VERSION "HNNBNNNYNNNNNNNNNNNNNNNNNNNNNNNNNNNNNNNNNN/4/%%%/4/'%**4NNN///"

NS_ :

BS_:

BU_: BAP_Tester Gateway_Max Getriebe_DQ Motor_konv Parksperre Schaltbetaetigung

BO_ 333 ACC_18: 32 Gateway_Max
 SG_ ACC_18_CRC : 0|8@1+ (1,0) [0|255] ""  Motor_konv
 SG_ ACC_18_BZ : 8|4@1+ (1,0) [0|15] ""  Motor_konv
 SG_ ACC_limitierte_Anfahrdyn : 12|1@1+ (1.0,0.0) [0.0|1] ""  Motor_konv
 SG_ ACC_nachtr_Stopp_Anf : 13|1@1+ (1.0,0.0) [0.0|1] ""  Motor_konv
 SG_ ACC_DynErhoehung : 14|1@1+ (1.0,0.0) [0.0|1] ""  Motor_konv
 SG_ ACC_Freilaufstrategie_TSK : 15|1@1+ (1.0,0.0) [0.0|1] ""  Motor_konv
 SG_ ACC_zul_Regelabw_unten : 16|6@1+ (0.024,0) [0.000|1.512] "Unit_MeterPerSeconSquar"  Motor_konv
 SG_ ACC_StartStopp_Info : 22|2@1+ (1.0,0.0) [0.0|3] ""  Motor_konv
 SG_ ACC_Sollbeschleunigung_02 : 24|11@1+ (0.005,-7.22) [-7.220|3.005] "Unit_MeterPerSeconSquar"  Getriebe_DQ,Motor_konv
 SG_ ACC_zul_Regelabw_oben : 35|5@1+ (0.0625,0) [0.0000|1.9375] "Unit_MeterPerSeconSquar"  Motor_konv
 SG_ ACC_neg_Sollbeschl_Grad_02 : 40|8@1+ (0.05,0) [0.00|12.75] "Unit_MeterPerCubicSecon"  Motor_konv
 SG_ ACC_pos_Sollbeschl_Grad_02 : 48|8@1+ (0.05,0) [0.00|12.75] "Unit_MeterPerCubicSecon"  Motor_konv
 SG_ ACC_Anfahren : 56|1@1+ (1.0,0.0) [0.0|1] ""  Getriebe_DQ,Motor_konv
 SG_ ACC_Anhalten : 57|1@1+ (1.0,0.0) [0.0|1] ""  Getriebe_DQ,Motor_konv
 SG_ ACC_Typ : 58|2@1+ (1.0,0.0) [0.0|3] ""  Motor_konv
 SG_ ACC_Status_ACC : 60|3@1+ (1.0,0.0) [0.0|7] ""  Getriebe_DQ,Motor_konv
 SG_ ACC_Minimale_Bremsung : 63|1@1+ (1.0,0.0) [0.0|1] ""  Motor_konv
 SG_ ACC_Anhalteweg : 64|11@1+ (0.01,0) [0.00|20.45] "Unit_Meter"  Vector__XXX
 SG_ ACC_Boost : 75|1@1+ (1.0,0.0) [0.0|1] ""  Vector__XXX
 SG_ ACC_Freilauf_Anf : 76|1@1+ (1.0,0.0) [0.0|1] ""  Vector__XXX
 SG_ ACC_Anforderung_HMS : 77|3@1+ (1.0,0.0) [0.0|7] ""  Vector__XXX
 SG_ ACC_Folgebeschl : 80|8@1+ (0.03,-4.6) [-4.60|2.99] "Unit_MeterPerSeconSquar"  Motor_konv
 SG_ ACC_Freilauf_Info : 88|2@1+ (1.0,0.0) [0.0|3] ""  Motor_konv
 SG_ ACC_Tempolimitassistent_Ein : 90|1@1+ (1.0,0.0) [0.0|1] ""  Vector__XXX
 SG_ ACC_FoD_Status : 91|2@1+ (1.0,0.0) [0.0|3] ""  Motor_konv
 SG_ ACC_Blindheit_erkannt : 93|1@1+ (1.0,0.0) [0.0|1] ""  Motor_konv
 SG_ ACC_Verkehrssinn : 94|2@1+ (1.0,0.0) [0.0|3] ""  Vector__XXX
 SG_ ACC_relev_Nichtverfuegbarkeit : 96|1@1+ (1.0,0.0) [0.0|1] ""  Motor_konv
 SG_ ACC_relevanter_Fehler : 97|1@1+ (1.0,0.0) [0.0|1] ""  Motor_konv
 SG_ ACC_TA_Kurve_Abstand : 98|6@1+ (5,0) [0|300] "Unit_Meter"  Vector__XXX
 SG_ ACC_TA_Kurve_vDelta : 104|4@1+ (5,0) [0|50] "Unit_KiloMeterPerHour"  Vector__XXX
 SG_ RDR_VBEG_Anforderung : 108|5@1+ (1,4) [5|35] "Unit_KiloMeterPerHour"  Motor_konv
 SG_ ACC_Abbiegewunsch : 113|2@1+ (1.0,0.0) [0.0|3] ""  Vector__XXX
 SG_ ACC_Abbiegewunsch_Abstand : 115|9@1+ (1,0) [0|510] "Unit_Meter"  Vector__XXX
 SG_ MPPmod_1_Segment : 208|6@1+ (1,0) [2|63] ""  Motor_konv
 SG_ MPPmod_2_Segment : 214|6@1+ (1,0) [2|63] ""  Motor_konv
 SG_ MPPmod_3_Segment : 220|6@1+ (1,0) [2|63] ""  Motor_konv
 SG_ MPPmod_4_Segment : 226|6@1+ (1,0) [2|63] ""  Motor_konv
 SG_ vESC_Verz_Anf : 232|4@1+ (0.5,0) [0.0|3.5] "Unit_MeterPerSeconSquar"  Vector__XXX
 SG_ RDR_v_ueber_Grund : 236|12@1+ (0.1,0) [0.0|409.0] "Unit_KiloMeterPerHour"  Vector__XXX
 SG_ RDR_v_ueber_Grund_Genauigkeit : 248|6@1+ (0.1,0) [0.0|6.0] "Unit_KiloMeterPerHour"  Vector__XXX
 SG_ RDR_v_ueber_Grund_Fahrtrichtung : 254|2@1+ (1.0,0.0) [0.0|3] ""  Vector__XXX

BO_ 859 ACC_Obj_01: 64 Gateway_Max
 SG_ ACC_Obj_01_ID : 12|8@1+ (1,0) [1|254] "Unit_None"  Vector__XXX
 SG_ ACC_Obj_01_ax_StdA : 20|6@1+ (0.125,0) [0.000|7.750] "Unit_MeterPerSeconSquar"  Motor_konv
 SG_ ACC_Obj_01_ax_v : 26|8@1+ (0.125,-16) [-16.000|15.750] "Unit_MeterPerSeconSquar"  Motor_konv
 SG_ ACC_Obj_01_dx_StdA : 34|7@1+ (0.0625,0) [0.0000|7.8750] "Unit_Meter"  Vector__XXX
 SG_ ACC_Obj_01_dx_v : 41|12@1+ (0.0625,0) [0.0000|255.8750] "Unit_Meter"  Motor_konv
 SG_ ACC_Obj_01_dy_StdA : 53|7@1+ (0.0625,0) [0.0000|7.8750] "Unit_Meter"  Motor_konv
 SG_ ACC_Obj_01_dy_v : 60|11@1+ (0.0625,-64) [-64.0000|63.8750] "Unit_Meter"  Motor_konv
 SG_ ACC_Obj_01_vx_StdA : 71|5@1+ (0.25,0) [0.00|7.50] "Unit_MeterPerSecon"  Vector__XXX
 SG_ ACC_Obj_01_vx_v : 76|10@1+ (0.25,-128) [-128.00|127.50] "Unit_MeterPerSecon"  Motor_konv
 SG_ ACC_Obj_01_Bew_Zustand : 86|2@1+ (1.0,0.0) [0.0|3] ""  Vector__XXX
 SG_ ACC_Obj_01_Fusion_ID_VD : 88|32@1+ (1,0) [1|4294967294] "Unit_Ohm"  Vector__XXX
 SG_ ACC_Obj_01_Fusion_ID_FER_VR : 120|8@1+ (1,0) [1|254] "Unit_None"  Vector__XXX
 SG_ ACC_Obj_01_Fusion_ID_FER_VL : 128|8@1+ (1,0) [1|254] "Unit_None"  Vector__XXX
 SG_ ACC_Obj_01_Alter : 136|12@1+ (1,0) [0|4094] "Unit_None"  Vector__XXX
 SG_ ACC_Obj_01_vxAbs_v : 148|12@1+ (0.0625,-128) [-128.0000|127.8750] "Unit_MeterPerSecon"  Vector__XXX
 SG_ ACC_Obj_01_vyAbs_v : 160|12@1+ (0.0625,-128) [-128.0000|127.8750] "Unit_MeterPerSecon"  Vector__XXX
 SG_ ACC_Obj_01_Bezugspunkt : 172|4@1+ (1.0,0.0) [0.0|15] ""  Vector__XXX
 SG_ ACC_Obj_01_Breite : 176|7@1+ (0.0625,0) [0.0000|7.8750] "Unit_Meter"  Vector__XXX
 SG_ ACC_Obj_01_SDFInfo_FER_VL : 183|1@1+ (1.0,0.0) [0.0|1] ""  Vector__XXX
 SG_ ACC_Obj_01_BreiteStdA : 184|7@1+ (0.0625,0) [0.0000|7.8750] "Unit_Meter"  Vector__XXX
 SG_ ACC_Obj_01_SDFInfo_FER_VR : 191|1@1+ (1.0,0.0) [0.0|1] ""  Vector__XXX
 SG_ ACC_Obj_01_Historie : 192|1@1+ (1.0,0.0) [0.0|1] ""  Vector__XXX
 SG_ ACC_Obj_01_SDFInfo_FR : 193|1@1+ (1.0,0.0) [0.0|1] ""  Vector__XXX
 SG_ ACC_Obj_01_SDFInfo_Kamera : 194|1@1+ (1.0,0.0) [0.0|1] ""  Vector__XXX
 SG_ ACC_Obj_01_vy_StdA : 195|5@1+ (0.25,0) [0.00|7.50] "Unit_MeterPerSecon"  Vector__XXX
 SG_ ACC_Obj_01_dz_v : 200|9@1+ (0.0625,-16) [-16.0000|15.8750] "Unit_Meter"  Vector__XXX
 SG_ ACC_Obj_01_dz_StdA : 209|7@1+ (0.0625,0) [0.0000|7.8750] "Unit_Meter"  Vector__XXX
 SG_ ACC_Obj_01_Laenge : 216|9@1+ (0.0625,0) [0.0000|31.8750] "Unit_Meter"  Vector__XXX
 SG_ ACC_Obj_01_LaengeStdA : 225|7@1+ (0.0625,0) [0.0000|7.8750] "Unit_Meter"  Vector__XXX
 SG_ ACC_Obj_01_GierWnkl : 232|9@1+ (0.0125,-3.2) [-3.2000|3.1750] "Unit_Radia"  Vector__XXX
 SG_ ACC_Obj_01_ExistenzMass : 241|7@1+ (0.0078125,0.015625) [0.0156250|1.0000000] "Unit_None"  Vector__XXX
 SG_ ACC_Obj_01_axAbs_v : 248|8@1+ (0.125,-16) [-16.000|15.750] "Unit_MeterPerSeconSquar"  Vector__XXX
 SG_ ACC_Obj_01_ay_v : 256|8@1+ (0.125,-16) [-16.000|15.750] "Unit_MeterPerSeconSquar"  Vector__XXX
 SG_ ACC_Obj_01_vy_v : 264|8@1+ (0.25,-32) [-32.00|31.50] "Unit_MeterPerSecon"  Vector__XXX
 SG_ ACC_Obj_01_Klasse : 272|4@1+ (1.0,0.0) [0.0|15] ""  Vector__XXX
 SG_ ACC_Obj_01_KlassePlausib : 276|4@1+ (0.071429,0) [0.000000|1.000006] "Unit_None"  Vector__XXX
 SG_ ACC_Obj_01_Gemessen : 280|2@1+ (1.0,0.0) [0.0|3] ""  Vector__XXX
 SG_ ACC_Obj_01_Hoehe : 282|6@1+ (0.0625,0) [0.0000|3.8750] "Unit_Meter"  Vector__XXX
 SG_ ACC_Obj_01_HoeheStdA : 288|6@1+ (0.0625,0) [0.0000|3.8750] "Unit_Meter"  Vector__XXX
 SG_ ACC_Obj_01_vxAbs_StdA : 294|6@1+ (0.0625,0) [0.0000|3.8750] "Unit_MeterPerSecon"  Vector__XXX
 SG_ ACC_Obj_01_vyAbs_StdA : 300|6@1+ (0.0625,0) [0.0000|3.8750] "Unit_MeterPerSecon"  Vector__XXX
 SG_ ACC_Obj_01_axAbs_StdA : 306|6@1+ (0.125,0) [0.000|7.750] "Unit_MeterPerSeconSquar"  Vector__XXX
 SG_ ACC_Obj_01_ay_StdA : 312|6@1+ (0.125,0) [0.000|7.750] "Unit_MeterPerSeconSquar"  Vector__XXX
 SG_ ACC_Obj_01_GierWnklStdA : 318|6@1+ (0.0625,0) [0.0000|3.8750] "Unit_Radia"  Vector__XXX
 SG_ ACC_Obj_01_Anzeige_Rel : 324|2@1+ (1.0,0.0) [0.0|3] ""  Vector__XXX
 SG_ ACC_Obj_01_LaengsRegelung : 326|1@1+ (1.0,0.0) [0.0|1] ""  Vector__XXX

BO_ 860 ACC_Obj_04: 64 Gateway_Max
 SG_ ACC_Obj_04_ID : 12|8@1+ (1,0) [1|254] "Unit_None"  Vector__XXX
 SG_ ACC_Obj_04_ax_StdA : 20|6@1+ (0.125,0) [0.000|7.750] ""  Vector__XXX
 SG_ ACC_Obj_04_ax_v : 26|8@1+ (0.125,-16) [-16.000|15.750] ""  Vector__XXX
 SG_ ACC_Obj_04_dx_StdA : 34|7@1+ (0.0625,0) [0.0000|7.8750] "Unit_Meter"  Vector__XXX
 SG_ ACC_Obj_04_dx_v : 41|12@1+ (0.0625,0) [0.0000|255.8750] "Unit_Meter"  Motor_konv
 SG_ ACC_Obj_04_dy_StdA : 53|7@1+ (0.0625,0) [0.0000|7.8750] "Unit_Meter"  Vector__XXX
 SG_ ACC_Obj_04_dy_v : 60|11@1+ (0.0625,-64) [-64.0000|63.8750] "Unit_Meter"  Vector__XXX
 SG_ ACC_Obj_04_vx_StdA : 71|5@1+ (0.25,0) [0.00|7.50] "Unit_MeterPerSecon"  Vector__XXX
 SG_ ACC_Obj_04_vx_v : 76|10@1+ (0.25,-128) [-128.00|127.50] "Unit_MeterPerSecon"  Motor_konv
 SG_ ACC_Obj_04_Bew_Zustand : 86|2@1+ (1.0,0.0) [0.0|3] ""  Vector__XXX
 SG_ ACC_Obj_04_Fusion_ID_VD : 88|32@1+ (1,0) [1|4294967294] ""  Vector__XXX
 SG_ ACC_Obj_04_Fusion_ID_FER_VR : 120|8@1+ (1,0) [1|254] ""  Vector__XXX
 SG_ ACC_Obj_04_Fusion_ID_FER_VL : 128|8@1+ (1,0) [1|254] ""  Vector__XXX
 SG_ ACC_Obj_04_Alter : 136|12@1+ (1,0) [0|4094] ""  Vector__XXX
 SG_ ACC_Obj_04_vxAbs_v : 148|12@1+ (0.0625,-128) [-128.0000|127.8750] ""  Vector__XXX
 SG_ ACC_Obj_04_vyAbs_v : 160|12@1+ (0.0625,-128) [-128.0000|127.8750] ""  Vector__XXX
 SG_ ACC_Obj_04_Bezugspunkt : 172|4@1+ (1.0,0.0) [0.0|15] ""  Vector__XXX
 SG_ ACC_Obj_04_Breite : 176|7@1+ (0.0625,0) [0.0000|7.8750] ""  Vector__XXX
 SG_ ACC_Obj_04_SDFInfo_FER_VL : 183|1@1+ (1.0,0.0) [0.0|1] ""  Vector__XXX
 SG_ ACC_Obj_04_BreiteStdA : 184|7@1+ (0.0625,0) [0.0000|7.8750] ""  Vector__XXX
 SG_ ACC_Obj_04_SDFInfo_FER_VR : 191|1@1+ (1.0,0.0) [0.0|1] ""  Vector__XXX
 SG_ ACC_Obj_04_Historie : 192|1@1+ (1.0,0.0) [0.0|1] ""  Vector__XXX
 SG_ ACC_Obj_04_SDFInfo_FR : 193|1@1+ (1.0,0.0) [0.0|1] ""  Vector__XXX
 SG_ ACC_Obj_04_SDFInfo_Kamera : 194|1@1+ (1.0,0.0) [0.0|1] ""  Vector__XXX
 SG_ ACC_Obj_04_vy_StdA : 195|5@1+ (0.25,0) [0.00|7.50] ""  Vector__XXX
 SG_ ACC_Obj_04_dz_v : 200|9@1+ (0.0625,-16) [-16.0000|15.8750] ""  Vector__XXX
 SG_ ACC_Obj_04_dz_StdA : 209|7@1+ (0.0625,0) [0.0000|7.8750] ""  Vector__XXX
 SG_ ACC_Obj_04_Laenge : 216|9@1+ (0.0625,0) [0.0000|31.8750] ""  Vector__XXX
 SG_ ACC_Obj_04_LaengeStdA : 225|7@1+ (0.0625,0) [0.0000|7.8750] ""  Vector__XXX
 SG_ ACC_Obj_04_GierWnkl : 232|9@1+ (0.0125,-3.2) [-3.2000|3.1750] ""  Vector__XXX
 SG_ ACC_Obj_04_ExistenzMass : 241|7@1+ (0.0078125,0.015625) [0.0156250|1.0000000] ""  Vector__XXX
 SG_ ACC_Obj_04_axAbs_v : 248|8@1+ (0.125,-16) [-16.000|15.750] "Unit_MeterPerSeconSquar"  Vector__XXX
 SG_ ACC_Obj_04_ay_v : 256|8@1+ (0.125,-16) [-16.000|15.750] ""  Vector__XXX
 SG_ ACC_Obj_04_vy_v : 264|8@1+ (0.25,-32) [-32.00|31.50] ""  Vector__XXX
 SG_ ACC_Obj_04_Klasse : 272|4@1+ (1.0,0.0) [0.0|15] ""  Vector__XXX
 SG_ ACC_Obj_04_KlassePlausib : 276|4@1+ (0.071429,0) [0.000000|1.000006] "Unit_None"  Vector__XXX
 SG_ ACC_Obj_04_Gemessen : 280|2@1+ (1.0,0.0) [0.0|3] ""  Vector__XXX
 SG_ ACC_Obj_04_Hoehe : 282|6@1+ (0.0625,0) [0.0000|3.8750] ""  Vector__XXX
 SG_ ACC_Obj_04_HoeheStdA : 288|6@1+ (0.0625,0) [0.0000|3.8750] ""  Vector__XXX
 SG_ ACC_Obj_04_vxAbs_StdA : 294|6@1+ (0.0625,0) [0.0000|3.8750] ""  Vector__XXX
 SG_ ACC_Obj_04_vyAbs_StdA : 300|6@1+ (0.0625,0) [0.0000|3.8750] ""  Vector__XXX
 SG_ ACC_Obj_04_axAbs_StdA : 306|6@1+ (0.125,0) [0.000|7.750] "Unit_MeterPerSeconSquar"  Vector__XXX
 SG_ ACC_Obj_04_ay_StdA : 312|6@1+ (0.125,0) [0.000|7.750] ""  Vector__XXX
 SG_ ACC_Obj_04_GierWnklStdA : 318|6@1+ (0.0625,0) [0.0000|3.8750] ""  Vector__XXX
 SG_ ACC_Obj_04_Anzeige_Rel : 324|2@1+ (1.0,0.0) [0.0|3] ""  Vector__XXX
 SG_ ACC_Obj_04_LaengsRegelung : 326|1@1+ (1.0,0.0) [0.0|1] ""  Vector__XXX

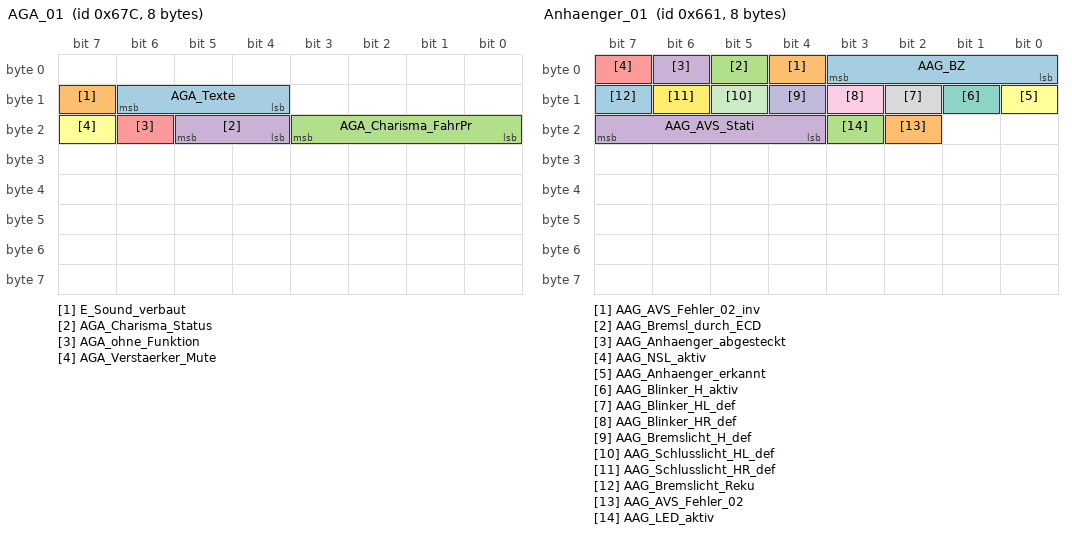
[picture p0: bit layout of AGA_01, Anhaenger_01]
BO_ 1660 AGA_01: 8 Vector__XXX
 SG_ AGA_Texte : 12|3@1+ (1.0,0.0) [0.0|7] ""  Gateway_Max
 SG_ E_Sound_verbaut : 15|1@1+ (1.0,0.0) [0.0|1] ""  Gateway_Max
 SG_ AGA_Charisma_FahrPr : 16|4@1+ (1.0,0.0) [0.0|15] ""  Gateway_Max
 SG_ AGA_Charisma_Status : 20|2@1+ (1.0,0.0) [0.0|3] ""  Gateway_Max
 SG_ AGA_ohne_Funktion : 22|1@1+ (1.0,0.0) [0.0|1] ""  Gateway_Max
 SG_ AGA_Verstaerker_Mute : 23|1@1+ (1.0,0.0) [0.0|1] ""  Gateway_Max

BO_ 64 Airbag_01: 8 Gateway_Max
 SG_ Airbag_01_CRC : 0|8@1+ (1,0) [0|255] ""  Motor_konv
 SG_ Airbag_01_BZ : 8|4@1+ (1,0) [0|15] ""  Motor_konv
 SG_ AB_RGS_Anst : 12|4@1+ (1.0,0.0) [0.0|15] ""  Vector__XXX
 SG_ AB_Front_Crash : 16|1@1+ (1.0,0.0) [0.0|1] ""  Vector__XXX
 SG_ AB_Heck_Crash : 17|1@1+ (1.0,0.0) [0.0|1] ""  Vector__XXX
 SG_ AB_SF_Crash : 18|1@1+ (1.0,0.0) [0.0|1] ""  Vector__XXX
 SG_ AB_SB_Crash : 19|1@1+ (1.0,0.0) [0.0|1] ""  Vector__XXX
 SG_ AB_Rollover_Crash : 20|1@1+ (1.0,0.0) [0.0|1] ""  Vector__XXX
 SG_ AB_Crash_Int : 21|3@1+ (1.0,0.0) [0.0|7] ""  Getriebe_DQ,Motor_konv
 SG_ AB_Lampe : 24|1@1+ (1.0,0.0) [0.0|1] ""  Vector__XXX
 SG_ AB_Deaktiviert : 25|1@1+ (1.0,0.0) [0.0|1] ""  Vector__XXX
 SG_ AB_VB_deaktiviert : 26|1@1+ (1.0,0.0) [0.0|1] ""  Vector__XXX
 SG_ AB_Systemfehler : 27|1@1+ (1.0,0.0) [0.0|1] ""  Vector__XXX
 SG_ AB_Diagnose : 28|1@1+ (1.0,0.0) [0.0|1] ""  Vector__XXX
 SG_ AB_Stellgliedtest : 29|1@1+ (1.0,0.0) [0.0|1] ""  Motor_konv
 SG_ AB_Erh_Auf_VB : 30|2@1+ (1.0,0.0) [0.0|3] ""  Vector__XXX
 SG_ AB_Gurtwarn_VF : 32|1@1+ (1.0,0.0) [0.0|1] ""  Vector__XXX
 SG_ AB_Gurtwarn_VB : 33|1@1+ (1.0,0.0) [0.0|1] ""  Vector__XXX
 SG_ AB_Anzeige_Fussg : 34|2@1+ (1.0,0.0) [0.0|3] ""  Vector__XXX
 SG_ AB_Texte_AKS : 36|2@1+ (1.0,0.0) [0.0|3] ""  Vector__XXX
 SG_ AB_PAO_Leuchte_Anf : 38|1@1+ (1.0,0.0) [0.0|1] ""  Vector__XXX
 SG_ AB_MKB_gueltig : 39|1@1+ (1.0,0.0) [0.0|1] ""  Vector__XXX
 SG_ AB_MKB_Anforderung : 40|1@1+ (1.0,0.0) [0.0|1] ""  Vector__XXX
 SG_ AB_Versorgungsspannung : 41|1@1+ (1.0,0.0) [0.0|1] ""  Vector__XXX
 SG_ AB_Deaktivierung_HV : 42|3@1+ (1.0,0.0) [0.0|7] ""  Vector__XXX
 SG_ AB_EDR_Trigger : 45|2@1+ (1.0,0.0) [0.0|3] ""  Vector__XXX
 SG_ AB_Belegung_VF : 47|2@1+ (1.0,0.0) [0.0|3] ""  Vector__XXX
 SG_ AB_Gurtschloss_FA_ext : 49|3@1+ (1.0,0.0) [0.0|7] ""  Motor_konv
 SG_ AB_Gurtschloss_FA_ext_aktiv : 52|1@1+ (1.0,0.0) [0.0|1] ""  Vector__XXX
 SG_ AB_eCS_Error : 53|1@1+ (1.0,0.0) [0.0|1] ""  Vector__XXX
 SG_ ASM_Masterzeit_02 : 56|8@1+ (0.04,0) [0.00|10.16] "Unit_Secon"  Vector__XXX

BO_ 1312 Airbag_02: 8 Gateway_Max
 SG_ Airbag_02_CRC : 0|8@1+ (1,0) [0|255] ""  Motor_konv
 SG_ Airbag_02_BZ : 8|4@1+ (1,0) [0|15] ""  Motor_konv
 SG_ LoGeWa_Event_Kombiwarnung : 12|4@1+ (1.0,0.0) [0.0|15] ""  Vector__XXX
 SG_ AB_Anforderung_eCall : 16|1@1+ (1.0,0.0) [0.0|1] ""  Vector__XXX
 SG_ AB_Anprall_Seite_Beifahrer : 17|1@1+ (1.0,0.0) [0.0|1] ""  Vector__XXX
 SG_ AB_Anprall_Rollover : 18|1@1+ (1.0,0.0) [0.0|1] ""  Vector__XXX
 SG_ AB_Anprall_FGS : 19|1@1+ (1.0,0.0) [0.0|1] ""  Vector__XXX
 SG_ AB_Anprall_Front_Beifahrer : 20|1@1+ (1.0,0.0) [0.0|1] ""  Vector__XXX
 SG_ AB_Anprall_Front_Fahrer : 21|1@1+ (1.0,0.0) [0.0|1] ""  Vector__XXX
 SG_ AB_Anprall_Heck_Beifahrer : 22|1@1+ (1.0,0.0) [0.0|1] ""  Vector__XXX
 SG_ AB_Anprall_Heck_Fahrer : 23|1@1+ (1.0,0.0) [0.0|1] ""  Vector__XXX
 SG_ AB_Wickelklappung_Reihe2_MI : 24|2@1+ (1.0,0.0) [0.0|3] ""  Vector__XXX
 SG_ AB_Belegung_VB : 26|2@1+ (1.0,0.0) [0.0|3] ""  Vector__XXX
 SG_ AB_Abschaltanf_SIH_BF : 28|1@1+ (1.0,0.0) [0.0|1] ""  Vector__XXX
 SG_ AB_Anprall_Seite_Fahrer : 29|1@1+ (1.0,0.0) [0.0|1] ""  Vector__XXX
 SG_ SC_PAO_Schriftzug_Anf : 30|2@1+ (1.0,0.0) [0.0|3] ""  Vector__XXX
 SG_ SC_PAO_ON_Anf : 32|2@1+ (1.0,0.0) [0.0|3] ""  Vector__XXX
 SG_ SC_PAO_OFF_Anf : 34|2@1+ (1.0,0.0) [0.0|3] ""  Vector__XXX
 SG_ AB_Crashschwere : 36|3@1+ (1.0,0.0) [0.0|7] ""  Vector__XXX
 SG_ AB_Anforderung_USM : 39|1@1+ (1.0,0.0) [0.0|1] ""  Vector__XXX
 SG_ AB_Gurtschloss_FA : 40|2@1+ (1.0,0.0) [0.0|3] ""  Motor_konv
 SG_ AB_Gurtschloss_BF : 42|2@1+ (1.0,0.0) [0.0|3] ""  Vector__XXX
 SG_ AB_Gurtschloss_Reihe2_FA : 44|2@1+ (1.0,0.0) [0.0|3] ""  Vector__XXX
 SG_ AB_Gurtschloss_Reihe2_MI : 46|2@1+ (1.0,0.0) [0.0|3] ""  Vector__XXX
 SG_ AB_Gurtschloss_Reihe2_BF : 48|2@1+ (1.0,0.0) [0.0|3] ""  Vector__XXX
 SG_ AB_Gurtschloss_Reihe3_FA : 50|2@1+ (1.0,0.0) [0.0|3] ""  Vector__XXX
 SG_ AB_Gurtschloss_Reihe3_MI : 52|2@1+ (1.0,0.0) [0.0|3] ""  Vector__XXX
 SG_ AB_Gurtschloss_Reihe3_BF : 54|2@1+ (1.0,0.0) [0.0|3] ""  Vector__XXX
 SG_ AB_Sitzpos_Sens_FA : 56|2@1+ (1.0,0.0) [0.0|3] ""  Vector__XXX
 SG_ AB_Sitzpos_Sens_BF : 58|2@1+ (1.0,0.0) [0.0|3] ""  Vector__XXX
 SG_ AB_Wickelklappung_Reihe2_BF : 60|2@1+ (1.0,0.0) [0.0|3] ""  Vector__XXX
 SG_ AB_Wickelklappung_Reihe2_FA : 62|2@1+ (1.0,0.0) [0.0|3] ""  Vector__XXX

BO_ 1349 Airbag_04: 8 Gateway_Max
 SG_ Airbag_04_CRC : 0|8@1+ (1,0) [0|255] ""  Motor_konv
 SG_ Airbag_04_BZ : 8|4@1+ (1,0) [0|15] ""  Motor_konv
 SG_ AB_Anprall_Front : 12|1@1+ (1.0,0.0) [0.0|1] ""  Vector__XXX
 SG_ AB_Anprall_Heck : 13|1@1+ (1.0,0.0) [0.0|1] ""  Vector__XXX
 SG_ AB_Gurtwarn_Reihe4_FA : 14|2@1+ (1.0,0.0) [0.0|3] ""  Vector__XXX
 SG_ AB_Gurtwarn_Reihe4_BF : 16|2@1+ (1.0,0.0) [0.0|3] ""  Vector__XXX
 SG_ AB_Gurtwarn_Reihe4_MI : 18|2@1+ (1.0,0.0) [0.0|3] ""  Vector__XXX
 SG_ AB_Gurtwarn_Reihe2_FA : 20|2@1+ (1.0,0.0) [0.0|3] ""  Vector__XXX
 SG_ AB_Gurtwarn_Reihe2_BF : 22|2@1+ (1.0,0.0) [0.0|3] ""  Vector__XXX
 SG_ AbstWarn_MV_FAS_Fkt_Status : 24|2@1+ (1.0,0.0) [0.0|3] ""  Vector__XXX
 SG_ WarnBrems_Charisma_Status : 26|2@1+ (1.0,0.0) [0.0|3] ""  Vector__XXX
 SG_ WarnBrems_Charisma_FahrPr : 28|4@1+ (1.0,0.0) [0.0|15] ""  Vector__XXX
 SG_ AB_Gurtwarn_Reihe2_MI : 32|2@1+ (1.0,0.0) [0.0|3] ""  Vector__XXX
 SG_ AB_Gurtwarn_Reihe3_FA : 34|2@1+ (1.0,0.0) [0.0|3] ""  Vector__XXX
 SG_ AB_Gurtwarn_Reihe3_MI : 36|2@1+ (1.0,0.0) [0.0|3] ""  Vector__XXX
 SG_ AB_Gurtwarn_Reihe3_BF : 38|2@1+ (1.0,0.0) [0.0|3] ""  Vector__XXX
 SG_ LGI_FAS_Fkt_Status : 40|2@1+ (1.0,0.0) [0.0|3] ""  Vector__XXX
 SG_ PreCrash_FAS_Fkt_Status : 42|3@1+ (1.0,0.0) [0.0|7] ""  Vector__XXX
 SG_ AB_Belegung_VF_ext : 45|3@1+ (1.0,0.0) [0.0|7] ""  Motor_konv
 SG_ AB_SBR_hinten_verbau : 48|2@1+ (1.0,0.0) [0.0|3] ""  Vector__XXX
 SG_ AB_Belegung_VF_ext_aktiv : 50|1@1+ (1.0,0.0) [0.0|1] ""  Vector__XXX
 SG_ AWV_Einstellung_System_ASG : 51|1@1+ (1.0,0.0) [0.0|1] ""  Vector__XXX
 SG_ AWV_Einstellung_Warnung_ASG : 52|3@1+ (1.0,0.0) [0.0|7] ""  Vector__XXX
 SG_ SC_PreSense_Modus_Warnung_NV : 55|3@1+ (1.0,0.0) [0.0|7] ""  Vector__XXX
 SG_ SC_PreSense_Modus_Warnung_MV : 58|3@1+ (1.0,0.0) [0.0|7] ""  Vector__XXX
 SG_ SC_PreSense_Modus_System_MV : 61|1@1+ (1.0,0.0) [0.0|1] ""  Vector__XXX
 SG_ SC_PreSense_Modus_System_NV : 62|1@1+ (1.0,0.0) [0.0|1] ""  Vector__XXX
 SG_ SC_PreSense_Modus_System_KAS : 63|1@1+ (1.0,0.0) [0.0|1] ""  Vector__XXX

BO_ 1633 Anhaenger_01: 8 Gateway_Max
 SG_ AAG_BZ : 0|4@1+ (1,0) [0|15] ""  Vector__XXX
 SG_ AAG_AVS_Fehler_02_inv : 4|1@1+ (1.0,0.0) [0.0|1] ""  Vector__XXX
 SG_ AAG_Bremsl_durch_ECD : 5|1@1+ (1.0,0.0) [0.0|1] ""  Motor_konv
 SG_ AAG_Anhaenger_abgesteckt : 6|1@1+ (1.0,0.0) [0.0|1] ""  Vector__XXX
 SG_ AAG_NSL_aktiv : 7|1@1+ (1.0,0.0) [0.0|1] ""  Vector__XXX
 SG_ AAG_Anhaenger_erkannt : 8|1@1+ (1.0,0.0) [0.0|1] ""  Getriebe_DQ,Motor_konv
 SG_ AAG_Blinker_H_aktiv : 9|1@1+ (1.0,0.0) [0.0|1] ""  Vector__XXX
 SG_ AAG_Blinker_HL_def : 10|1@1+ (1.0,0.0) [0.0|1] ""  Vector__XXX
 SG_ AAG_Blinker_HR_def : 11|1@1+ (1.0,0.0) [0.0|1] ""  Vector__XXX
 SG_ AAG_Bremslicht_H_def : 12|1@1+ (1.0,0.0) [0.0|1] ""  Motor_konv
 SG_ AAG_Schlusslicht_HL_def : 13|1@1+ (1.0,0.0) [0.0|1] ""  Vector__XXX
 SG_ AAG_Schlusslicht_HR_def : 14|1@1+ (1.0,0.0) [0.0|1] ""  Vector__XXX
 SG_ AAG_Bremslicht_Reku : 15|1@1+ (1.0,0.0) [0.0|1] ""  Vector__XXX
 SG_ AAG_AVS_Fehler_02 : 18|1@1+ (1.0,0.0) [0.0|1] ""  Vector__XXX
 SG_ AAG_LED_aktiv : 19|1@1+ (1.0,0.0) [0.0|1] ""  Vector__XXX
 SG_ AAG_AVS_Stati : 20|4@1+ (1.0,0.0) [0.0|15] ""  Vector__XXX

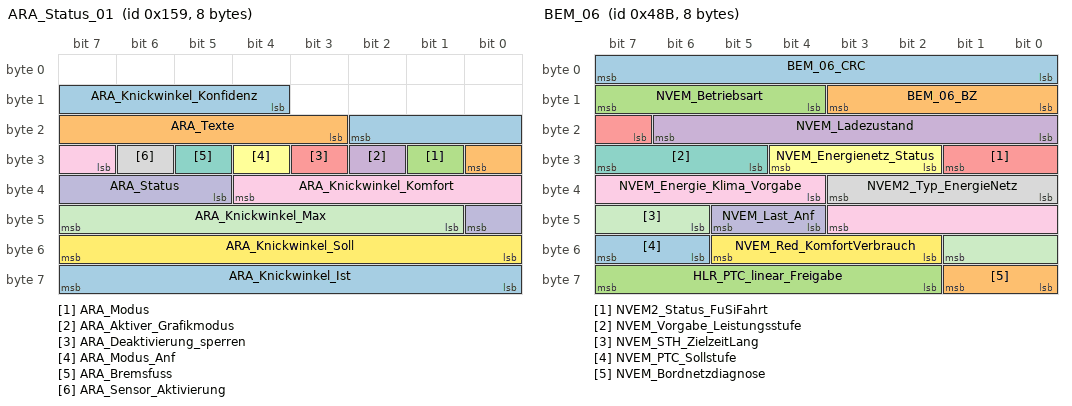
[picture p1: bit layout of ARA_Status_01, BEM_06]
BO_ 345 ARA_Status_01: 8 Gateway_Max
 SG_ ARA_Knickwinkel_Konfidenz : 12|7@1+ (1,0) [0|120] "Unit_DegreOfArc"  Vector__XXX
 SG_ ARA_Texte : 19|6@1+ (1.0,0.0) [0.0|63] ""  Vector__XXX
 SG_ ARA_Modus : 25|1@1+ (1.0,0.0) [0.0|1] ""  Vector__XXX
 SG_ ARA_Aktiver_Grafikmodus : 26|1@1+ (1.0,0.0) [0.0|1] ""  Vector__XXX
 SG_ ARA_Deaktivierung_sperren : 27|1@1+ (1.0,0.0) [0.0|1] ""  Vector__XXX
 SG_ ARA_Modus_Anf : 28|1@1+ (1.0,0.0) [0.0|1] ""  Vector__XXX
 SG_ ARA_Bremsfuss : 29|1@1+ (1.0,0.0) [0.0|1] ""  Vector__XXX
 SG_ ARA_Sensor_Aktivierung : 30|1@1+ (1.0,0.0) [0.0|1] ""  Vector__XXX
 SG_ ARA_Knickwinkel_Komfort : 31|6@1+ (1,0) [0|60] "Unit_DegreOfArc"  Vector__XXX
 SG_ ARA_Status : 37|4@1+ (1.0,0.0) [0.0|15] ""  Motor_konv
 SG_ ARA_Knickwinkel_Max : 41|7@1+ (1,0) [0|120] "Unit_DegreOfArc"  Vector__XXX
 SG_ ARA_Knickwinkel_Soll : 48|8@1+ (1,-125) [-125|126] "Unit_DegreOfArc"  Vector__XXX
 SG_ ARA_Knickwinkel_Ist : 56|8@1+ (1,-125) [-125|126] "Unit_DegreOfArc"  Vector__XXX

BO_ 2536767264 BAP_Debug_Cmd: 8 BAP_Tester
 SG_ BAP_Debug_Cmd : 0|16@1+ (1.0,0.0) [0.0|65535] ""  Gateway_Max,Motor_konv

BO_ 2536767280 BAP_Debug_Data: 8 Gateway_Max
 SG_ BAP_Debug_Data : 0|64@1+ (1.0,0.0) [0.0|18446744073709551615] ""  BAP_Tester

BO_ 2536734208 BAP_DrivingDynamics_ASG_01: 8 Gateway_Max
 SG_ BAP_DrivingDynamics_ASG_01_Hdr : 0|64@1+ (1.0,0.0) [0.0|18446744073709551615] ""  Vector__XXX

BO_ 2536734224 BAP_DrivingDynamics_FSG_01: 8 Vector__XXX
 SG_ BAP_DrivingDynamics_FSG_01_Hdr : 0|64@1+ (1.0,0.0) [0.0|18446744073709551615] ""  Gateway_Max

BO_ 2536717312 BAP_EfficiencyAssist_ASG_01: 8 Gateway_Max
 SG_ BAP_EfficAssist_ASG_01_Header : 0|8@1+ (1.0,0.0) [0.0|255] ""  Motor_konv

BO_ 2536717313 BAP_EfficiencyAssist_ASG_02: 8 Gateway_Max
 SG_ BAP_EfficAssist_ASG_02_Header : 0|64@1+ (1.0,0.0) [0.0|18446744073709551615] ""  Motor_konv

BO_ 2536717328 BAP_EfficiencyAssist_FSG_01: 8 Motor_konv
 SG_ BAP_EfficAssist_FSG_01_Header : 0|8@1+ (1.0,0.0) [0.0|255] ""  Gateway_Max

BO_ 2536725760 BAP_EngFunctions_ASG_01: 8 Gateway_Max
 SG_ BAP_EngFunctions_ASG_01_Header : 0|8@1+ (1,0) [0|255] "Unit_None"  Motor_konv

BO_ 2536725776 BAP_EngFunctions_FSG_01: 8 Motor_konv
 SG_ BAP_EngFunctions_FSG_01_Header : 0|8@1+ (1,0) [0|255] "Unit_None"  Gateway_Max

BO_ 2536709120 BAP_Hybrid_ASG_01: 8 Gateway_Max
 SG_ BAP_Hybrid_ASG_01_Header : 0|8@1+ (1.0,0.0) [0.0|255] ""  Vector__XXX

BO_ 2536709121 BAP_Hybrid_ASG_02: 8 Gateway_Max
 SG_ BAP_Hybrid_ASG_02_Header : 0|8@1+ (1.0,0.0) [0.0|255] ""  Vector__XXX

BO_ 2536709136 BAP_Hybrid_FSG_01: 8 Vector__XXX
 SG_ BAP_Hybrid_FSG_01_Header : 0|8@1+ (1.0,0.0) [0.0|255] ""  Gateway_Max

BO_ 2536716545 BAP_RangeData_ASG_02: 8 Vector__XXX
 SG_ BAP_RangeData_ASG_02_Header : 0|8@1+ (1.0,0.0) [0.0|255] ""  Gateway_Max

BO_ 2536716560 BAP_RangeData_FSG_01: 8 Gateway_Max
 SG_ BAP_RangeData_FSG_01_Header : 0|8@1+ (1.0,0.0) [0.0|255] ""  Vector__XXX

BO_ 1626 BCM_01: 8 Gateway_Max
 SG_ BCM_Bremsbelag_Sensor : 12|1@1+ (1.0,0.0) [0.0|1] ""  Vector__XXX
 SG_ BCM_Bremsfluessigkeit_Sensor : 13|1@1+ (1.0,0.0) [0.0|1] ""  Vector__XXX
 SG_ BCM1_Licht_Warn : 14|1@1+ (1.0,0.0) [0.0|1] ""  Vector__XXX
 SG_ BCM_Waschwasser_Sensor : 15|1@1+ (1.0,0.0) [0.0|1] ""  Vector__XXX
 SG_ BCM_Kuehlmittel_Sensor : 16|1@1+ (1.0,0.0) [0.0|1] ""  Motor_konv
 SG_ BCM1_Kl_15_HW_erkannt : 17|1@1+ (1.0,0.0) [0.0|1] ""  Vector__XXX
 SG_ BCM1_Kl_15_Sig_HW_erkannt : 18|1@1+ (1.0,0.0) [0.0|1] ""  Vector__XXX
 SG_ BCM_Kuehlmittel_Sensor_02 : 19|1@1+ (1.0,0.0) [0.0|1] ""  Vector__XXX
 SG_ BCM1_Hinweis_Lichtnachlauf : 20|1@1+ (1.0,0.0) [0.0|1] ""  Vector__XXX
 SG_ BCM_Offroad_Taste : 21|1@1+ (1.0,0.0) [0.0|1] ""  Motor_konv
 SG_ BCM_Charisma_Taste2 : 22|1@1+ (1.0,0.0) [0.0|1] ""  Vector__XXX
 SG_ BCM_Hybrid_StSt_Taste_Fehler : 23|1@1+ (1.0,0.0) [0.0|1] ""  Vector__XXX
 SG_ BCM_Hybrid_StartStopp_Taste : 24|1@1+ (1.0,0.0) [0.0|1] ""  Motor_konv
 SG_ BCM1_Warnblink_Taster : 25|1@1+ (1.0,0.0) [0.0|1] ""  Vector__XXX
 SG_ BCM1_Valet_Parking_Taster : 26|1@1+ (1.0,0.0) [0.0|1] ""  Vector__XXX
 SG_ BCM1_LDS_Stellung : 27|3@1+ (1.0,0.0) [0.0|7] ""  Vector__XXX
 SG_ BCM1_Rueckfahrlicht_Schalter : 30|1@1+ (1.0,0.0) [0.0|1] ""  Motor_konv
 SG_ BCM1_MH_Schalter : 31|1@1+ (1.0,0.0) [0.0|1] ""  Motor_konv
 SG_ BCM1_MH_WIV_Schalter : 32|1@1+ (1.0,0.0) [0.0|1] ""  Motor_konv
 SG_ BCM_Eco_Charisma_Taste : 33|1@1+ (1.0,0.0) [0.0|1] ""  Vector__XXX
 SG_ BCM1_NV_Taster : 34|1@1+ (1.0,0.0) [0.0|1] ""  Vector__XXX
 SG_ BCM1_AFS_Lampe : 35|1@1+ (1.0,0.0) [0.0|1] ""  Vector__XXX
 SG_ BCM1_Reisemodus_Texte : 36|2@1+ (1.0,0.0) [0.0|3] ""  Vector__XXX
 SG_ BCM1_Lichtwarn_Texte : 38|2@1+ (1.0,0.0) [0.0|3] ""  Vector__XXX
 SG_ Gong_TFL_Umschaltung : 40|1@1+ (1.0,0.0) [0.0|1] ""  Vector__XXX
 SG_ BCM_ValetTaster_Fkts_LED : 42|1@1+ (1.0,0.0) [0.0|1] ""  Vector__XXX
 SG_ LRH_Taster : 43|1@1+ (1.0,0.0) [0.0|1] ""  Vector__XXX
 SG_ APS_Tongeber_defekt : 44|1@1+ (1.0,0.0) [0.0|1] ""  Vector__XXX
 SG_ BCM1_EasyEntry_Status : 45|1@1+ (1.0,0.0) [0.0|1] ""  Vector__XXX
 SG_ BCM1_Lenksaeule_aktiv : 46|1@1+ (1.0,0.0) [0.0|1] ""  Vector__XXX
 SG_ BCM1_Spannungs_Anf : 47|2@1+ (1.0,0.0) [0.0|3] ""  Vector__XXX
 SG_ DWA_Alarmquelle : 49|5@1+ (1.0,0.0) [0.0|31] ""  Vector__XXX
 SG_ DWA_Einschraenkung : 54|1@1+ (1.0,0.0) [0.0|1] ""  Vector__XXX
 SG_ BCM_HBFS_EOE_aktiv : 56|1@1+ (1.0,0.0) [0.0|1] ""  Vector__XXX
 SG_ BCM_HFS_EOE_aktiv : 57|1@1+ (1.0,0.0) [0.0|1] ""  Vector__XXX
 SG_ BCM_Anf_AAW_MoLaWa : 58|2@1+ (1.0,0.0) [0.0|3] ""  Vector__XXX
 SG_ BCM_Handbremse_Hinweis : 60|1@1+ (1.0,0.0) [0.0|1] ""  Vector__XXX
 SG_ BCM_Waehlhebel_P_Hinweis : 61|1@1+ (1.0,0.0) [0.0|1] ""  Vector__XXX
 SG_ BCM1_Fahrlicht_Hinweis : 62|1@1+ (1.0,0.0) [0.0|1] ""  Vector__XXX
 SG_ BCM_HDF_betaetigt : 63|1@1+ (1.0,0.0) [0.0|1] ""  Vector__XXX

BO_ 869 BEM_05: 8 Gateway_Max
 SG_ BEM_UBDM : 0|8@1+ (0.05,5) [5.05|17.70] "Unit_Volt"  Getriebe_DQ
 SG_ NVEM_Ladefreigabe : 8|2@1+ (1.0,0.0) [0.0|3] ""  Vector__XXX
 SG_ NVEM_FMAus_Info : 10|2@1+ (1.0,0.0) [0.0|3] ""  Vector__XXX
 SG_ NVEM_PTC_Sollstufe : 12|2@1+ (1.0,0.0) [0.0|3] ""  Vector__XXX
 SG_ NVEM_P_Generator_Status : 15|1@1+ (1.0,0.0) [0.0|1] ""  Vector__XXX
 SG_ BEM_P_Generator : 16|8@1+ (50,0) [0|12700] "Unit_Watt"  Motor_konv
 SG_ BEM_n_LLA : 24|2@1+ (1.0,0.0) [0.0|3] ""  Motor_konv
 SG_ NVEM_Abschaltstufe : 26|2@1+ (1.0,0.0) [0.0|3] ""  Motor_konv
 SG_ BEM_Anf_KL : 29|1@1+ (1.0,0.0) [0.0|1] ""  Motor_konv
 SG_ BEM_StartStopp_Info : 30|2@1+ (1.0,0.0) [0.0|3] ""  Motor_konv
 SG_ BEM_DFM : 32|5@1+ (3.225,0.025) [0.025|100.000] ""  Motor_konv
 SG_ BEM_EMLIN_ungueltig : 37|1@1+ (1.0,0.0) [0.0|1] ""  Motor_konv
 SG_ BEM_Batt_Ab : 38|1@1+ (1.0,0.0) [0.0|1] ""  Motor_konv
 SG_ NVEM_FMAus_I_Verbrauch : 39|5@1+ (5,0) [0|145] "Unit_Amper"  Vector__XXX
 SG_ NVEM_Freilauf_Info : 44|2@1+ (1.0,0.0) [0.0|3] ""  Motor_konv
 SG_ NVEM_Red_KL : 46|2@1+ (1.0,0.0) [0.0|3] ""  Motor_konv
 SG_ BEM_Segel_Info : 48|2@1+ (1.0,0.0) [0.0|3] ""  Vector__XXX
 SG_ BEM_HYB_DC_uSollLV : 50|6@1+ (0.1,10.6) [10.6|16.0] "Unit_Volt"  Vector__XXX
 SG_ BEM_HYB_DC_uMinLV : 56|8@1+ (0.1,0) [0.0|25.3] "Unit_Volt"  Vector__XXX

BO_ 1163 BEM_06: 8 Gateway_Max
 SG_ BEM_06_CRC : 0|8@1+ (1,0) [0|255] ""  Getriebe_DQ
 SG_ BEM_06_BZ : 8|4@1+ (1,0) [0|15] ""  Getriebe_DQ
 SG_ NVEM_Betriebsart : 12|4@1+ (1.0,0.0) [0.0|15] ""  Vector__XXX
 SG_ NVEM_Ladezustand : 16|7@1+ (1,0) [0|100] "Unit_PerCent"  Vector__XXX
 SG_ NVEM2_Status_FuSiFahrt : 23|3@1+ (1.0,0.0) [0.0|7] ""  Vector__XXX
 SG_ NVEM_Energienetz_Status : 26|3@1+ (1.0,0.0) [0.0|7] ""  Getriebe_DQ
 SG_ NVEM_Vorgabe_Leistungsstufe : 29|3@1+ (1.0,0.0) [0.0|7] ""  Vector__XXX
 SG_ NVEM2_Typ_EnergieNetz : 32|4@1+ (1.0,0.0) [0.0|15] ""  Vector__XXX
 SG_ NVEM_Energie_Klima_Vorgabe : 36|8@1+ (10,0) [0|2530] "Unit_WattHour"  Vector__XXX
 SG_ NVEM_Last_Anf : 44|2@1+ (1.0,0.0) [0.0|3] ""  Vector__XXX
 SG_ NVEM_STH_ZielzeitLang : 46|4@1+ (10,0) [0|120] "Unit_Minut"  Vector__XXX
 SG_ NVEM_Red_KomfortVerbrauch : 50|4@1+ (1.0,0.0) [0.0|15] ""  Vector__XXX
 SG_ NVEM_PTC_Sollstufe : 54|2@1+ (1.0,0.0) [0.0|3] ""  Vector__XXX
 SG_ NVEM_Bordnetzdiagnose : 56|2@1+ (1.0,0.0) [0.0|3] ""  Vector__XXX
 SG_ HLR_PTC_linear_Freigabe : 58|6@1+ (50,0) [0|3100] "Unit_Watt"  Vector__XXX

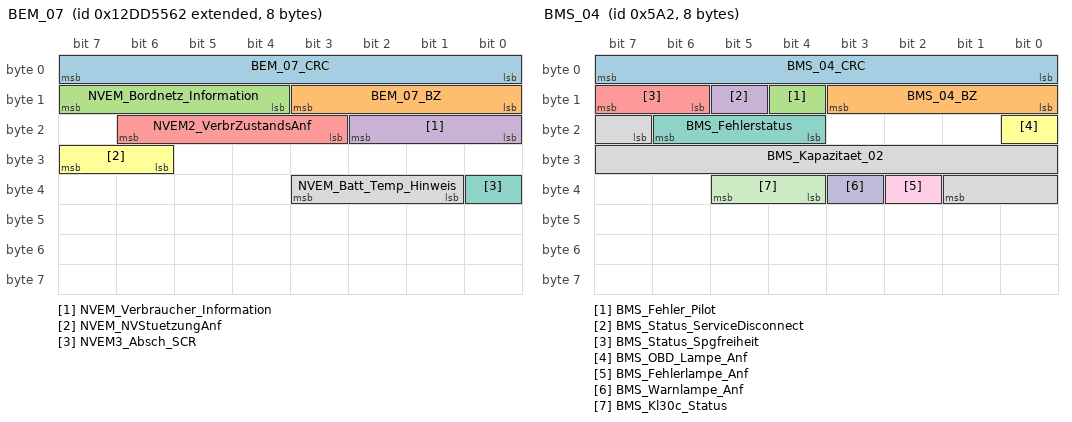
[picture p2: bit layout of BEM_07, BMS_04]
BO_ 2463978850 BEM_07: 8 Gateway_Max
 SG_ BEM_07_CRC : 0|8@1+ (1,0) [0|255] ""  Vector__XXX
 SG_ BEM_07_BZ : 8|4@1+ (1,0) [0|15] ""  Vector__XXX
 SG_ NVEM_Bordnetz_Information : 12|4@1+ (1.0,0.0) [0.0|15] ""  Vector__XXX
 SG_ NVEM_Verbraucher_Information : 16|3@1+ (1.0,0.0) [0.0|7] ""  Vector__XXX
 SG_ NVEM2_VerbrZustandsAnf : 19|4@1+ (1.0,0.0) [0.0|15] ""  Motor_konv
 SG_ NVEM_NVStuetzungAnf : 30|2@1+ (1.0,0.0) [0.0|3] ""  Vector__XXX
 SG_ NVEM3_Absch_SCR : 32|1@1+ (1.0,0.0) [0.0|1] ""  Vector__XXX
 SG_ NVEM_Batt_Temp_Hinweis : 33|3@1+ (1.0,0.0) [0.0|7] ""  Vector__XXX

BO_ 1442 BMS_04: 8 Gateway_Max
 SG_ BMS_04_CRC : 0|8@1+ (1,0) [0|255] ""  Vector__XXX
 SG_ BMS_04_BZ : 8|4@1+ (1,0) [0|15] ""  Vector__XXX
 SG_ BMS_Fehler_Pilot : 12|1@1+ (1.0,0.0) [0.0|1] ""  Vector__XXX
 SG_ BMS_Status_ServiceDisconnect : 13|1@1+ (1.0,0.0) [0.0|1] ""  Vector__XXX
 SG_ BMS_Status_Spgfreiheit : 14|2@1+ (1.0,0.0) [0.0|3] ""  Vector__XXX
 SG_ BMS_OBD_Lampe_Anf : 16|1@1+ (1.0,0.0) [0.0|1] ""  Vector__XXX
 SG_ BMS_Fehlerstatus : 20|3@1+ (1.0,0.0) [0.0|7] ""  Vector__XXX
 SG_ BMS_Kapazitaet_02 : 23|11@1+ (0.2,0) [0.0|409.2] "Unit_AmperHour"  Vector__XXX
 SG_ BMS_Fehlerlampe_Anf : 34|1@1+ (1.0,0.0) [0.0|1] ""  Vector__XXX
 SG_ BMS_Warnlampe_Anf : 35|1@1+ (1.0,0.0) [0.0|1] ""  Vector__XXX
 SG_ BMS_Kl30c_Status : 36|2@1+ (1.0,0.0) [0.0|3] ""  Vector__XXX

BO_ 1450 BMS_04_SOK_Signatur: 8 Gateway_Max
 SG_ SOK_BMS_04_Signatur : 0|64@1+ (1,0) [1|18446744073709551615] "Unit_None"  Vector__XXX

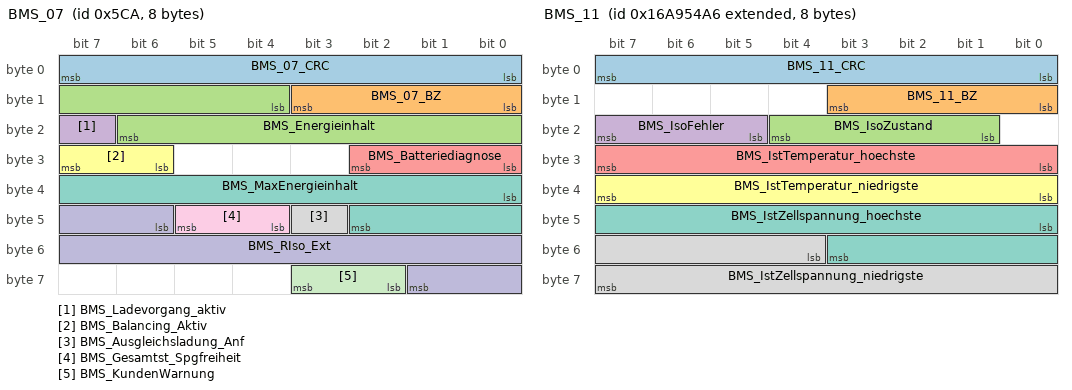
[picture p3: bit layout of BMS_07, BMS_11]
BO_ 1482 BMS_07: 8 Gateway_Max
 SG_ BMS_07_CRC : 0|8@1+ (1,0) [0|255] ""  Vector__XXX
 SG_ BMS_07_BZ : 8|4@1+ (1,0) [0|15] ""  Vector__XXX
 SG_ BMS_Energieinhalt : 12|11@1+ (50,0) [0|102250] "Unit_WattHour"  Vector__XXX
 SG_ BMS_Ladevorgang_aktiv : 23|1@1+ (1.0,0.0) [0.0|1] ""  Vector__XXX
 SG_ BMS_Batteriediagnose : 24|3@1+ (1.0,0.0) [0.0|7] ""  Vector__XXX
 SG_ BMS_Balancing_Aktiv : 30|2@1+ (1.0,0.0) [0.0|3] ""  Vector__XXX
 SG_ BMS_MaxEnergieinhalt : 32|11@1+ (50,0) [0|102250] "Unit_WattHour"  Vector__XXX
 SG_ BMS_Ausgleichsladung_Anf : 43|1@1+ (1.0,0.0) [0.0|1] ""  Vector__XXX
 SG_ BMS_Gesamtst_Spgfreiheit : 44|2@1+ (1.0,0.0) [0.0|3] ""  Vector__XXX
 SG_ BMS_RIso_Ext : 46|12@1+ (5,0) [0|20465] "Unit_KiloOhm"  Vector__XXX
 SG_ BMS_KundenWarnung : 58|2@1+ (1.0,0.0) [0.0|3] ""  Vector__XXX

BO_ 2527679654 BMS_11: 8 Gateway_Max
 SG_ BMS_11_CRC : 0|8@1+ (1,0) [0|255] ""  Vector__XXX
 SG_ BMS_11_BZ : 8|4@1+ (1,0) [0|15] ""  Vector__XXX
 SG_ BMS_IsoZustand : 17|4@1+ (1.0,0.0) [0.0|15] ""  Vector__XXX
 SG_ BMS_IsoFehler : 21|3@1+ (1.0,0.0) [0.0|7] ""  Vector__XXX
 SG_ BMS_IstTemperatur_hoechste : 24|8@1+ (0.5,-40) [-40.0|86.0] "Unit_DegreCelsi"  Vector__XXX
 SG_ BMS_IstTemperatur_niedrigste : 32|8@1+ (0.5,-40) [-40.0|86.0] "Unit_DegreCelsi"  Vector__XXX
 SG_ BMS_IstZellspannung_hoechste : 40|12@1+ (1,1000) [1000|5091] "Unit_MilliVolt"  Vector__XXX
 SG_ BMS_IstZellspannung_niedrigste : 52|12@1+ (1,1000) [1000|5091] "Unit_MilliVolt"  Vector__XXX

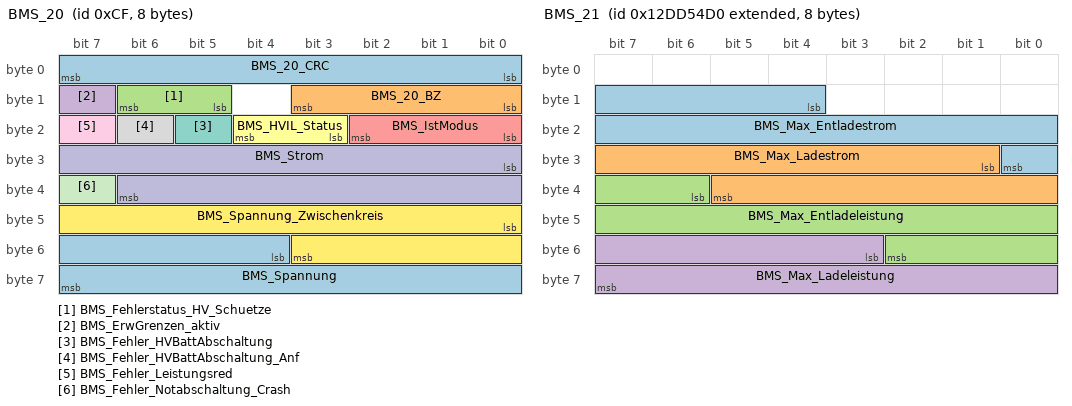
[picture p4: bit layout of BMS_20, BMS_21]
BO_ 207 BMS_20: 8 Gateway_Max
 SG_ BMS_20_CRC : 0|8@1+ (1,0) [0|255] ""  Vector__XXX
 SG_ BMS_20_BZ : 8|4@1+ (1,0) [0|15] ""  Vector__XXX
 SG_ BMS_Fehlerstatus_HV_Schuetze : 13|2@1+ (1.0,0.0) [0.0|3] ""  Vector__XXX
 SG_ BMS_ErwGrenzen_aktiv : 15|1@1+ (1.0,0.0) [0.0|1] ""  Vector__XXX
 SG_ BMS_IstModus : 16|3@1+ (1.0,0.0) [0.0|7] ""  Vector__XXX
 SG_ BMS_HVIL_Status : 19|2@1+ (1.0,0.0) [0.0|3] ""  Vector__XXX
 SG_ BMS_Fehler_HVBattAbschaltung : 21|1@1+ (1.0,0.0) [0.0|1] ""  Vector__XXX
 SG_ BMS_Fehler_HVBattAbschaltung_Anf : 22|1@1+ (1.0,0.0) [0.0|1] ""  Vector__XXX
 SG_ BMS_Fehler_Leistungsred : 23|1@1+ (1.0,0.0) [0.0|1] ""  Vector__XXX
 SG_ BMS_Strom : 24|15@1+ (0.1,-1630) [-1630.0|1630.0] "Unit_Amper"  Vector__XXX
 SG_ BMS_Fehler_Notabschaltung_Crash : 39|1@1+ (1.0,0.0) [0.0|1] ""  Vector__XXX
 SG_ BMS_Spannung_Zwischenkreis : 40|12@1+ (0.5,-1000) [-1000.0|1000.0] "Unit_Volt"  Vector__XXX
 SG_ BMS_Spannung : 52|12@1+ (0.25,0) [0.00|1000.00] "Unit_Volt"  Vector__XXX

BO_ 2463978704 BMS_21: 8 Gateway_Max
 SG_ BMS_Max_Entladestrom : 12|13@1+ (0.2,0) [0.0|1630.0] "Unit_Amper"  Vector__XXX
 SG_ BMS_Max_Ladestrom : 25|13@1+ (0.2,0) [0.0|1630.0] "Unit_Amper"  Vector__XXX
 SG_ BMS_Max_Entladeleistung : 38|13@1+ (100,0) [0|818000] "Unit_Watt"  Vector__XXX
 SG_ BMS_Max_Ladeleistung : 51|13@1+ (100,0) [0|818000] "Unit_Watt"  Vector__XXX

BO_TX_BU_ 2536767280 :Gateway_Max,Motor_konv;

CM_ "ACANFD_V14.09F Generated by BusNet_NG_Produktiv 9.25.5";
CM_ BU_ Getriebe_DQ "Getriebe DQ MQBw_Baseline";
CM_ BU_ Motor_konv "Motor-SG konventionell (Diesel/Otto/mHEV) MQBw_Baseline";
CM_ BU_ Schaltbetaetigung "Monostabiler Wählhebel MQBw_Baseline";

CM_ BO_ 1660 "MLBevo";
CM_ BO_ 1633 "ab MQB 7.2";
CM_ BO_ 2536717312 "BAP ASG message EfficiencyAssist (PEA)<br>
Sender: HU (MIB)
Receiver: MSG";
CM_ BO_ 2536717313 "BAP ASG message EfficiencyAssist (PEA)<br>
Sender: Kombi
Receiver: MSG";
CM_ BO_ 2536717328 "BAP FSG message EfficiencyAssist (PEA)<br>
Sender: MSG<br>
Receiver: HU (MIB)";
CM_ BO_ 869 "ab MQB";

CM_ SG_ 333 ACC_18_BZ "4bit Botschaftszähler, wird mit jeder Sendebotschaft inkrementiert";
CM_ SG_ 333 ACC_18_CRC "Für MLB:
Berechnung siehe Lastenheft 'Kommunikationsabsicherung für FlexRay und CAN'
Ab MQB und MLBevo:
Berechnung siehe Lastenheft 'End-to-End Kommunikationsabsicherung'

Endwerte siehe Begleitdokument 'S-PDU Kennungsfolgen'";
CM_ SG_ 333 ACC_Abbiegewunsch "Identifizierter Abbiegewunsch vom Fahrer";
CM_ SG_ 333 ACC_Abbiegewunsch_Abstand "Ort des identifizierten Abbiegewunsches vom Fahrer";
CM_ SG_ 333 ACC_Anfahren "Anforderung Anfahren";
CM_ SG_ 333 ACC_Anforderung_HMS "Bremsanforderung an den Haltemanager";
CM_ SG_ 333 ACC_Anhalten "Im Falle eines gesetzten Bits wird vom ACC ein Anhalten bis in den Stand gewünscht. Das Bit wird von ACC nur unterhalb einer appl. Geschwindigkeitsschwelle gesetzt. Notwendig für die ACCplus-Funktionalität. Nicht für Audi B8 relevant, jedoch im Vorgriff a";
CM_ SG_ 333 ACC_Anhalteweg "Verbleibender Weg bis zum Stillstand";
CM_ SG_ 333 ACC_Blindheit_erkannt "Blindheitserkennung";
CM_ SG_ 333 ACC_Boost "Aktivität der Boost-Funktion des ACC";
CM_ SG_ 333 ACC_DynErhoehung "Ansteuerung einer erhöhten Dynamik im Verzögerungsfall (vor allem beim Motormomentenabbau)";
CM_ SG_ 333 ACC_FoD_Status "Informiert den TSK und Kombi, ob die ACC-Funktion freigeschaltet ist oder nicht.";
CM_ SG_ 333 ACC_Folgebeschl "Sollbeschleunigung des ACC-Folgeregler";
CM_ SG_ 333 ACC_Freilauf_Anf "Freilauf-Anforderung durch Energo/ACC";
CM_ SG_ 333 ACC_Freilauf_Info "Freilauf-Freigabe durch Aktiven Teilnehmer Freilauf";
CM_ SG_ 333 ACC_Freilaufstrategie_TSK "Das Signal definiert im aktiven ACC - Betrieb, ob ein Freilauf direkt über das ACC angefordert wird oder ein Freilauf über den Triebstrangkoordinator (TSK) angefordert wird, falls das ACC den Freilauf freigibt.";
CM_ SG_ 333 ACC_limitierte_Anfahrdyn "Info für den Motor, dass beim ACC-Anfahren mit Zielfahrzeug seitens ACC eine limitierte Fahrpedalkennlinie gefordert wird.";
CM_ SG_ 333 ACC_Minimale_Bremsung "Im Falle eines gesetzten Bits wird vom ACC dem TSK angezeigt, dass es sich im Resume_Suspend_Mode befindet. In diesem Mode darf der TSK keine ECD-Bremsung anfordern, unabhängig von der 'ACC_Sollbeschleunigungsanforderung'. Eine Fahrzeugverzögerung darf nu";
CM_ SG_ 333 ACC_nachtr_Stopp_Anf "Dieses Signal dient dem Motor als Trigger, dass ein nachträglicher Motorstopp eingeleitet werden kann, wenn es die Bedingungen des StSt Koordinators dies zulassen.";
CM_ SG_ 333 ACC_neg_Sollbeschl_Grad_02 "Empfehlung an den Triebstrangkoordinator , mit welchem betragsmäßig maximalen negativen Gradienten eine ACC-Anforderung 'ACC_Sollbeschleunigung_02' einzuregeln ist.";
CM_ SG_ 333 ACC_pos_Sollbeschl_Grad_02 "Empfehlung an den Triebstrangkoordinator , mit welchem betragsmäßig maximalen positiven Gradienten eine ACC-Anforderung 'ACC_Sollbeschleunigung_02' einzuregeln ist.";
CM_ SG_ 333 ACC_relev_Nichtverfuegbarkeit "Frontradar-SG erkennt eine temporäre Nichtverfügbarkeit, ohne FSP-Eintrag";
CM_ SG_ 333 ACC_relevanter_Fehler "Frontradar-SG erkennt einen Fehler, mit FSP-Eintrag.";
CM_ SG_ 333 ACC_Sollbeschleunigung_02 "Anforderung an den Triebstrangkoordinator , eine 'ACC_Sollbeschleunigung' umzusetzen.";
CM_ SG_ 333 ACC_StartStopp_Info "Freigabe bzw. Startanforderung für Start/Stopp";
CM_ SG_ 333 ACC_Status_ACC "'ACC OFF' bedeutet ACC-Hauptschalter ist 'Gerastet Aus

'ACC Reversibler Fehler' bedeutet, daß das ACC aktuell einen 
reversiblen Fehler im ACC-SG selbst oder in einem zum 
ACC-System gehörenden SG erkennt.

'ACC irreversibler Fehler' bedeutet, daß ";
CM_ SG_ 333 ACC_TA_Kurve_Abstand "Gibt den Abstand zu dem Punkt an, auf den sich das Geschwindigkeitsdelta bezieht. Dieser Punkt ist nicht der Kurveneingang, sondern der Punkt in der Kurve mit maximaler Krümmung. Der Kurveneingang kann uns nicht zur Verfügung gestellt werden";
CM_ SG_ 333 ACC_TA_Kurve_vDelta "Beschreibung: Gibt das Delta der vom ACC eingeregelten Geschwindigkeit im Vergleich zu der Geschwindigkeit an, die für eine erfolgreiche TA Durchfahrt eingestellt werden müsste.";
CM_ SG_ 333 ACC_Tempolimitassistent_Ein "Status ACC-Tempolimitassistent";
CM_ SG_ 333 ACC_Typ "Motor plausibilisiert seine eigene Kodierung";
CM_ SG_ 333 ACC_Verkehrssinn "Vom Radar erkannter Verkehrssinn";
CM_ SG_ 333 ACC_zul_Regelabw_oben "Anforderung an den Triebstrangkoordinator. Zulässiger Betrag der Abweichung zwischen angeforderter 'ACC_Sollbeschleunigung(_02)' und umzusetzender Sollbeschleunigung  im TSK. Im TSK wird, abhängig vom Arbeitspunkt die Toleranz und die Sollbeschleunigung f";
CM_ SG_ 333 ACC_zul_Regelabw_unten "Anforderung an den Triebstrangkoordinator. Zulässiger Betrag der Abweichung zwischen angeforderter 'ACC_Sollbeschleunigung(_02)' und umzusetzender Sollbeschleunigung  im TSK. Im TSK wird, abhängig vom Arbeitspunkt die Toleranz und die Sollbeschleunigung f";
CM_ SG_ 333 MPPmod_1_Segment "Erstes vom MPP abweichendes Segment, welches befahren werden soll.";
CM_ SG_ 333 MPPmod_2_Segment "Zweites vom MPP abweichendes Segment, welches befahren werden soll";
CM_ SG_ 333 MPPmod_3_Segment "Drittes vom MPP abweichendes Segment, welches befahren werden soll.";
CM_ SG_ 333 MPPmod_4_Segment "Viertes vom MPP abweichendes Segment, welches befahren werden soll.";
CM_ SG_ 333 RDR_v_ueber_Grund "Das Signal V_ueber_Grund zeigt die Fahrzeuggeschwindigkeit über Grund in X-Richtung an.
Das Signal wird ausschließlich durch Auswertung von Radarsignalen erzeugt.";
CM_ SG_ 333 RDR_v_ueber_Grund_Fahrtrichtung "Das Signal zeigt die Fahrtrichtung des Fahrzeugs an.  
Das Signal wird ausschließlich durch Auswertung von Radarsignalen erzeugt.";
CM_ SG_ 333 RDR_v_ueber_Grund_Genauigkeit "Das Signal zeigt die Genauigkeit des Geschwindigkeitssignals RDR_v_ueber_Grund im 95%-Konfidenzintervall an.";
CM_ SG_ 333 RDR_VBEG_Anforderung "Anforderung einer Höchstgeschwindigkeitsbegrenzung durch den Frontradar";
CM_ SG_ 333 vESC_Verz_Anf "Die Funktion vorausschauendes ESC fordert eine Verzögerung im VZM.";

CM_ SG_ 859 ACC_Obj_01_Alter "Objektdatenalter (Anzahl der Zyklen seit der Intitialisierung des Objekts im Sensor)";
CM_ SG_ 859 ACC_Obj_01_Anzeige_Rel "Statusinformation zur Anzeigerelevanz des Objektes";
CM_ SG_ 859 ACC_Obj_01_ax_StdA "Standardabweichung der Relativbeschleunigung in x-Richtung des bezüglich des Ego-Fzg. Momentankurses detektierten Objektes";
CM_ SG_ 859 ACC_Obj_01_ax_v "Relative Beschleunigung in x (m/s2) Beschleunigungen beziehen sich immer auf den Objektmittelpunkt";
CM_ SG_ 859 ACC_Obj_01_axAbs_StdA "Standardabweichung der Absolutbeschleunigung in x-Richtung";
CM_ SG_ 859 ACC_Obj_01_axAbs_v "Absolutbeschleunigung in x (m/s2) des Objektes";
CM_ SG_ 859 ACC_Obj_01_ay_StdA "Standardabweichung zu ACC_Obj_01_ay_v";
CM_ SG_ 859 ACC_Obj_01_ay_v "Relative Beschleunigung in y (m/s2) Beschleunigungen beziehen sich immer auf den Objektmittelpunkt";
CM_ SG_ 859 ACC_Obj_01_Bew_Zustand "Bewegungszustand des Objektes
Init
fahrend
angehalten
stehend";
CM_ SG_ 859 ACC_Obj_01_Bezugspunkt "Index des verwendeten Bezugspunktes auf der 3D-Objektbox Anmerkung: Die Bezeichnungen vorne/hinten rechts/links beziehen sich direkt auf die angegebene Ausrichtung des Objekts. Sollte diese Information nicht vorliegen, kann eine Ausrichtung gewählt werden";
CM_ SG_ 859 ACC_Obj_01_Breite "Breite der 3D-Objektbox";
CM_ SG_ 859 ACC_Obj_01_BreiteStdA "Standardabweichung zu ACC_Obj_01_Breite";
CM_ SG_ 859 ACC_Obj_01_dx_StdA "Standardabweichung zu ACC_Obj_01_dx_v";
CM_ SG_ 859 ACC_Obj_01_dx_v "Position des Objektes in x-Richtung (Referenzpunkt der 3D-Objektbox)";
CM_ SG_ 859 ACC_Obj_01_dy_StdA "Standardabweichung zu ACC_Obj_01_dy_v";
CM_ SG_ 859 ACC_Obj_01_dy_v "Position des Objektes in y-Richtung (Referenzpunkt der 3D-Objektbox)";
CM_ SG_ 859 ACC_Obj_01_dz_StdA "Standardabweichung zu ACC_Obj_01_dz_v";
CM_ SG_ 859 ACC_Obj_01_dz_v "Position der Unterkante  des Objektes in z bezügl. des 3D Koordinatensystems  (Referenzpunkt der 3D-Objektbox). Anmerkung: Fahrzeuge können damit durch Bodenunebenheiten Z-Werte<>0 erhalten!";
CM_ SG_ 859 ACC_Obj_01_ExistenzMass "Wahrscheinlichkeit, dass an der angegebenen Position (im 3sigma-Bereich) zum angegebenen Zeitpunkt ein Objekt existiert
Anmerkung: Vorschlag durch jeweiligen Zulieferer / Erklärung der Berechnung / Vergleich mit eigenen (konzerninternen) Maßen";
CM_ SG_ 859 ACC_Obj_01_Fusion_ID_FER_VL "Information, mit welchem Eckradarobjekt  (vorne links) das Gegenverkehrsobjekt in der SDF bestätigt wurde";
CM_ SG_ 859 ACC_Obj_01_Fusion_ID_FER_VR "Information, mit welchem Eckradarobjekt  (vorne rechts) das Gegenverkehrsobjekt in der SDF bestätigt wurde";
CM_ SG_ 859 ACC_Obj_01_Fusion_ID_VD "Information, mit welchem Videoobjekt (ID) das Gegenverkehrsobjekt in der SDF bestätigt wurde";
CM_ SG_ 859 ACC_Obj_01_Gemessen "Status Objekt gemessen/getrackt

0 = Objekt nicht gemessen, nur per 3D Modell praediziert (auch BVS)
1 = Objekt wurde im aktuellen Zyklus gemessen
2 = Nur für BVS: Objekt wurde nicht gemessen, sondern per Feature-Tracking wiedergefunden (Optischer Flu";
CM_ SG_ 859 ACC_Obj_01_GierWnkl "Gierwinkel des Objektes relativ zum EGO Fahrzeug (=Orientierung der 3D-Objektbox)";
CM_ SG_ 859 ACC_Obj_01_GierWnklStdA "Standardabweichung zu ACC_Obj_01_GierWnkl";
CM_ SG_ 859 ACC_Obj_01_Historie "Objekt wurde bereits in den letzten Zyklen gemessen (0.. Erstmalige Ausgabe auf dem Bus)
Anmerkung: Wenn das Objekt zwischenzeitlich nicht auf dem Bus ausgegeben wird, aber intern weiter verfolgt wird, wird das Bit bei einer weiteren Ausgabe des SELBEN O";
CM_ SG_ 859 ACC_Obj_01_Hoehe "Höhe der 3D-Objektbox (m) Der Maximalwert 3,875 wird hier als Ausgabe für Objekte einer Höhe von 3,875 m und höher verstanden.";
CM_ SG_ 859 ACC_Obj_01_HoeheStdA "Standardabweichung zu ACC_Obj_01_Hoehe";
CM_ SG_ 859 ACC_Obj_01_ID "ID des Objektes";
CM_ SG_ 859 ACC_Obj_01_Klasse "Klasse des Objekts";
CM_ SG_ 859 ACC_Obj_01_KlassePlausib "Wahrscheinlichkeit für die korrekte Klassifizierung des Objektes";
CM_ SG_ 859 ACC_Obj_01_Laenge "Länge der 3D-Objektbox. Der phys. Maximalwert 31,875 wird hier als Ausgabe für Objekte einer Länge von 31,875 m und länger verstanden. Anmerkung: Länge ist generell nur bei entsprechend großem Gierwinkel bzw. Querversatz zu ermitteln";
CM_ SG_ 859 ACC_Obj_01_LaengeStdA "Standardabweichung zu ACC_Obj_01_Laenge";
CM_ SG_ 859 ACC_Obj_01_LaengsRegelung "Info, ob ACC aktuell auf dieses Objekt regelt";
CM_ SG_ 859 ACC_Obj_01_SDFInfo_FER_VL "Bestätigung des Mitverkehrsobjektes durch Fronteckradar VL";
CM_ SG_ 859 ACC_Obj_01_SDFInfo_FER_VR "Bestätigung des Mitverkehrsobjektes durch Fronteckradar VR";
CM_ SG_ 859 ACC_Obj_01_SDFInfo_FR "Bestätigung des Mitverkehrsobjektes durch Frontradar";
CM_ SG_ 859 ACC_Obj_01_SDFInfo_Kamera "Bestätigung des Mitverkehrsobjektes durch Kamera";
CM_ SG_ 859 ACC_Obj_01_vx_StdA "Standardabweichung zu ACC_Obj_01_vx_v";
CM_ SG_ 859 ACC_Obj_01_vx_v "Relative Geschwindigkeit in x (m/s)
Geschwindigkeiten beziehen sich immer auf den Objektmittelpunkt
Messung in Radialrichtung";
CM_ SG_ 859 ACC_Obj_01_vxAbs_StdA "Standardabweichung der Absolutgeschwindigkeit in x-Richtung des bezüglich des Ego-Fzg. Momentankurses detektierten Mitverkehrsobjektdatenblocks";
CM_ SG_ 859 ACC_Obj_01_vxAbs_v "Absolutgeschwindigkeit in x-Richtung des bezüglich des Ego-Fzg. Momentankurses detektierten Mitverkehrsobjektdatenblocks";
CM_ SG_ 859 ACC_Obj_01_vy_StdA "Standardabweichung zu ACC_Obj_01_vy_v";
CM_ SG_ 859 ACC_Obj_01_vy_v "Relative Geschwindigkeit in x (m/s) Geschwindigkeiten beziehen sich immer auf den Objektmittelpunkt Messung in Radialrichtung Geschwindigkeiten beziehen sich immer auf den Objektmittelpunkt";
CM_ SG_ 859 ACC_Obj_01_vyAbs_StdA "Standardabweichung der Absolutgeschwindigkeit in y-Richtung des bezüglich des Ego-Fzg. Momentankurses detektierten Mitverkehrsobjektdatenblocks";
CM_ SG_ 859 ACC_Obj_01_vyAbs_v "Absolutgeschwindigkeit in y-Richtung des bezüglich des Ego-Fzg. Momentankurses detektierten Mitverkehrsobjektdatenblocks";

CM_ SG_ 860 ACC_Obj_04_Alter "Objektdatenalter (Anzahl der Zyklen seit der Intitialisierung des Objekts im Sensor)";
CM_ SG_ 860 ACC_Obj_04_Anzeige_Rel "Statusinformation zur Anzeigerelevanz des Objektes";
CM_ SG_ 860 ACC_Obj_04_ax_StdA "Standardabweichung der Relativbeschleunigung in x-Richtung des bezüglich des Ego-Fzg. Momentankurses detektierten Objektes";
CM_ SG_ 860 ACC_Obj_04_ax_v "Relative Beschleunigung in x (m/s2)
Beschleunigungen beziehen sich immer auf den Objektmittelpunkt";
CM_ SG_ 860 ACC_Obj_04_axAbs_StdA "Standardabweichung der Absolutbeschleunigung in x-Richtung";
CM_ SG_ 860 ACC_Obj_04_axAbs_v "Absolutbeschleunigung in x (m/s2) des Objektes";
CM_ SG_ 860 ACC_Obj_04_ay_StdA "Standardabweichung zu ACC_Obj_04_ay_v";
CM_ SG_ 860 ACC_Obj_04_ay_v "Relative Beschleunigung in y (m/s2)
Beschleunigungen beziehen sich immer auf den Objektmittelpunkt";
CM_ SG_ 860 ACC_Obj_04_Bew_Zustand "Bewegungszustand des Objektes
Init
fahrend
angehalten
stehend";
CM_ SG_ 860 ACC_Obj_04_Bezugspunkt "Index des verwendeten Bezugspunktes auf der 3D-Objektbox";
CM_ SG_ 860 ACC_Obj_04_Breite "Breite der 3D-Objektbox";
CM_ SG_ 860 ACC_Obj_04_BreiteStdA "Standardabweichung zu ACC_Obj_04_Breite";
CM_ SG_ 860 ACC_Obj_04_dx_StdA "Standardabweichung zu ACC_Obj_04_dx_v";
CM_ SG_ 860 ACC_Obj_04_dx_v "Position des Objektes in x-Richtung (Referenzpunkt der 3D-Objektbox)";
CM_ SG_ 860 ACC_Obj_04_dy_StdA "Standardabweichung zu ACC_Obj_04_dy_v";
CM_ SG_ 860 ACC_Obj_04_dy_v "Position des Objektes in y-Richtung (Referenzpunkt der 3D-Objektbox)";
CM_ SG_ 860 ACC_Obj_04_dz_StdA "Standardabweichung zu ACC_Obj_04_dz_v";
CM_ SG_ 860 ACC_Obj_04_dz_v "Position der Unterkante  des Objektes in z bezügl. des 3D Koordinatensystems  (Referenzpunkt der 3D-Objektbox).
Anmerkung: Fahrzeuge können damit durch Bodenunebenheiten Z-Werte<>0 erhalten!";
CM_ SG_ 860 ACC_Obj_04_ExistenzMass "Wahrscheinlichkeit, dass an der angegebenen Position (im 3sigma-Bereich) zum angegebenen Zeitpunkt ein Objekt existiert Anmerkung: Vorschlag durch jeweiligen Zulieferer / Erklärung der Berechnung / Vergleich mit eigenen (konzerninternen) Maßen";
CM_ SG_ 860 ACC_Obj_04_Fusion_ID_FER_VL "Gibt die ID des fusionierten VD-Objektes an";
CM_ SG_ 860 ACC_Obj_04_Fusion_ID_FER_VR "Gibt die ID des fusionierten VD-Objektes an";
CM_ SG_ 860 ACC_Obj_04_Fusion_ID_VD "Gibt die ID des fusionierten VD-Objektes an";
CM_ SG_ 860 ACC_Obj_04_Gemessen "Status Objekt gemessen/getrack";
CM_ SG_ 860 ACC_Obj_04_GierWnkl "Gierwinkel des Objektes relativ zum EGO Fahrzeug (=Orientierung der 3D-Objektbox)";
CM_ SG_ 860 ACC_Obj_04_GierWnklStdA "Standardabweichung zu ACC_Obj_04_GierWnkl";
CM_ SG_ 860 ACC_Obj_04_Historie "Objekt wurde bereits in den letzten Zyklen gemessen (0.. Erstmalige Ausgabe auf dem Bus) Anmerkung: Wenn das Objekt zwischenzeitlich nicht auf dem Bus ausgegeben wird, aber intern weiter verfolgt wird, wird das Bit bei einer weiteren Ausgabe des SELBEN Ob";
CM_ SG_ 860 ACC_Obj_04_Hoehe "Höhe der 3D-Objektbox (m)
Der Maximalwert 3,875 wird hier als Ausgabe für Objekte einer Höhe von 3,875 m und höher verstanden.";
CM_ SG_ 860 ACC_Obj_04_HoeheStdA "Standardabweichung zu ACC_Obj_04_Hoehe";
CM_ SG_ 860 ACC_Obj_04_ID "ID des Objektes";
CM_ SG_ 860 ACC_Obj_04_Klasse "Klasse des Objekts";
CM_ SG_ 860 ACC_Obj_04_KlassePlausib "Wahrscheinlichkeit für die korrekte Klassifizierung des Objektes";
CM_ SG_ 860 ACC_Obj_04_Laenge "Länge der 3D-Objektbox.
Der phys. Maximalwert 31,875 wird hier als Ausgabe für Objekte einer Länge von 31,875 m und länger verstanden.
Anmerkung: Länge ist generell nur bei entsprechend großem Gierwinkel bzw. Querversatz zu ermitteln";
CM_ SG_ 860 ACC_Obj_04_LaengeStdA "Standardabweichung zu ACC_Obj_04_Laenge";
CM_ SG_ 860 ACC_Obj_04_LaengsRegelung "Info, ob ACC aktuell auf dieses Objekt regelt";
CM_ SG_ 860 ACC_Obj_04_SDFInfo_FER_VL "Bestätigung des Mitverkehrsobjektes durch Fronteckradar VL";
CM_ SG_ 860 ACC_Obj_04_SDFInfo_FER_VR "Bestätigung des Mitverkehrsobjektes durch Fronteckradar VR";
CM_ SG_ 860 ACC_Obj_04_SDFInfo_FR "Bestätigung des Mitverkehrsobjektes durch Frontradar";
CM_ SG_ 860 ACC_Obj_04_SDFInfo_Kamera "Bestätigung des Mitverkehrsobjektes durch Kamera";
CM_ SG_ 860 ACC_Obj_04_vx_StdA "Standardabweichung zu ACC_Obj_04_vx_v";
CM_ SG_ 860 ACC_Obj_04_vx_v "Relative Geschwindigkeit in x (m/s)
Geschwindigkeiten beziehen sich immer auf den Objektmittelpunkt
Messung in Radialrichtung";
CM_ SG_ 860 ACC_Obj_04_vxAbs_StdA "Signaldefinition analog Nanoradar";
CM_ SG_ 860 ACC_Obj_04_vxAbs_v "Signaldefinition analog Nanoradar";
CM_ SG_ 860 ACC_Obj_04_vy_StdA "Standardabweichung zu ACC_Obj_04_vy_v";
CM_ SG_ 860 ACC_Obj_04_vy_v "Relative Geschwindigkeit in x (m/s)
Geschwindigkeiten beziehen sich immer auf den Objektmittelpunkt
Messung in Radialrichtung";
CM_ SG_ 860 ACC_Obj_04_vyAbs_StdA "Signaldefinition analog Nanoradar";
CM_ SG_ 860 ACC_Obj_04_vyAbs_v "Signaldefinition analog Nanoradar";

CM_ SG_ 1660 AGA_Charisma_FahrPr "MLBevo: Aktuelles Fahrprogramm des Charisma-Teilnehmers (siehe Systemlastenheft Drive Select)
MQB: Istwert der Kennlinie (siehe Systemlastenheft MQB FPA)";
CM_ SG_ 1660 AGA_Charisma_Status "Rückmeldung an den Charisma-Master

Wert 0x3 ist nur für Fahrzeuge ab MQB relevant";
CM_ SG_ 1660 AGA_ohne_Funktion "Aussensoundsteuergerät ohne Funktion (Gesetzliche Anforderung, Fahrzeugnutzer muss informiert werden).";
CM_ SG_ 1660 AGA_Texte "Texte zur Anzeige im Kombi";
CM_ SG_ 1660 AGA_Verstaerker_Mute "Freischaltung Verstaerkerkanal";
CM_ SG_ 1660 E_Sound_verbaut "Signal dient zur Unterscheidung der beiden SGs 'aktive AGA' und 'e-sound' durch das Kombii. Beide SGs nutzen identische Signale und gleiche Diagnoseadresse.";

CM_ SG_ 64 AB_Anzeige_Fussg "Anzeige für ausgelöste Fussgängerschutz-Aktuatorik";
CM_ SG_ 64 AB_Belegung_VF "Belegungserkennung vorne Fahrer.";
CM_ SG_ 64 AB_Crash_Int "Crash_Intensität_1 = fahrzeugabhängige Reaktionen im Crash
Crash_Intensität_2 = fahrzeugabhängige Reaktionen im Crash
Crash_Intensität_3 = fahrzeugabhängige Reaktionen im Crash

Die jeweiligen fahrzeugabhängigen Reaktionen im Crash sind in einem separ";
CM_ SG_ 64 AB_Deaktiviert "Airbag oder Gurtstraffer wurden per Anpassung deaktiviert: Aktualisierung erst nach Selbsttest";
CM_ SG_ 64 AB_Deaktivierung_HV "Deaktivierung des HV-Systems und der HV-Teilnehmer im Crash (u.a. Hybrid- und Elektrofahrzeuge)";
CM_ SG_ 64 AB_Diagnose "Airbag in Diagnose";
CM_ SG_ 64 AB_eCS_Error "Signal zur Anforderung der Anzeige von Störungen im System der elektrischen Gurtverriegelung";
CM_ SG_ 64 AB_EDR_Trigger "Triggerbedingung zur dezentralen Aufzeichnung unfallrelevanter Daten im Event Data Recorder";
CM_ SG_ 64 AB_Erh_Auf_VB "Der Fahrer soll bei einem Statuswechsel des Beifahrerairbags (ausgelöst durch die Beifahrerinsassenerkennung oder den Schlüsselschloßschalter) aufmerksam gemacht werden durch eine Anzeige im Kombi. Nur Audi: gültig für: AB2 (4-Türer AU352), B7, C6, D3";
CM_ SG_ 64 AB_Front_Crash "Bit wird bei Überschreitung der Gurtstraffer-, US- und RdW-Schwelle gesetzt";
CM_ SG_ 64 AB_Gurtschloss_FA_ext "Das Ergebnis der Basisfunktion 'Plausibilisierung Gurtschloss' des Verlassenskonzepts wird im Signal dargestellt.";
CM_ SG_ 64 AB_Gurtschloss_FA_ext_aktiv "Über dieses Signal wird signalisiert ob die Erweiterte Gurtdiagnose (Ergebnis wird im Signal AB_Gurtschloss_FA_ext dargestellt) aktiviert oder deaktiviert ist.";
CM_ SG_ 64 AB_Gurtwarn_VB "Beifahrer hat Gurt nicht gesteckt, Anzeige im Kombi";
CM_ SG_ 64 AB_Gurtwarn_VF "Fahrer hat Gurt nicht gesteckt, Anzeige im Kombi";
CM_ SG_ 64 AB_Heck_Crash "Wird für alle neu anlaufenden Projekte umgesetzt: AB8.4, Audi8/VW8";
CM_ SG_ 64 AB_Lampe "Sicherheitswarnlampe im Kombi wird vom Airbag-SG angesteuert; Zustand der Lampe wird auf dem CAN-Bus ausgegeben (auch Blinkinformation).";
CM_ SG_ 64 AB_MKB_Anforderung "Anforderung Multi-Kollisions-Bremsung";
CM_ SG_ 64 AB_MKB_gueltig "Multi-Kollisions-Bremsung im Airbag freigeschaltet";
CM_ SG_ 64 AB_PAO_Leuchte_Anf "Anforderung an die Passenger-Airbag-Off Leuchte in der Dachkonsole (ein / aus), Einsatz nur bei PAG";
CM_ SG_ 64 AB_RGS_Anst "PreCrash-Ansteuerung reversibler Gurtstraffer (Aktivierung und Kraftniveau)

10xx = deaktiviert";
CM_ SG_ 64 AB_Rollover_Crash "Wird im B6/B7 Cabrio und New Beetle Cabrio bedient. ";
CM_ SG_ 64 AB_SB_Crash "Z.Zt. nur in Verbindung mit Crash-Intensität >= 100b (Kraftstoffpumpenabschaltung) verwendet.
";
CM_ SG_ 64 AB_SF_Crash "Z.Zt. nur in Verbindung mit Crash-Intensität >= 100b (Kraftstoffpumpenabschaltung) verwendet.";
CM_ SG_ 64 AB_Stellgliedtest "Information, ob Airbag im Stellgliedtest ist, um eine Notrufauflösung beim Stellgliedtest zu verhindern";
CM_ SG_ 64 AB_Systemfehler "Systemfehler Ggf. wird Warnlampe dauernd eingeschaltet.";
CM_ SG_ 64 AB_Texte_AKS "Textanzeige für pyrotechnische Auslösung der aktiven Kopfstütze (AKS)";
CM_ SG_ 64 AB_VB_deaktiviert "Als Option vorgehalten, Beifahrerairbag wurden per Schlüsselschalter oder Insassenerkennung deaktiviert";
CM_ SG_ 64 AB_Versorgungsspannung "Übertragung der Plausibilitätsinformation Kl.15-Last vs. Kl.15-CAN.
Bedienung im Fall Kl.15-Last 'EIN' und Kl.15-CAN 'AUS' mit Ausgabe Warnung/Akustik im Kombi.";
CM_ SG_ 64 Airbag_01_CRC "Für MLB:
'Berechnung siehe Lastenheft 'Kommunikationsabsicherung für FlexRay und CAN''

Ab MQB und MLBevo:
'Berechnung siehe Lastenheft 'End-to-End Kommunikationsabsicherung''

Endwerte siehe Begleitdokument 'S-PDU Kennungsfolgen'";
CM_ SG_ 64 ASM_Masterzeit_02 "Masterzeit für alle ASM Sender";

CM_ SG_ 1312 AB_Abschaltanf_SIH_BF "Die Insassenerkennung auf der Beifahrerseite fordert bei Übertemperatur eine Abschaltung der Sitzheizung an. Die Übertemperatur kann bei niederohmigen Nebenschlüssen der Sitzheizungsmatte als Folge von zu hohem resultierenden Strom auftreten.";
CM_ SG_ 1312 AB_Anforderung_eCall "Trigger für Car2X Steuergerät das ein eCall Ereignis erkannt wurde.";
CM_ SG_ 1312 AB_Anforderung_USM "Trigger für Gateway (OBDC) und MIB/MMI, dass ein USM-Ereignis erkannt wurde.";
CM_ SG_ 1312 AB_Anprall_FGS "Uebermittlung der Lage einer Kollision, Fussgaengerschutz-Aktorik";
CM_ SG_ 1312 AB_Anprall_Front_Beifahrer "Uebermittlung der Lage einer Kollision, Anprallzone Front Beifahrerseite";
CM_ SG_ 1312 AB_Anprall_Front_Fahrer "Uebermittlung der Lage einer Kollision, Anprallzone Front Fahrerseite";
CM_ SG_ 1312 AB_Anprall_Heck_Beifahrer "Uebermittlung der Lage einer Kollision, Anprallzone Beifahrerseite hinten";
CM_ SG_ 1312 AB_Anprall_Heck_Fahrer "Uebermittlung der Lage einer Kollision, Anprallzone Fahrerseite hinten";
CM_ SG_ 1312 AB_Anprall_Rollover "Uebermittlung der Lage einer Kollision, Rollover erkannt";
CM_ SG_ 1312 AB_Anprall_Seite_Beifahrer "Uebermittlung der Lage einer Kollision, Anprallzone Beifahrerseite Seite";
CM_ SG_ 1312 AB_Anprall_Seite_Fahrer "Uebermittlung der Lage einer Kollision, Anprallzone Fahrerseite Seite";
CM_ SG_ 1312 AB_Belegung_VB "Belegungserkennung vorne Beifahrer. Wird in US-Steuergeräten über Bladder-Matte bedient, optional bei RdW, falls SBE_EuroNCAP entschieden wird.";
CM_ SG_ 1312 AB_Crashschwere "Übermittlung der Crashschwere an das Gateway (OBDC)";
CM_ SG_ 1312 AB_Gurtschloss_BF "Gurtschlossstatus Beifahrerseite";
CM_ SG_ 1312 AB_Gurtschloss_FA "Gurtschlosstatatus Fahrerseite";
CM_ SG_ 1312 AB_Gurtschloss_Reihe2_BF "Gurtschlossstatus 2. Reihe Beifahrerseite,  Mehrausstattung";
CM_ SG_ 1312 AB_Gurtschloss_Reihe2_FA "Gurtschlossstatus 2. Reihe Fahrerseite, Mehrausstattung";
CM_ SG_ 1312 AB_Gurtschloss_Reihe2_MI "Gurtschlossstatus 2. Reihe Mitte,  Mehrausstattung";
CM_ SG_ 1312 AB_Gurtschloss_Reihe3_BF "Gurtschlossstatus 3. Reihe Beifahrerseite,  Mehrausstattung";
CM_ SG_ 1312 AB_Gurtschloss_Reihe3_FA "Gurtschlossstatus 3. Reihe Fahrerseite,  Mehrausstattung";
CM_ SG_ 1312 AB_Gurtschloss_Reihe3_MI "Gurtschlossstatus 3. Reihe Mitte,  Mehrausstattung";
CM_ SG_ 1312 AB_Sitzpos_Sens_BF "Ausgabe Sitzposition Beifahrer";
CM_ SG_ 1312 AB_Sitzpos_Sens_FA "Ausgabe Sitzposition Fahrer";
CM_ SG_ 1312 AB_Wickelklappung_Reihe2_BF "Status Wickelklappung 2. Reihe Beifahrerseite, Mehrausstattung";
CM_ SG_ 1312 AB_Wickelklappung_Reihe2_FA "Status Wickelklappung 2. Reihe Fahrerseite, Mehrausstattung";
CM_ SG_ 1312 AB_Wickelklappung_Reihe2_MI "Status Wickelklappung 2. Reihe Mitte, Mehrausstattung";
CM_ SG_ 1312 Airbag_02_CRC "Für MLB:
'Berechnung siehe Lastenheft 'Kommunikationsabsicherung für FlexRay und CAN''

Ab MQB und MLBevo:
'Berechnung siehe Lastenheft 'End-to-End Kommunikationsabsicherung''

Endwerte siehe Begleitdokument 'S-PDU Kennungsfolgen'";
CM_ SG_ 1312 LoGeWa_Event_Kombiwarnung "Event für Kombiwarnung";
CM_ SG_ 1312 SC_PAO_OFF_Anf "Sollwert für LED 'OFF' in Anzeige Passenger Airbag On/Off";
CM_ SG_ 1312 SC_PAO_ON_Anf "Sollwert für LED 'ON' in Anzeige Passenger Airbag On/Off";
CM_ SG_ 1312 SC_PAO_Schriftzug_Anf "Sollwert für LED 'PASSENGER AIRBAG' in Anzeige Passenger Airbag On/Off";

CM_ SG_ 1349 AB_Anprall_Front "Uebermittlung der Lage einer Kollision, Anprallzone Front";
CM_ SG_ 1349 AB_Anprall_Heck "Uebermittlung der Lage einer Kollision, Anprallzone Heck";
CM_ SG_ 1349 AB_Belegung_VF_ext "Das Signal kommuniziert den Status des Sitzbelegsensors Fahrer incl. dauerhafter Zustände mit Signalqualität ASIL A.";
CM_ SG_ 1349 AB_Belegung_VF_ext_aktiv "Kennzeichnet aktive Funktion 'Erweiterte Sitzbelegdiagnose' für Signal AB_Belegung_VF_ext";
CM_ SG_ 1349 AB_Gurtwarn_Reihe2_BF "Status Gurtwarnung 2. Sitzreihe Beifahrerseite";
CM_ SG_ 1349 AB_Gurtwarn_Reihe2_FA "Status Gurtwarnung 2. Sitzreihe Fahrerseite";
CM_ SG_ 1349 AB_Gurtwarn_Reihe2_MI "Status Gurtwarnung 2. Sitzreihe Mitte";
CM_ SG_ 1349 AB_Gurtwarn_Reihe3_BF "Status Gurtwarnung 3. Sitzreihe Beifahrerseite";
CM_ SG_ 1349 AB_Gurtwarn_Reihe3_FA "Status Gurtwarnung 3. Sitzreihe Fahrerseite";
CM_ SG_ 1349 AB_Gurtwarn_Reihe3_MI "Status Gurtwarnung 3. Sitzreihe Mitte";
CM_ SG_ 1349 AB_Gurtwarn_Reihe4_BF "Status Gurtwarnung 4. Sitzreihe Beifahrerseite";
CM_ SG_ 1349 AB_Gurtwarn_Reihe4_FA "Status Gurtwarnung 4. Sitzreihe Fahrerseite";
CM_ SG_ 1349 AB_Gurtwarn_Reihe4_MI "Status Gurtwarnung 4. Sitzreihe Mitte";
CM_ SG_ 1349 AB_SBR_hinten_verbau "Verbauinformation Sitzbelegungssensor hinten (2. und 3. Sitzreihe)";
CM_ SG_ 1349 AbstWarn_MV_FAS_Fkt_Status "FAS-ProfileMaster Iststatus der Kundenfunktion";
CM_ SG_ 1349 Airbag_04_BZ "4bit Botschaftszähler, wird mit jeder Sendebotschaft inkrementiert";
CM_ SG_ 1349 Airbag_04_CRC "Für MLB:
Berechnung siehe Lastenheft 'Kommunikationsabsicherung für FlexRay und CAN'
Ab MQB und MLBevo:
Berechnung siehe Lastenheft 'End-to-End Kommunikationsabsicherung'

Endwerte siehe Begleitdokument 'S-PDU Kennungsfolgen'";
CM_ SG_ 1349 AWV_Einstellung_System_ASG "Signal zur Realisierung des BAP-Koordinators";
CM_ SG_ 1349 AWV_Einstellung_Warnung_ASG "Signal zur Realisierung des BAP-Koordinators";
CM_ SG_ 1349 LGI_FAS_Fkt_Status "FAS-ProfileMaster Iststatus der Kundenfunktion (LGI: Lokale Gefahreninformation)";
CM_ SG_ 1349 PreCrash_FAS_Fkt_Status "FAS-ProfileMaster Iststatus der Kundenfunktion";
CM_ SG_ 1349 SC_PreSense_Modus_System_KAS "BAP-Kommunikation zum Kreuzungsassistent";
CM_ SG_ 1349 SC_PreSense_Modus_System_MV "Signal zur Realisierung der BAP-Kommunikation für PreSense";
CM_ SG_ 1349 SC_PreSense_Modus_System_NV "Signal zur Realisierung der BAP-Kommunikation für PreSense";
CM_ SG_ 1349 SC_PreSense_Modus_Warnung_MV "Signal zur Realisierung der BAP-Kommunikation für PreSense";
CM_ SG_ 1349 SC_PreSense_Modus_Warnung_NV "Signal zur Realisierung der BAP-Kommunikation für PreSense";
CM_ SG_ 1349 WarnBrems_Charisma_FahrPr "Aktuell eingestelltes Fahrprogramm der Funktion Warn- und/oder Notbremsfunktion";
CM_ SG_ 1349 WarnBrems_Charisma_Status "Verfügbarkeit der Funktion Warn- und/oder Notbremsfunktion für die Ansteuerung durch den Charisma-Koordinator.";

CM_ SG_ 1633 AAG_Anhaenger_abgesteckt "Anhaenger wurde bei Kl. 15 aus abgesteckt";
CM_ SG_ 1633 AAG_Anhaenger_erkannt "Erkennung Anhaenger ";
CM_ SG_ 1633 AAG_AVS_Fehler_02 "Fehler AVS";
CM_ SG_ 1633 AAG_AVS_Fehler_02_inv "Fehler AVS (inverses Signal)";
CM_ SG_ 1633 AAG_AVS_Stati "Status AVS (bei abnehmbarer oder mech.schwenkbarer Anhängerkupplung ist der Status immer 0)";
CM_ SG_ 1633 AAG_Blinker_H_aktiv "Status: Anhaenger Blinker aktiv";
CM_ SG_ 1633 AAG_Blinker_HL_def "Anhaenger Blinker links defekt";
CM_ SG_ 1633 AAG_Blinker_HR_def "Anhaenger Blinker rechts defekt";
CM_ SG_ 1633 AAG_Bremsl_durch_ECD "Bremslicht durch ECD aktiv";
CM_ SG_ 1633 AAG_Bremslicht_H_def "Anhaenger Bremslicht defekt";
CM_ SG_ 1633 AAG_Bremslicht_Reku "AAG_Bremslicht_Reku meldet zyklisch den empfangenen Zustand des CAN-Signals MO_Bremslicht_Reku zurück.";
CM_ SG_ 1633 AAG_BZ "4bit-Botschaftszaehler, wird in jeder Sendebotschaft inkrementiert

";
CM_ SG_ 1633 AAG_LED_aktiv "Dieses Signal sendet der Beleuchtungsart des Anhängers (LED oder Lampe)
Bei LED aktiv erfolgt kein Kaltüberwachung";
CM_ SG_ 1633 AAG_NSL_aktiv "Anhaenger Nebelschlusslicht aktiv";
CM_ SG_ 1633 AAG_Schlusslicht_HL_def "Anhaenger Schlußlicht links defekt";
CM_ SG_ 1633 AAG_Schlusslicht_HR_def "Anhaenger Schlußlicht rechts defekt";

CM_ SG_ 345 ARA_Aktiver_Grafikmodus "Zeigt an  das eine Grafik für ARA aktiviert werden soll";
CM_ SG_ 345 ARA_Bremsfuss "Anforderung des Bremsfusssymbols im Kombi";
CM_ SG_ 345 ARA_Deaktivierung_sperren "Unterdrückt die Deaktivierung der ARA- Visualisierung";
CM_ SG_ 345 ARA_Knickwinkel_Ist "Gibt den aktuellen Knickwinkel zwischen Anhänger und Fahrzeug wieder";
CM_ SG_ 345 ARA_Knickwinkel_Komfort "Knickwinkelgrenze bis zu der, bei maximalem Lenkeinschlag, eine sofortige gerade Rückwärtsfahrt möglich ist.";
CM_ SG_ 345 ARA_Knickwinkel_Konfidenz "irregular trailer angle area value for HMI display";
CM_ SG_ 345 ARA_Knickwinkel_Max "Gibt den maximalen ausregelbaren Knickwinkel zwischen Anhänger und Fahrzeug wieder.";
CM_ SG_ 345 ARA_Knickwinkel_Soll "Vom Fahrer vorgegebener Knickwinkel.";
CM_ SG_ 345 ARA_Modus "Regelmodus ARA für Kombidarstellung";
CM_ SG_ 345 ARA_Modus_Anf "Anforderung des ARA-Modus im Türsteuergerät";
CM_ SG_ 345 ARA_Sensor_Aktivierung "activation  of ARA IP (image processing)";
CM_ SG_ 345 ARA_Status "Status of ARA Controller";
CM_ SG_ 345 ARA_Texte "Anforderung für Kombianzeigetexte und Akustik";

CM_ SG_ 2536734208 BAP_DrivingDynamics_ASG_01_Hdr "Allradkachel
Anzeigesteuergerät";

CM_ SG_ 2536734224 BAP_DrivingDynamics_FSG_01_Hdr "BAP Strecke für Allradkachel
Funktionssteuergerät";

CM_ SG_ 2536717312 BAP_EfficAssist_ASG_01_Header "BAP Data dummy";

CM_ SG_ 2536717313 BAP_EfficAssist_ASG_02_Header "EfficiencyAssist Anzeigesteuergeraet 2";

CM_ SG_ 2536717328 BAP_EfficAssist_FSG_01_Header "BAP dummy data";

CM_ SG_ 2536725760 BAP_EngFunctions_ASG_01_Header "EngineFunctions
Anzeigesteuergeraet";

CM_ SG_ 2536725776 BAP_EngFunctions_FSG_01_Header "EngineFunctions
Funktionssteuergeraet";

CM_ SG_ 1626 APS_Tongeber_defekt "Status APS-Tongeber zur HMI-Ansteuerng der RCTA-Funktion";
CM_ SG_ 1626 BCM1_AFS_Lampe "Ansteuerung der AFS-Fehlermeldung im Kombi";
CM_ SG_ 1626 BCM1_EasyEntry_Status "Status EasyEntry für Lenksäule (wird auch von IVB verwendet)";
CM_ SG_ 1626 BCM1_Fahrlicht_Hinweis "Signal zum Kombi um den Hinweis 'Bitte Fahrlicht einschalten' anzufordern";
CM_ SG_ 1626 BCM1_Hinweis_Lichtnachlauf "Signal dient der Anzeige eines aktiven Lichtnachlaufes beim automatischen Abschalten der Klemme S und Klemme 15. Der Lichtnachlauf wird gestartet, wenn die Klemme 15 bei aktivem Fahrlicht deaktiviert wird.";
CM_ SG_ 1626 BCM1_Kl_15_HW_erkannt "Erkennung Klemme 15 (Hardware) vom BCM1
";
CM_ SG_ 1626 BCM1_Kl_15_Sig_HW_erkannt "Erkennung Klemme 15 Signal (Hardware) vom BCM1";
CM_ SG_ 1626 BCM1_LDS_Stellung "Das Signal wird vom AFS / LWR Steuergerät empfangen und dient der Verifizierung der Lichtdrehschalterstellung. Intelligente Lichtfunktionen wie dyn. KL und gleitende Leuchtweite (GLW) nur bei LDS = 'AUTO'.";
CM_ SG_ 1626 BCM1_Lenksaeule_aktiv "Lenksaeulenverstellung aktiv";
CM_ SG_ 1626 BCM1_Licht_Warn "Lichtwarnung";
CM_ SG_ 1626 BCM1_Lichtwarn_Texte "Anforderung von Lichtwarnungen vom BCM1 zum Kombi
MLB: nur Werte 0..2";
CM_ SG_ 1626 BCM1_MH_Schalter "Motorhaubenkontakt";
CM_ SG_ 1626 BCM1_MH_WIV_Schalter "Bewerteter Motorhaubenkontakt fuer WIV";
CM_ SG_ 1626 BCM1_NV_Taster "BCM1_NV_Taster gibt an, ob der NightVision-Taster im Lichtdrehschalter-Modul aktuell betaetigt wird.";
CM_ SG_ 1626 BCM1_Reisemodus_Texte "Ansteuerung der Reisemodus-Texte im Kombi";
CM_ SG_ 1626 BCM1_Rueckfahrlicht_Schalter "Rückfahrlichtschalter
ab MQB/ MLBevo: Die Ganginformation wird unentprellt übertragen, im AT-Getriebe wird evtl. kurzzeitig der R-Gang angezeigt. Eine Entprellung muß im Empfänger erfolgen (typisch 400ms).";
CM_ SG_ 1626 BCM1_Spannungs_Anf "Forderung des BCM1-SG's zur Spannungsanhebung.";
CM_ SG_ 1626 BCM1_Valet_Parking_Taster "Valet Parking Taster ";
CM_ SG_ 1626 BCM1_Warnblink_Taster "Warnblinktaster";
CM_ SG_ 1626 BCM_Anf_AAW_MoLaWa "Signal zur Anforderung der Antrieb-Aktiv-Warnung und Motorlaufwarnung. Die Berechnung erfolgt im BCM. Die Ausgabe der Warnungen wird vom Kombiinstrument realisiert";
CM_ SG_ 1626 BCM_Bremsbelag_Sensor "Sensorsignal der Stromschleife  für Bremsbelagverschleiß aktuell, entstört, unbewertet";
CM_ SG_ 1626 BCM_Bremsfluessigkeit_Sensor "Kontaktsignal des Sensorschalters für die Bremsflüssigkeitsreserve aktuell, entstört, unbewertet";
CM_ SG_ 1626 BCM_Charisma_Taste2 "Betätigung der Charisma-Taste 2";
CM_ SG_ 1626 BCM_Eco_Charisma_Taste "Betätigung Taster ECO alias BlueKey oder Charisma";
CM_ SG_ 1626 BCM_Handbremse_Hinweis "Infotext fuer das Kombiinstrument zur Oeffnung der elektr. Heckklappe.";
CM_ SG_ 1626 BCM_HBFS_EOE_aktiv "Elektrisch-Oeffnen-Motor aktiv";
CM_ SG_ 1626 BCM_HDF_betaetigt "Betätigung Taster für Heckdeckelfernentriegelung in Mittelkonsole";
CM_ SG_ 1626 BCM_HFS_EOE_aktiv "Elektrisch-Oeffnen-Motor aktiv";
CM_ SG_ 1626 BCM_Hybrid_StartStopp_Taste "Betaetigung Taster 'Hybrid' oder alternativ Taster 'Start/Stopp Deaktivierung', je nach Verbau";
CM_ SG_ 1626 BCM_Hybrid_StSt_Taste_Fehler "Fehlerflag, wenn Tasterdiagnose im BCM für den StSt-Taster anschlägt.";
CM_ SG_ 1626 BCM_Kuehlmittel_Sensor "Signal der Sensorelektroden für die Kühlmittelreserve aktuell, entstört, bewertet (OK/Mangel)";
CM_ SG_ 1626 BCM_Kuehlmittel_Sensor_02 "Signal der zweiten Sensorelektroden für die Kühlmittelreserve aktuell, entstört, bewertet (OK/Mangel)";
CM_ SG_ 1626 BCM_Offroad_Taste "Betätigung der Offroad-Taste";
CM_ SG_ 1626 BCM_ValetTaster_Fkts_LED "Im MQB beschreibt das Signal nur den Zustand der Funktion Valet Parking (aktiv/ inaktiv)
Im MLBevo wird über das Signal zusätzlich die ValetTaster_Fkts_LED (an/ aus) gesteuert";
CM_ SG_ 1626 BCM_Waehlhebel_P_Hinweis "Infotext NAR für die Vorbedingung 'Waehlhebel in P' für Öffnen der Heckklappe über den Fahrerrauminnentaster.";
CM_ SG_ 1626 BCM_Waschwasser_Sensor "Signal der Sensorelektroden für die Waschwasserreserve aktuell, entstört, bewertet (OK/Mangel)";
CM_ SG_ 1626 DWA_Alarmquelle "Signalisiert den Auslösegrund der DWA";
CM_ SG_ 1626 DWA_Einschraenkung "Signalisiert Fehler der DWA";
CM_ SG_ 1626 Gong_TFL_Umschaltung "Aktivierung / Deaktivierung des TFL per Affengriff wird mit einem Gong im Kombi quittiert.";
CM_ SG_ 1626 LRH_Taster "Tasterbetätigung Lenkradheizung";

CM_ SG_ 869 BEM_Anf_KL "Das BEM fordert über das MSG den Kühlerlüfter-Betrieb an; hierzu wird ein minimaler Leistungswert im MSG appliziert. 
Szenario: bei erkannter abgetrennten Batterie soll durch Ansteuerung des Kühlerlüfters das Energienetz stabilisiert werden.";
CM_ SG_ 869 BEM_Batt_Ab "Batterieverbindungskontrolle:
0x0: Batterie am Bordnetz
0x1: Batterie ab erkannt";
CM_ SG_ 869 BEM_DFM "Generatorauslastungsgrad, vom Generator über LIN an das Gateway gesandt. Das Motorsteuergerät regelt auf dieses Signal die PTC, das Energiemanagement im BSG/BCM kalkuliert die Bordnetzauslastung";
CM_ SG_ 869 BEM_EMLIN_ungueltig "Energie-Lin - Signale sind ungültig vom Slave Batteriedatenmodul oder Generator
0 = Signale gültig
1 = Signale ungültig";
CM_ SG_ 869 BEM_HYB_DC_uMinLV "Abregelgrenze: minimal erlaubte Bordnetzspannung im Hochsetzbetrieb (Hybrid)";
CM_ SG_ 869 BEM_HYB_DC_uSollLV "Sollwert für die Bordnetzspannung im Tiefsetzbetrieb vom Traktionsnetz ins Bordnetz (Hybrid)";
CM_ SG_ 869 BEM_n_LLA "Es gilt: Signalspec BEM_n_LLA v1.0

Anforderung einer Leerlaufdrehzahlanhebung in drei Stufen. Die Höhe der jeweiligen LL-Drehzahlstufe ist im Motorsteuergerät appliziert.



";
CM_ SG_ 869 BEM_P_Generator "Es gilt: Signalspec BEM_P_Generator v1.0

Mechanische Generatorleistung dient dem Motorsteuergerät zur Berechnung der Motorlast; Genauigkeit ca. +/- (500W + 20% vom Messwert)

MLBevo: Bei NVEM_P_Generator_Status = 1 wird das Signal ohne Filterung ausg";
CM_ SG_ 869 BEM_Segel_Info "0: keine Anforderung 
(Segeln ist ohne Einschänkung erlaubt)
1: Mindestdrehzahl 1 
(Segeln ist mit Einschänkung erlaubt)
2: Mindestdrehzahl 2
(Segeln ist mit Einschänkung erlaubt)
3: Segelveto
(Segeln ist nicht  erlaubt)";
CM_ SG_ 869 BEM_StartStopp_Info "Stopp-Freigabe und Start-Anforderung an den Start-Stopp-Koordinator";
CM_ SG_ 869 BEM_UBDM "Batteriespannung, gemessen vom Batteriedatenmodul";
CM_ SG_ 869 NVEM_Abschaltstufe "Abschaltstufe aus dem Ruheenergiemanagement
Maßnahmen des Empfängers werden im QLAH Ruhestrommanagement definiert";
CM_ SG_ 869 NVEM_FMAus_I_Verbrauch "Predezierter Bordneztstromverbrauch während der Freilauf Motor Aus Phase.";
CM_ SG_ 869 NVEM_FMAus_Info "Freilauf Informationssignal zum Freilaufkoordinator. 
Gilt nur für die Freilauf Phase. Verwendung im MicroHybrid.";
CM_ SG_ 869 NVEM_Freilauf_Info "Freilauf Informationssignal vom NVEM zum Freilaufkoordinator. Das NVEM kann über dieses Signal den Freilauf freigeben, verhindern bzw. explizit anfordern.";
CM_ SG_ 869 NVEM_Ladefreigabe "Freigabeemfehlung zur Ladung des FMA-Zusatzspeichers";
CM_ SG_ 869 NVEM_P_Generator_Status "Das Signal kennzeichnet ob BEM_P_Generator aktuell gefilterte oder ungefilterte Werte überträgt.";
CM_ SG_ 869 NVEM_PTC_Sollstufe "Vorgabe des BEM an das BCM zur Aktivierung der geforderten PTC - Stufe.
Das MSG kopiert dies auf das Signal MO_PTC_Status";
CM_ SG_ 869 NVEM_Red_KL "Reduzierung der Kühlerlüfteranforderung durch das NVEM an das MSG bei energetisch kritischen Zuständen während Staupilot";

CM_ SG_ 1163 BEM_06_BZ "4bit Botschaftszähler, wird mit jeder Sendebotschaft inkrementiert";
CM_ SG_ 1163 BEM_06_CRC "Für MLB:
Berechnung siehe Lastenheft 'Kommunikationsabsicherung für FlexRay und CAN'
Ab MQB und MLBevo:
Berechnung siehe Lastenheft 'End-to-End Kommunikationsabsicherung'

Endwerte siehe Begleitdokument 'S-PDU Kennungsfolgen'";
CM_ SG_ 1163 HLR_PTC_linear_Freigabe "Freigabe des EEM für den linearen PTC-Zuheizer";
CM_ SG_ 1163 NVEM2_Status_FuSiFahrt "Status sicherheitsrelevante Diagnosen NVEM";
CM_ SG_ 1163 NVEM2_Typ_EnergieNetz "Identifizierte NV-Energiearchitektur";
CM_ SG_ 1163 NVEM_Betriebsart "Betriebsart des Niedervolt - Energiemanagements";
CM_ SG_ 1163 NVEM_Bordnetzdiagnose "Wird vom NVEM im NV-Netz ein Bordnetz-Fehler erkannt, so soll dies zu einer mehrstufigen Anzeige führen.";
CM_ SG_ 1163 NVEM_Energie_Klima_Vorgabe "NVEM-Energievorgabe für Klima-Vorkonditionierung";
CM_ SG_ 1163 NVEM_Energienetz_Status "NVEM kommuniziert abgesichert den Zustand des Energienetzes.";
CM_ SG_ 1163 NVEM_Ladezustand "Ladezustand des NV-Hauptspeichers.";
CM_ SG_ 1163 NVEM_Last_Anf "Das NVEM fordert für die Batteriediagnose einen Lastimpuls vom Fahrzeug an, der durch kontrollierte Verbraucherzuschaltungen (z. B. Aktivierung Heckscheibenheizung) generiert wird";
CM_ SG_ 1163 NVEM_PTC_Sollstufe "Vorgabe des BEM an das BCM zur Aktivierung der geforderten PTC - Stufe.
Das MSG kopiert dies auf das Signal MO_PTC_Status";
CM_ SG_ 1163 NVEM_Red_KomfortVerbrauch "Master - SubMaster Kommunikation";
CM_ SG_ 1163 NVEM_STH_ZielzeitLang "Energetisch erlaubte Betriebszeit im Zielzeitkonzept für Standheizungen mit 2 Stunden Laufzeit";
CM_ SG_ 1163 NVEM_Vorgabe_Leistungsstufe "Ermittelte Leistungsstufe der Energiequelle";

CM_ SG_ 2463978850 BEM_07_BZ "4bit Botschaftszähler, wird mit jeder Sendebotschaft inkrementiert";
CM_ SG_ 2463978850 BEM_07_CRC "Für MLB:
Berechnung siehe Lastenheft 'Kommunikationsabsicherung für FlexRay und CAN'
Ab MQB und MLBevo:
Berechnung siehe Lastenheft 'End-to-End Kommunikationsabsicherung'

Endwerte siehe Begleitdokument 'S-PDU Kennungsfolgen'";
CM_ SG_ 2463978850 NVEM2_VerbrZustandsAnf "Dieses Signal soll bei FuSi-relevanten Energienotsituationen die Reaktion bei den Nichtdynamischen Verbrauchern auslösen.";
CM_ SG_ 2463978850 NVEM3_Absch_SCR "Abschaltung der SCR-Heizung durch das NVEM bei energetisch kritischen Zuständen.";
CM_ SG_ 2463978850 NVEM_Batt_Temp_Hinweis "Anforderung Kühlungsunterstützung der NV - Batterie";
CM_ SG_ 2463978850 NVEM_Bordnetz_Information "Informationsanzeigen zum 12V - Bordnetz";
CM_ SG_ 2463978850 NVEM_NVStuetzungAnf "Aktivierung / Deaktivierung Primärenergieversorger";
CM_ SG_ 2463978850 NVEM_Verbraucher_Information "Mit diesem Signal löst Das NVM eine Anzeige bzgl. einer bevorstehenden oder erfolgten Verbraucherabschaltung aus";

CM_ SG_ 1442 BMS_04_CRC "Für MLB:
'Berechnung siehe Lastenheft 'Kommunikationsabsicherung für FlexRay und CAN''

Ab MQB und MLBevo:
'Berechnung siehe Lastenheft 'End-to-End Kommunikationsabsicherung''

Endwerte siehe Begleitdokument 'S-PDU Kennungsfolgen'";
CM_ SG_ 1442 BMS_Fehler_Pilot "Signalisiert den Status der Pilotlinie BMS.";
CM_ SG_ 1442 BMS_Fehlerlampe_Anf "Anforderung der roten Hybrid-Warnlampe im Kombi";
CM_ SG_ 1442 BMS_Fehlerstatus "aktueller Fehlerstatus der Batterie";
CM_ SG_ 1442 BMS_Kapazitaet_02 "Nutzbare Kapazität der Batterie,
oder alterungsabhängige absolute Gesamtkapazität der Batterie.

Projektabhängig kann die Kapazität auf das nutzbare SOC-Fenster (zwischen oberer und unterer SOC-Grenze) bezogen sein, wobei sich dieses SOC-Fenster alteru";
CM_ SG_ 1442 BMS_Kl30c_Status "Stecker-Zustand des Service-Disconnect (Klemme 30c)";
CM_ SG_ 1442 BMS_OBD_Lampe_Anf "Anforderung MIL (MalfunctionIndicationLamp) von BMS (Motorsteuergerät reicht diese Info an Kombi weiter).";
CM_ SG_ 1442 BMS_Status_ServiceDisconnect "Status des Service Disconnect, ob dieser gesteckt oder gezogen ist.
Abhängigkeiten zu anderen Signalen: BMS_Fehler_Sicherung und BMS_Fehler_Pilot";
CM_ SG_ 1442 BMS_Status_Spgfreiheit "0=Init (ohne Funktion)
1=BMS Zwischenkreis spannungsfrei (U_Zwkr < 20V)
2=BMS Zwischenkreis nicht spannungsfrei (U_Zwkr >/= 25V, Hysterese)
3=Fehler (z.B. Fehler in der Sensorik)";
CM_ SG_ 1442 BMS_Warnlampe_Anf "Anforderung der gelben Hybrid-Warnlampe im Kombi";

CM_ SG_ 1450 SOK_BMS_04_Signatur "Signatur im Rahmen der durch SOK geschützen Broadcast-Kommunikation

Geschützte Funktion: OBD-Malfunction Indicator Light (MIL)
Geschützte PDU: BMS_04";

CM_ SG_ 1482 BMS_07_CRC "Für MLB:
'Berechnung siehe Lastenheft 'Kommunikationsabsicherung für FlexRay und CAN''

Ab MQB und MLBevo:
'Berechnung siehe Lastenheft 'End-to-End Kommunikationsabsicherung''

Endwerte siehe Begleitdokument 'S-PDU Kennungsfolgen'";
CM_ SG_ 1482 BMS_Ausgleichsladung_Anf "BMS wünscht eine Ausgleichsladung
Flag derzeit ungenutzt, da BalancingModus im Detail noch nicht geklärt.";
CM_ SG_ 1482 BMS_Balancing_Aktiv "Signal zeigt an, ob mindestens eine Zelle der HV Batterie balanciert wird";
CM_ SG_ 1482 BMS_Batteriediagnose "Anzeige von Textwarnungen";
CM_ SG_ 1482 BMS_Energieinhalt "aktuell nutzbarer Energieinhalt der HV-Batterie
(bezogen auf ein definiertes mittleres Belastungsprofil)";
CM_ SG_ 1482 BMS_Gesamtst_Spgfreiheit "0 = Funktion nicht aktiviert
1 = HV-System spannungsfrei (U_Zwkr von BMS, LE und Ladegerät < 20V, DCLadestecker nicht gesteckt und Service Disconnect entriegelt)
2 = HV-System nicht spannungsfrei (U_Zwkr von BMS, LE und Ladegerät >= 20V, Ladestecker ges";
CM_ SG_ 1482 BMS_KundenWarnung "Kundenwarnung und Ersatzreaktionen aufgrund von Batteriebrandgefahr";
CM_ SG_ 1482 BMS_Ladevorgang_aktiv "Signalisiert aktiven Ladevorgang, Ladegerät und DC/DC aktiv.
Signal bleibt nach Kl.15 ein aktiv, bis ESP_Stillstandsflag gelöscht.

Abhängigkeit zu BMS_Energieinhalt";
CM_ SG_ 1482 BMS_MaxEnergieinhalt "maximaler nutzbarer Energieinhalt der HV-Batterie (bezogen auf Last KBI_RWDS_Lastprofil bei SOC=100%)
Abhängig von KBI_RWDS_Lastprofil";
CM_ SG_ 1482 BMS_RIso_Ext "Minimum des Isolationswiderstands zwischen Batteriegehäuse und HV+ bzw. Batteriegehäuse und HV- bei geschlossenen Schützen (externe Iso Messung)";

CM_ SG_ 2527679654 BMS_11_BZ "4bit Botschaftszähler, wird mit jeder Sendebotschaft inkrementiert";
CM_ SG_ 2527679654 BMS_11_CRC "Für MLB:
Berechnung siehe Lastenheft 'Kommunikationsabsicherung für FlexRay und CAN'
Ab MQB und MLBevo:
Berechnung siehe Lastenheft 'End-to-End Kommunikationsabsicherung'

Endwerte siehe Begleitdokument 'S-PDU Kennungsfolgen'";
CM_ SG_ 2527679654 BMS_IsoFehler "Ergebnis der Isolationsmessung des BMS";
CM_ SG_ 2527679654 BMS_IsoZustand "Ergebnis des aktuellen/letzten Isolations-Meßzyklus: Messung läuft; Messung Batterie-intern oder Gesamtsystem; gemessener Wert unterschreitet Schwelle 1 / Schwelle 2.";
CM_ SG_ 2527679654 BMS_IstTemperatur_hoechste "aktuell höchste Temperatur in der Batterie";
CM_ SG_ 2527679654 BMS_IstTemperatur_niedrigste "aktuell niedrigsteTemperatur in der Batterie";
CM_ SG_ 2527679654 BMS_IstZellspannung_hoechste "höchster Wert aller Zellspannungen im BMS";
CM_ SG_ 2527679654 BMS_IstZellspannung_niedrigste "niedrigster Wert aller Zellspannungen im BMS";

CM_ SG_ 207 BMS_20_BZ "4bit Botschaftszähler, wird mit jeder Sendebotschaft inkrementiert";
CM_ SG_ 207 BMS_20_CRC "Für MLB:
Berechnung siehe Lastenheft 'Kommunikationsabsicherung für FlexRay und CAN'
Ab MQB und MLBevo:
Berechnung siehe Lastenheft 'End-to-End Kommunikationsabsicherung'

Endwerte siehe Begleitdokument 'S-PDU Kennungsfolgen'";
CM_ SG_ 207 BMS_ErwGrenzen_aktiv "die aktuellen Stromgrenzen der HV-Batterie sind zum Start des Verbrennungsmotors aufgeweitet / Bestätigung der Anforderung";
CM_ SG_ 207 BMS_Fehler_HVBattAbschaltung "Fehler: Fehlerzustand, erfordert das Öffnen der Batterieschütze
interner Batteriefehler, Batterieschütze ohne Vorankündigung durch das BMS geöffnet";
CM_ SG_ 207 BMS_Fehler_HVBattAbschaltung_Anf "Fehler: Fehlerzustand, erfordert das Öffnen der Batterieschütze
interner Batteriefehler; Vorankündigung eines bevorstehenden Öffnens der Batterieschütze durch das BMS";
CM_ SG_ 207 BMS_Fehler_Leistungsred "Fehler: Leistungsfähigkeit der Batterie ist eingeschränkt (z.B. aufgrund des Ausfalls von Sensoren oder des Lüfters)";
CM_ SG_ 207 BMS_Fehler_Notabschaltung_Crash "Fehler: Sicherheitskritischer Fehler (Crash-Erkennung)
Batterieschütze sind bereits geöffnet / werden sofort geöffnet
Signal wird direkt vom EMS gelesen und initiiert einen AKS des PWR und eine aktive Entladung des Zwischenkreises";
CM_ SG_ 207 BMS_Fehlerstatus_HV_Schuetze "Fehlerstatus der HV-Schütze, Verschweißt-Erkennung";
CM_ SG_ 207 BMS_HVIL_Status "Signalstatus HVIL/Pilotlinie";
CM_ SG_ 207 BMS_IstModus "Aktueller Betriebsmodus der Batterie
0: Standby; Schuetze geoeffnet; Kommunikation aktiv
1: Hauptschuetze geschlossen / HV-Netz aktiviert / normaler Fahrbetrieb
2: projektabhaengig belegt (z.B. Balancing, erweitertes DC-Schnelladen)
3: externes Laden ";
CM_ SG_ 207 BMS_Spannung "Aktuelle Spannung der Batterie.
Innerhalb der Batterie an den Zellmodulen gemessen, also _vor_ den Schützen und der Sicherung.";
CM_ SG_ 207 BMS_Spannung_Zwischenkreis "Aktuelle Spannung an den Batterie-HV-Anschlüssen; Abgang der Batterie zum Zwischenkreis / HV-Bordnetz / zur Leistungselektronik.";
CM_ SG_ 207 BMS_Strom "Aktueller Strom der Batterie.
Stromrichtung: Ladestrom wird mit positiven, Entladestrom mit negativen Werten angegeben.";

CM_ SG_ 2463978704 BMS_Max_Entladeleistung "Maximale Leistung, mit der die Batterie momentan belastet werden darf. 
Kurze Überschwinger aufgrund dynamischen Verhalten des Reglers sind nach Absprache möglich, aber
hierbei muss unbedingt auch der maximale Entladestrom berücksichtigt werden.";
CM_ SG_ 2463978704 BMS_Max_Entladestrom "Zwingend einzuhaltender Grenzwert für den Entladestrom der Batterie.
Darf aus Bauteilschutzgründen nicht überschritten werden.
Aus Lebensdauersicht muss zusätzlich die Leistungsgrenze eingehalten werden.";
CM_ SG_ 2463978704 BMS_Max_Ladeleistung "Maximale Leistung, mit der die Batterie aktuell geladen werden darf. 
Kurze Überschwinger aufgrund dynamischen Verhalten des Reglers sind nach Absprache möglich, aber
hierbei muss unbedingt auch der maximale Ladestrom berücksichtigt werden.";
CM_ SG_ 2463978704 BMS_Max_Ladestrom "Zwingend einzuhaltender Grenzwert für den Ladestrom der Batterie.
Darf aus Bauteilschutzgründen nicht überschritten werden.
Aus Lebensdauersicht muss zusätzlich die Leistungs- und SOC-Grenze eingehalten werden.";

BA_DEF_  "DBName" STRING;
BA_DEF_  "GenNWMApBusSleep" STRING;
BA_DEF_  "GenNWMApCanNormal" STRING;
BA_DEF_  "GenNWMApCanOff" STRING;
BA_DEF_  "GenNWMApCanOn" STRING;
BA_DEF_  "GenNWMApCanSleep" STRING;
BA_DEF_  "GenNWMApCanWakeUp" STRING;
BA_DEF_  "GenNWMGotoMode_Awake" STRING;
BA_DEF_  "GenNWMGotoMode_BusSleep" STRING;
BA_DEF_  "GenNWMSleepTime" INT 0 1000000;
BA_DEF_  "GenNWMTalkNM" STRING;
BA_DEF_  "Manufacturer" STRING;
BA_DEF_  "NmhBaseAddress" HEX 0 536870911;
BA_DEF_  "NmhMessageCount" INT 0 1024;
BA_DEF_  "NmType" STRING;
BA_DEF_  "VAGTP20_SetupMessageCount" INT 0 255;
BA_DEF_  "VAGTP20_SetupStartAddress" HEX 0 2047;
BA_DEF_  "VersionDay" INT 1 31;
BA_DEF_  "VersionMonth" INT 1 12;
BA_DEF_  "VersionWeek" INT 1 52;
BA_DEF_  "VersionYear" INT 0 99;
BA_DEF_  "VersionNumber" INT 0 65535;
BA_DEF_  "BusType" STRING;
BA_DEF_  "Baudrate" INT 1 1000000;
BA_DEF_  "BaudrateCANFD" INT 1 16000000;
BA_DEF_  "NmhTimeoutTimer" INT 0 65535;
BA_DEF_  "NmhWaitBusSleepTimer" INT 0 65535;
BA_DEF_  "NmhPrepareBusSleepTimer" INT 0 65535;
BA_DEF_  "NmhLongTimer" INT 0 65535;
BA_DEF_  "NmhNStart" INT 0 255;
BA_DEF_ BU_  "GenNodAutoGenDsp" ENUM "No", "Yes";
BA_DEF_ BU_  "GenNodAutoGenSnd" ENUM "No", "Yes";
BA_DEF_ BU_  "GenNodSleepTime" INT 0 1000000;
BA_DEF_ BU_  "ILUsed" ENUM "No", "Yes";
BA_DEF_ BU_  "ECUVariantDefault" ENUM "No", "Yes";
BA_DEF_ BU_  "ECUVariantGroup" STRING;
BA_DEF_ BU_  "NodeLayerModules" STRING;
BA_DEF_ BU_  "NmhNode" ENUM "No", "Yes";
BA_DEF_ BU_  "NmNode" ENUM "No", "Yes";
BA_DEF_ BU_  "SamplePointMin" FLOAT 50.0 99.9;
BA_DEF_ BU_  "SamplePointMax" FLOAT 50.0 99.9;
BA_DEF_ BU_  "SyncJumpWidthMin" FLOAT 0.0 50.0;
BA_DEF_ BU_  "SyncJumpWidthMax" FLOAT 0.0 50.0;
BA_DEF_ BU_  "SyncJumpWidthCANFDMin" FLOAT 0.0 50.0;
BA_DEF_ BU_  "SyncJumpWidthCANFDMax" FLOAT 0.0 50.0;
BA_DEF_ BU_  "SamplePointCANFDMin" FLOAT 50.0 99.9;
BA_DEF_ BU_  "SamplePointCANFDMax" FLOAT 50.0 99.9;
BA_DEF_ BU_  "SSPOffsetCANFDMin" FLOAT 50.0 99.9;
BA_DEF_ BU_  "SSPOffsetCANFDMax" FLOAT 50.0 99.9;
BA_DEF_ BU_  "TimeQuantaMin" INT 4 257;
BA_DEF_ BU_  "TimeQuantaMax" INT 4 257;
BA_DEF_ BU_  "TimeQuantaCANFDMin" INT 4 257;
BA_DEF_ BU_  "TimeQuantaCANFDMax" INT 4 257;
BA_DEF_REL_ BU_SG_REL_  "GenSigTimeoutTime" INT 0 65535;
BA_DEF_ BO_  "DiagRequest" ENUM "No", "Yes";
BA_DEF_ BO_  "DiagResponse" ENUM "No", "Yes";
BA_DEF_ BO_  "DiagState" ENUM "No", "Yes";
BA_DEF_ BO_  "GenMsgChkConstant" HEX 0 4095;
BA_DEF_ BO_  "GenMsgCycleTime" INT 0 65535;
BA_DEF_ BO_  "GenMsgCycleTimeFast" INT 0 65535;
BA_DEF_ BO_  "GenMsgDelayTime" INT 0 100000;
BA_DEF_ BO_  "GenMsgILSupport" ENUM "No", "Yes";
BA_DEF_ BO_  "GenMsgNrOfRepetition" INT 0 100;
BA_DEF_ BO_  "GenMsgPDUConstants" STRING;
BA_DEF_ BO_  "GenMsgSendType" ENUM "Cyclic", "not_used", "not_used", "not_used", "not_used", "not_used", "not_used", "IfActive", "NoMsgSendType";
BA_DEF_ BO_  "GenMsgStartDelayTime" INT 0 100000;
BA_DEF_ BO_  "NmMessage" ENUM "No", "Yes";
BA_DEF_ BO_  "NmhMessage" ENUM "No", "Yes";
BA_DEF_ BO_  "MsgType" ENUM "Application", "NM ", "NMH", "TP2.0", "ISO-TP ", "BAP", "EID", "KS", "XCP_PRE_CONFIGURED", "XCP_RUNTIME_CONFIGURED";
BA_DEF_ BO_  "VAGTP20_API" HEX 0 255;
BA_DEF_ BO_  "VAGTP20_DynConnection" ENUM "No", "Yes";
BA_DEF_ BO_  "VAGTP20_DynSetup" ENUM "No", "Yes";
BA_DEF_ BO_  "VAGTP20_StatConnection" ENUM "No", "Yes";
BA_DEF_ BO_  "CANFD_BRS" ENUM "0", "1";
BA_DEF_ BO_  "VFrameFormat" ENUM "StandardCAN", "ExtendedCAN", "reserved", "reserved", "reserved", "reserved", "reserved", "reserved", "reserved", "reserved", "reserved", "reserved", "reserved", "reserved", "StandardCAN_FD", "ExtendedCAN_FD";
BA_DEF_ SG_  "GenSigActiveRepetitions" INT -2147483648 2147483647;
BA_DEF_ SG_  "GenSigInactiveValue" INT -2147483648 2147483647;
BA_DEF_ SG_  "GenSigSendType" ENUM "Cyclic", "OnWrite", "OnWriteWithRepetition", "OnChange", "OnChangeWithRepetition", "IfActive", "IfActiveWithRepetition", "NoSigSendType", "OnChangeAndIfActive", "OnChangeAndIfActiveWithRepetition";
BA_DEF_ SG_  "GenSigStartValue" INT -2147483648 2147483647;
BA_DEF_ SG_  "NWM-WakeupAllowed" ENUM "No", "Yes";
BA_DEF_ SG_  "GenSigFuncType" ENUM "NoFunction", "MsgCounter", "CRC-8", "XOR", "XOR-2", "DatedBit", "SW-Kl15", "CHK", "Constant", "Protocol", "CRC-8-SAE_J1850", "CRC-32", "DataLength", "DataID", "MsgCounter16", "SOK-Signatur", "Cluster";
BA_DEF_ SG_  "GenSigSwitchedByIgnition" ENUM "No", "Yes";
BA_DEF_ SG_  "Fehlerwert" HEX 0 2147483647;
BA_DEF_ SG_  "GenSigMissingSourceValue" HEX 0 2147483647;
BA_DEF_DEF_  "DBName" "";
BA_DEF_DEF_  "GenNWMApBusSleep" "";
BA_DEF_DEF_  "GenNWMApCanNormal" "";
BA_DEF_DEF_  "GenNWMApCanOff" "";
BA_DEF_DEF_  "GenNWMApCanOn" "";
BA_DEF_DEF_  "GenNWMApCanSleep" "";
BA_DEF_DEF_  "GenNWMApCanWakeUp" "";
BA_DEF_DEF_  "GenNWMGotoMode_Awake" "";
BA_DEF_DEF_  "GenNWMGotoMode_BusSleep" "";
BA_DEF_DEF_  "GenNWMSleepTime" 0;
BA_DEF_DEF_  "GenNWMTalkNM" "";
BA_DEF_DEF_  "Manufacturer" "";
BA_DEF_DEF_  "NmhBaseAddress" 0;
BA_DEF_DEF_  "NmhMessageCount" 1;
BA_DEF_DEF_  "NmType" "None";
BA_DEF_DEF_  "VAGTP20_SetupMessageCount" 0;
BA_DEF_DEF_  "VAGTP20_SetupStartAddress" 0;
BA_DEF_DEF_  "VersionDay" 12;
BA_DEF_DEF_  "VersionMonth" 6;
BA_DEF_DEF_  "VersionWeek" 24;
BA_DEF_DEF_  "VersionYear" 23;
BA_DEF_DEF_  "VersionNumber" 0;
BA_DEF_DEF_  "BusType" "";
BA_DEF_DEF_  "Baudrate" 500000;
BA_DEF_DEF_  "BaudrateCANFD" 2000000;
BA_DEF_DEF_  "NmhTimeoutTimer" 0;
BA_DEF_DEF_  "NmhWaitBusSleepTimer" 0;
BA_DEF_DEF_  "NmhPrepareBusSleepTimer" 0;
BA_DEF_DEF_  "NmhLongTimer" 0;
BA_DEF_DEF_  "NmhNStart" 0;
BA_DEF_DEF_  "GenNodAutoGenDsp" "Yes";
BA_DEF_DEF_  "GenNodAutoGenSnd" "Yes";
BA_DEF_DEF_  "GenNodSleepTime" 0;
BA_DEF_DEF_  "ILUsed" "Yes";
BA_DEF_DEF_  "ECUVariantDefault" "Yes";
BA_DEF_DEF_  "ECUVariantGroup" "";
BA_DEF_DEF_  "NodeLayerModules" "";
BA_DEF_DEF_  "NmhNode" "Yes";
BA_DEF_DEF_  "NmNode" "No";
BA_DEF_DEF_  "SamplePointMin" 75;
BA_DEF_DEF_  "SamplePointMax" 75;
BA_DEF_DEF_  "SyncJumpWidthMin" 50;
BA_DEF_DEF_  "SyncJumpWidthMax" 50;
BA_DEF_DEF_  "SyncJumpWidthCANFDMin" 50;
BA_DEF_DEF_  "SyncJumpWidthCANFDMax" 50;
BA_DEF_DEF_  "SamplePointCANFDMin" 75;
BA_DEF_DEF_  "SamplePointCANFDMax" 75;
BA_DEF_DEF_  "SSPOffsetCANFDMin" 75;
BA_DEF_DEF_  "SSPOffsetCANFDMax" 75;
BA_DEF_DEF_  "TimeQuantaMin" 160;
BA_DEF_DEF_  "TimeQuantaMax" 160;
BA_DEF_DEF_  "TimeQuantaCANFDMin" 40;
BA_DEF_DEF_  "TimeQuantaCANFDMax" 40;
BA_DEF_DEF_REL_  "GenSigTimeoutTime" 0;
BA_DEF_DEF_  "DiagRequest" "No";
BA_DEF_DEF_  "DiagResponse" "No";
BA_DEF_DEF_  "DiagState" "No";
BA_DEF_DEF_  "GenMsgChkConstant" 0;
BA_DEF_DEF_  "GenMsgCycleTime" 0;
BA_DEF_DEF_  "GenMsgCycleTimeFast" 0;
BA_DEF_DEF_  "GenMsgDelayTime" 0;
BA_DEF_DEF_  "GenMsgILSupport" "No";
BA_DEF_DEF_  "GenMsgNrOfRepetition" 0;
BA_DEF_DEF_  "GenMsgPDUConstants" "";
BA_DEF_DEF_  "GenMsgSendType" "NoMsgSendType";
BA_DEF_DEF_  "GenMsgStartDelayTime" 0;
BA_DEF_DEF_  "NmMessage" "No";
BA_DEF_DEF_  "NmhMessage" "No";
BA_DEF_DEF_  "MsgType" "Application";
BA_DEF_DEF_  "VAGTP20_API" 0;
BA_DEF_DEF_  "VAGTP20_DynConnection" "No";
BA_DEF_DEF_  "VAGTP20_DynSetup" "No";
BA_DEF_DEF_  "VAGTP20_StatConnection" "No";
BA_DEF_DEF_  "CANFD_BRS" "1";
BA_DEF_DEF_  "VFrameFormat" "StandardCAN";
BA_DEF_DEF_  "GenSigActiveRepetitions" 0;
BA_DEF_DEF_  "GenSigInactiveValue" 0;
BA_DEF_DEF_  "GenSigSendType" "NoSigSendType";
BA_DEF_DEF_  "GenSigStartValue" 0;
BA_DEF_DEF_  "NWM-WakeupAllowed" "No";
BA_DEF_DEF_  "GenSigFuncType" "NoFunction";
BA_DEF_DEF_  "GenSigSwitchedByIgnition" "Yes";
BA_DEF_DEF_  "Fehlerwert" 0;
BA_DEF_DEF_  "GenSigMissingSourceValue" 0;
BA_  "DBName" "ACANFD";
BA_  "GenNWMApBusSleep" "NMIndNetSDN()";
BA_  "GenNWMApCanNormal" "apCanNormal()";
BA_  "GenNWMApCanOff" "NMIndnetOff()";
BA_  "GenNWMApCanOn" "NMIndnetOn()";
BA_  "GenNWMApCanSleep" "apCanSleep()";
BA_  "GenNWMApCanWakeUp" "apCanWakeUp()";
BA_  "GenNWMGotoMode_Awake" "Nmh_ReqNetOn()";
BA_  "GenNWMGotoMode_BusSleep" "Nmh_ReqNetOff()";
BA_  "GenNWMSleepTime" 4000;
BA_  "GenNWMTalkNM" "Nmh_ReqNetOn()";
BA_  "Manufacturer" "VAG";
BA_  "NmhBaseAddress" 452984832;
BA_  "NmhMessageCount" 1024;
BA_  "NmType" "NM-High";
BA_  "VAGTP20_SetupMessageCount" 128;
BA_  "VAGTP20_SetupStartAddress" 512;
BA_  "VersionNumber" 9;
BA_  "BusType" "CAN FD";
BA_  "NmhTimeoutTimer" 1000;
BA_  "NmhWaitBusSleepTimer" 750;
BA_  "NmhPrepareBusSleepTimer" 500;
BA_  "NmhLongTimer" 200;
BA_  "NmhNStart" 20;
BA_ "GenNodSleepTime" BU_ BAP_Tester 4000;
BA_ "ECUVariantGroup" BU_ BAP_Tester "BAP";
BA_ "NmhNode" BU_ BAP_Tester 0;
BA_ "SamplePointMin" BU_ BAP_Tester 80;
BA_ "SamplePointMax" BU_ BAP_Tester 80;
BA_ "SyncJumpWidthMin" BU_ BAP_Tester 16;
BA_ "SyncJumpWidthMax" BU_ BAP_Tester 16;
BA_ "SyncJumpWidthCANFDMin" BU_ BAP_Tester 6;
BA_ "SyncJumpWidthCANFDMax" BU_ BAP_Tester 6;
BA_ "SamplePointCANFDMin" BU_ BAP_Tester 70;
BA_ "SamplePointCANFDMax" BU_ BAP_Tester 70;
BA_ "SSPOffsetCANFDMin" BU_ BAP_Tester 70;
BA_ "SSPOffsetCANFDMax" BU_ BAP_Tester 70;
BA_ "TimeQuantaMin" BU_ BAP_Tester 80;
BA_ "TimeQuantaMax" BU_ BAP_Tester 80;
BA_ "TimeQuantaCANFDMin" BU_ BAP_Tester 20;
BA_ "TimeQuantaCANFDMax" BU_ BAP_Tester 20;
BA_ "GenNodSleepTime" BU_ Gateway_Max 4000;
BA_ "ECUVariantGroup" BU_ Gateway_Max "Gateway";
BA_ "NodeLayerModules" BU_ Gateway_Max "NMHigh.DLL";
BA_ "SamplePointMin" BU_ Gateway_Max 80;
BA_ "SamplePointMax" BU_ Gateway_Max 80;
BA_ "SyncJumpWidthMin" BU_ Gateway_Max 16;
BA_ "SyncJumpWidthMax" BU_ Gateway_Max 16;
BA_ "SyncJumpWidthCANFDMin" BU_ Gateway_Max 6;
BA_ "SyncJumpWidthCANFDMax" BU_ Gateway_Max 6;
BA_ "SamplePointCANFDMin" BU_ Gateway_Max 70;
BA_ "SamplePointCANFDMax" BU_ Gateway_Max 70;
BA_ "SSPOffsetCANFDMin" BU_ Gateway_Max 70;
BA_ "SSPOffsetCANFDMax" BU_ Gateway_Max 70;
BA_ "TimeQuantaMin" BU_ Gateway_Max 80;
BA_ "TimeQuantaMax" BU_ Gateway_Max 80;
BA_ "TimeQuantaCANFDMin" BU_ Gateway_Max 20;
BA_ "TimeQuantaCANFDMax" BU_ Gateway_Max 20;
BA_ "GenNodSleepTime" BU_ Getriebe_DQ 4000;
BA_ "ECUVariantGroup" BU_ Getriebe_DQ "Getriebe";
BA_ "NodeLayerModules" BU_ Getriebe_DQ "NMHigh.DLL";
BA_ "SamplePointMin" BU_ Getriebe_DQ 80;
BA_ "SamplePointMax" BU_ Getriebe_DQ 80;
BA_ "SyncJumpWidthMin" BU_ Getriebe_DQ 16;
BA_ "SyncJumpWidthMax" BU_ Getriebe_DQ 16;
BA_ "SyncJumpWidthCANFDMin" BU_ Getriebe_DQ 6;
BA_ "SyncJumpWidthCANFDMax" BU_ Getriebe_DQ 6;
BA_ "SamplePointCANFDMin" BU_ Getriebe_DQ 70;
BA_ "SamplePointCANFDMax" BU_ Getriebe_DQ 70;
BA_ "SSPOffsetCANFDMin" BU_ Getriebe_DQ 70;
BA_ "SSPOffsetCANFDMax" BU_ Getriebe_DQ 70;
BA_ "TimeQuantaMin" BU_ Getriebe_DQ 80;
BA_ "TimeQuantaMax" BU_ Getriebe_DQ 80;
BA_ "TimeQuantaCANFDMin" BU_ Getriebe_DQ 20;
BA_ "TimeQuantaCANFDMax" BU_ Getriebe_DQ 20;
BA_ "GenNodSleepTime" BU_ Motor_konv 4000;
BA_ "ECUVariantGroup" BU_ Motor_konv "Motor";
BA_ "NodeLayerModules" BU_ Motor_konv "NMHigh.DLL";
BA_ "SamplePointMin" BU_ Motor_konv 80;
BA_ "SamplePointMax" BU_ Motor_konv 80;
BA_ "SyncJumpWidthMin" BU_ Motor_konv 16;
BA_ "SyncJumpWidthMax" BU_ Motor_konv 16;
BA_ "SyncJumpWidthCANFDMin" BU_ Motor_konv 6;
BA_ "SyncJumpWidthCANFDMax" BU_ Motor_konv 6;
BA_ "SamplePointCANFDMin" BU_ Motor_konv 70;
BA_ "SamplePointCANFDMax" BU_ Motor_konv 70;
BA_ "SSPOffsetCANFDMin" BU_ Motor_konv 70;
BA_ "SSPOffsetCANFDMax" BU_ Motor_konv 70;
BA_ "TimeQuantaMin" BU_ Motor_konv 80;
BA_ "TimeQuantaMax" BU_ Motor_konv 80;
BA_ "TimeQuantaCANFDMin" BU_ Motor_konv 20;
BA_ "TimeQuantaCANFDMax" BU_ Motor_konv 20;
BA_ "GenNodSleepTime" BU_ Parksperre 4000;
BA_ "NodeLayerModules" BU_ Parksperre "NMHigh.DLL";
BA_ "SamplePointMin" BU_ Parksperre 80;
BA_ "SamplePointMax" BU_ Parksperre 80;
BA_ "SyncJumpWidthMin" BU_ Parksperre 16;
BA_ "SyncJumpWidthMax" BU_ Parksperre 16;
BA_ "SyncJumpWidthCANFDMin" BU_ Parksperre 6;
BA_ "SyncJumpWidthCANFDMax" BU_ Parksperre 6;
BA_ "SamplePointCANFDMin" BU_ Parksperre 70;
BA_ "SamplePointCANFDMax" BU_ Parksperre 70;
BA_ "SSPOffsetCANFDMin" BU_ Parksperre 70;
BA_ "SSPOffsetCANFDMax" BU_ Parksperre 70;
BA_ "TimeQuantaMin" BU_ Parksperre 80;
BA_ "TimeQuantaMax" BU_ Parksperre 80;
BA_ "TimeQuantaCANFDMin" BU_ Parksperre 20;
BA_ "TimeQuantaCANFDMax" BU_ Parksperre 20;
BA_ "GenNodSleepTime" BU_ Schaltbetaetigung 4000;
BA_ "ECUVariantGroup" BU_ Schaltbetaetigung "Waehlhebel";
BA_ "NodeLayerModules" BU_ Schaltbetaetigung "NMHigh.DLL";
BA_ "SamplePointMin" BU_ Schaltbetaetigung 80;
BA_ "SamplePointMax" BU_ Schaltbetaetigung 80;
BA_ "SyncJumpWidthMin" BU_ Schaltbetaetigung 16;
BA_ "SyncJumpWidthMax" BU_ Schaltbetaetigung 16;
BA_ "SyncJumpWidthCANFDMin" BU_ Schaltbetaetigung 6;
BA_ "SyncJumpWidthCANFDMax" BU_ Schaltbetaetigung 6;
BA_ "SamplePointCANFDMin" BU_ Schaltbetaetigung 70;
BA_ "SamplePointCANFDMax" BU_ Schaltbetaetigung 70;
BA_ "SSPOffsetCANFDMin" BU_ Schaltbetaetigung 70;
BA_ "SSPOffsetCANFDMax" BU_ Schaltbetaetigung 70;
BA_ "TimeQuantaMin" BU_ Schaltbetaetigung 80;
BA_ "TimeQuantaMax" BU_ Schaltbetaetigung 80;
BA_ "TimeQuantaCANFDMin" BU_ Schaltbetaetigung 20;
BA_ "TimeQuantaCANFDMax" BU_ Schaltbetaetigung 20;
BA_ "GenMsgCycleTime" BO_ 333 20;
BA_ "GenMsgILSupport" BO_ 333 1;
BA_ "GenMsgPDUConstants" BO_ 333 "0x1a,0x65,0x81,0x96,0xc0,0xdf,0x11,0x92,0xd3,0x61,0xc6,0x95,0x8c,0x29,0x21,0xb5";
BA_ "GenMsgSendType" BO_ 333 0;
BA_ "VFrameFormat" BO_ 333 14;
BA_ "GenMsgCycleTime" BO_ 859 80;
BA_ "GenMsgILSupport" BO_ 859 1;
BA_ "GenMsgSendType" BO_ 859 0;
BA_ "VFrameFormat" BO_ 859 14;
BA_ "GenMsgCycleTime" BO_ 860 80;
BA_ "GenMsgILSupport" BO_ 860 1;
BA_ "GenMsgSendType" BO_ 860 0;
BA_ "VFrameFormat" BO_ 860 14;
BA_ "GenMsgCycleTime" BO_ 1660 1000;
BA_ "GenMsgDelayTime" BO_ 1660 100;
BA_ "GenMsgILSupport" BO_ 1660 1;
BA_ "GenMsgSendType" BO_ 1660 0;
BA_ "VFrameFormat" BO_ 1660 14;
BA_ "GenMsgChkConstant" BO_ 64 64;
BA_ "GenMsgCycleTime" BO_ 64 40;
BA_ "GenMsgCycleTimeFast" BO_ 64 10;
BA_ "GenMsgDelayTime" BO_ 64 10;
BA_ "GenMsgILSupport" BO_ 64 1;
BA_ "GenMsgNrOfRepetition" BO_ 64 5;
BA_ "GenMsgPDUConstants" BO_ 64 "0x40,0x40,0x40,0x40,0x40,0x40,0x40,0x40,0x40,0x40,0x40,0x40,0x40,0x40,0x40,0x40";
BA_ "GenMsgSendType" BO_ 64 0;
BA_ "VFrameFormat" BO_ 64 14;
BA_ "GenMsgChkConstant" BO_ 1312 68;
BA_ "GenMsgCycleTime" BO_ 1312 200;
BA_ "GenMsgDelayTime" BO_ 1312 20;
BA_ "GenMsgILSupport" BO_ 1312 1;
BA_ "GenMsgPDUConstants" BO_ 1312 "0x44,0x44,0x44,0x44,0x44,0x44,0x44,0x44,0x44,0x44,0x44,0x44,0x44,0x44,0x44,0x44";
BA_ "GenMsgSendType" BO_ 1312 0;
BA_ "VFrameFormat" BO_ 1312 14;
BA_ "GenMsgCycleTime" BO_ 1349 200;
BA_ "GenMsgDelayTime" BO_ 1349 40;
BA_ "GenMsgILSupport" BO_ 1349 1;
BA_ "GenMsgPDUConstants" BO_ 1349 "0x95,0x19,0xd1,0x36,0x89,0xd4,0x02,0x1e,0xb9,0x80,0xd0,0x22,0x8a,0xf4,0x15,0xb8";
BA_ "GenMsgSendType" BO_ 1349 0;
BA_ "VFrameFormat" BO_ 1349 14;
BA_ "GenMsgCycleTime" BO_ 1633 100;
BA_ "GenMsgILSupport" BO_ 1633 1;
BA_ "GenMsgSendType" BO_ 1633 0;
BA_ "VFrameFormat" BO_ 1633 14;
BA_ "GenMsgCycleTime" BO_ 345 100;
BA_ "GenMsgDelayTime" BO_ 345 10;
BA_ "GenMsgILSupport" BO_ 345 1;
BA_ "GenMsgSendType" BO_ 345 0;
BA_ "VFrameFormat" BO_ 345 14;
BA_ "MsgType" BO_ 2536767264 5;
BA_ "VFrameFormat" BO_ 2536767264 15;
BA_ "MsgType" BO_ 2536767280 5;
BA_ "VFrameFormat" BO_ 2536767280 15;
BA_ "GenMsgCycleTimeFast" BO_ 2536734208 80;
BA_ "GenMsgSendType" BO_ 2536734208 7;
BA_ "MsgType" BO_ 2536734208 5;
BA_ "VFrameFormat" BO_ 2536734208 15;
BA_ "GenMsgCycleTime" BO_ 2536734224 1000;
BA_ "GenMsgCycleTimeFast" BO_ 2536734224 50;
BA_ "GenMsgSendType" BO_ 2536734224 7;
BA_ "MsgType" BO_ 2536734224 5;
BA_ "VFrameFormat" BO_ 2536734224 15;
BA_ "GenMsgCycleTimeFast" BO_ 2536717312 80;
BA_ "GenMsgSendType" BO_ 2536717312 7;
BA_ "MsgType" BO_ 2536717312 5;
BA_ "VFrameFormat" BO_ 2536717312 15;
BA_ "GenMsgCycleTimeFast" BO_ 2536717313 80;
BA_ "GenMsgSendType" BO_ 2536717313 7;
BA_ "MsgType" BO_ 2536717313 5;
BA_ "VFrameFormat" BO_ 2536717313 15;
BA_ "GenMsgCycleTime" BO_ 2536717328 1000;
BA_ "GenMsgCycleTimeFast" BO_ 2536717328 50;
BA_ "GenMsgSendType" BO_ 2536717328 7;
BA_ "MsgType" BO_ 2536717328 5;
BA_ "VFrameFormat" BO_ 2536717328 15;
BA_ "GenMsgCycleTimeFast" BO_ 2536725760 80;
BA_ "GenMsgSendType" BO_ 2536725760 7;
BA_ "MsgType" BO_ 2536725760 5;
BA_ "VFrameFormat" BO_ 2536725760 15;
BA_ "GenMsgCycleTime" BO_ 2536725776 1000;
BA_ "GenMsgCycleTimeFast" BO_ 2536725776 50;
BA_ "GenMsgSendType" BO_ 2536725776 7;
BA_ "MsgType" BO_ 2536725776 5;
BA_ "VFrameFormat" BO_ 2536725776 15;
BA_ "GenMsgCycleTimeFast" BO_ 2536709120 80;
BA_ "GenMsgSendType" BO_ 2536709120 7;
BA_ "MsgType" BO_ 2536709120 5;
BA_ "VFrameFormat" BO_ 2536709120 15;
BA_ "GenMsgCycleTimeFast" BO_ 2536709121 80;
BA_ "GenMsgSendType" BO_ 2536709121 7;
BA_ "MsgType" BO_ 2536709121 5;
BA_ "VFrameFormat" BO_ 2536709121 15;
BA_ "GenMsgCycleTime" BO_ 2536709136 1000;
BA_ "GenMsgCycleTimeFast" BO_ 2536709136 50;
BA_ "GenMsgSendType" BO_ 2536709136 7;
BA_ "MsgType" BO_ 2536709136 5;
BA_ "VFrameFormat" BO_ 2536709136 15;
BA_ "GenMsgCycleTimeFast" BO_ 2536716545 80;
BA_ "GenMsgSendType" BO_ 2536716545 7;
BA_ "MsgType" BO_ 2536716545 5;
BA_ "VFrameFormat" BO_ 2536716545 15;
BA_ "GenMsgCycleTime" BO_ 2536716560 1000;
BA_ "GenMsgCycleTimeFast" BO_ 2536716560 50;
BA_ "GenMsgSendType" BO_ 2536716560 7;
BA_ "MsgType" BO_ 2536716560 5;
BA_ "VFrameFormat" BO_ 2536716560 15;
BA_ "GenMsgCycleTime" BO_ 1626 1000;
BA_ "GenMsgCycleTimeFast" BO_ 1626 100;
BA_ "GenMsgDelayTime" BO_ 1626 30;
BA_ "GenMsgILSupport" BO_ 1626 1;
BA_ "GenMsgNrOfRepetition" BO_ 1626 5;
BA_ "GenMsgSendType" BO_ 1626 0;
BA_ "VFrameFormat" BO_ 1626 14;
BA_ "GenMsgCycleTime" BO_ 869 50;
BA_ "GenMsgILSupport" BO_ 869 1;
BA_ "GenMsgSendType" BO_ 869 0;
BA_ "VFrameFormat" BO_ 869 14;
BA_ "GenMsgCycleTime" BO_ 1163 100;
BA_ "GenMsgILSupport" BO_ 1163 1;
BA_ "GenMsgPDUConstants" BO_ 1163 "0x54,0xaf,0x8a,0xfb,0x0d,0x87,0x6a,0x0f,0x47,0x78,0x31,0x4f,0x35,0x28,0x82,0x6d";
BA_ "GenMsgSendType" BO_ 1163 0;
BA_ "VFrameFormat" BO_ 1163 14;
BA_ "GenMsgCycleTime" BO_ 2463978850 100;
BA_ "GenMsgILSupport" BO_ 2463978850 1;
BA_ "GenMsgPDUConstants" BO_ 2463978850 "0xaa,0xa9,0xe6,0xc5,0xc4,0x2b,0x0b,0x8e,0xfb,0x15,0xa4,0x64,0x1e,0x20,0x50,0x95";
BA_ "GenMsgSendType" BO_ 2463978850 0;
BA_ "VFrameFormat" BO_ 2463978850 15;
BA_ "GenMsgCycleTime" BO_ 1442 500;
BA_ "GenMsgCycleTimeFast" BO_ 1442 100;
BA_ "GenMsgDelayTime" BO_ 1442 20;
BA_ "GenMsgILSupport" BO_ 1442 1;
BA_ "GenMsgNrOfRepetition" BO_ 1442 5;
BA_ "GenMsgPDUConstants" BO_ 1442 "0xeb,0x4c,0x44,0xaf,0x21,0x8d,0x01,0x58,0xfa,0x93,0xdb,0x89,0x15,0x10,0x4a,0x61";
BA_ "GenMsgSendType" BO_ 1442 0;
BA_ "VFrameFormat" BO_ 1442 14;
BA_ "GenMsgCycleTime" BO_ 1450 500;
BA_ "GenMsgCycleTimeFast" BO_ 1450 100;
BA_ "GenMsgDelayTime" BO_ 1450 20;
BA_ "GenMsgSendType" BO_ 1450 0;
BA_ "VFrameFormat" BO_ 1450 14;
BA_ "GenMsgChkConstant" BO_ 1482 67;
BA_ "GenMsgCycleTime" BO_ 1482 500;
BA_ "GenMsgDelayTime" BO_ 1482 50;
BA_ "GenMsgILSupport" BO_ 1482 1;
BA_ "GenMsgPDUConstants" BO_ 1482 "0x43,0x43,0x43,0x43,0x43,0x43,0x43,0x43,0x43,0x43,0x43,0x43,0x43,0x43,0x43,0x43";
BA_ "GenMsgSendType" BO_ 1482 0;
BA_ "VFrameFormat" BO_ 1482 14;
BA_ "GenMsgCycleTime" BO_ 2527679654 200;
BA_ "GenMsgILSupport" BO_ 2527679654 1;
BA_ "GenMsgPDUConstants" BO_ 2527679654 "0x79,0xb9,0x67,0xad,0xd5,0xf7,0x70,0xaa,0x44,0x61,0x5a,0xdc,0x26,0xb4,0xd2,0xc3";
BA_ "GenMsgSendType" BO_ 2527679654 0;
BA_ "VFrameFormat" BO_ 2527679654 15;
BA_ "GenMsgCycleTime" BO_ 207 10;
BA_ "GenMsgILSupport" BO_ 207 1;
BA_ "GenMsgPDUConstants" BO_ 207 "0xee,0x80,0x6e,0x4e,0x29,0xc6,0x92,0xc0,0x65,0xaa,0x3a,0xa1,0x8f,0xcd,0xe6,0x90";
BA_ "GenMsgSendType" BO_ 207 0;
BA_ "VFrameFormat" BO_ 207 14;
BA_ "GenMsgCycleTime" BO_ 2463978704 100;
BA_ "GenMsgDelayTime" BO_ 2463978704 10;
BA_ "GenMsgILSupport" BO_ 2463978704 1;
BA_ "GenMsgSendType" BO_ 2463978704 0;
BA_ "VFrameFormat" BO_ 2463978704 15;
BA_ "GenSigSendType" SG_ 333 ACC_18_BZ 0;
BA_ "GenSigFuncType" SG_ 333 ACC_18_BZ 1;
BA_ "GenSigSwitchedByIgnition" SG_ 333 ACC_18_BZ 0;
BA_ "GenSigSendType" SG_ 333 ACC_18_CRC 0;
BA_ "GenSigFuncType" SG_ 333 ACC_18_CRC 2;
BA_ "GenSigSwitchedByIgnition" SG_ 333 ACC_18_CRC 0;
BA_ "GenSigSendType" SG_ 333 ACC_Abbiegewunsch 0;
BA_ "GenSigSwitchedByIgnition" SG_ 333 ACC_Abbiegewunsch 0;
BA_ "GenSigSendType" SG_ 333 ACC_Abbiegewunsch_Abstand 0;
BA_ "GenSigStartValue" SG_ 333 ACC_Abbiegewunsch_Abstand 511;
BA_ "GenSigSwitchedByIgnition" SG_ 333 ACC_Abbiegewunsch_Abstand 0;
BA_ "GenSigSendType" SG_ 333 ACC_Anfahren 0;
BA_ "GenSigSendType" SG_ 333 ACC_Anforderung_HMS 0;
BA_ "GenSigSendType" SG_ 333 ACC_Anhalten 0;
BA_ "GenSigSendType" SG_ 333 ACC_Anhalteweg 0;
BA_ "GenSigStartValue" SG_ 333 ACC_Anhalteweg 2046;
BA_ "Fehlerwert" SG_ 333 ACC_Anhalteweg 2047;
BA_ "GenSigSendType" SG_ 333 ACC_Blindheit_erkannt 0;
BA_ "GenSigSendType" SG_ 333 ACC_Boost 0;
BA_ "GenSigSendType" SG_ 333 ACC_DynErhoehung 0;
BA_ "GenSigSendType" SG_ 333 ACC_FoD_Status 0;
BA_ "GenSigSendType" SG_ 333 ACC_Folgebeschl 0;
BA_ "GenSigStartValue" SG_ 333 ACC_Folgebeschl 254;
BA_ "GenSigSendType" SG_ 333 ACC_Freilauf_Anf 0;
BA_ "GenSigSendType" SG_ 333 ACC_Freilauf_Info 0;
BA_ "GenSigSendType" SG_ 333 ACC_Freilaufstrategie_TSK 0;
BA_ "GenSigSendType" SG_ 333 ACC_limitierte_Anfahrdyn 0;
BA_ "GenSigSendType" SG_ 333 ACC_Minimale_Bremsung 0;
BA_ "GenSigSendType" SG_ 333 ACC_nachtr_Stopp_Anf 0;
BA_ "GenSigSwitchedByIgnition" SG_ 333 ACC_nachtr_Stopp_Anf 0;
BA_ "GenSigSendType" SG_ 333 ACC_neg_Sollbeschl_Grad_02 0;
BA_ "GenSigSendType" SG_ 333 ACC_pos_Sollbeschl_Grad_02 0;
BA_ "GenSigSendType" SG_ 333 ACC_relev_Nichtverfuegbarkeit 0;
BA_ "GenSigSendType" SG_ 333 ACC_relevanter_Fehler 0;
BA_ "GenSigSendType" SG_ 333 ACC_Sollbeschleunigung_02 0;
BA_ "GenSigStartValue" SG_ 333 ACC_Sollbeschleunigung_02 2046;
BA_ "Fehlerwert" SG_ 333 ACC_Sollbeschleunigung_02 2047;
BA_ "GenSigSendType" SG_ 333 ACC_StartStopp_Info 0;
BA_ "GenSigSendType" SG_ 333 ACC_Status_ACC 0;
BA_ "GenSigSendType" SG_ 333 ACC_TA_Kurve_Abstand 0;
BA_ "GenSigStartValue" SG_ 333 ACC_TA_Kurve_Abstand 62;
BA_ "GenSigSendType" SG_ 333 ACC_TA_Kurve_vDelta 0;
BA_ "GenSigStartValue" SG_ 333 ACC_TA_Kurve_vDelta 11;
BA_ "GenSigSendType" SG_ 333 ACC_Tempolimitassistent_Ein 0;
BA_ "GenSigSendType" SG_ 333 ACC_Typ 0;
BA_ "GenSigFuncType" SG_ 333 ACC_Typ 8;
BA_ "GenSigSendType" SG_ 333 ACC_Verkehrssinn 0;
BA_ "GenSigSendType" SG_ 333 ACC_zul_Regelabw_oben 0;
BA_ "GenSigSendType" SG_ 333 ACC_zul_Regelabw_unten 0;
BA_ "GenSigSendType" SG_ 333 MPPmod_1_Segment 0;
BA_ "GenSigSwitchedByIgnition" SG_ 333 MPPmod_1_Segment 0;
BA_ "GenSigSendType" SG_ 333 MPPmod_2_Segment 0;
BA_ "GenSigSwitchedByIgnition" SG_ 333 MPPmod_2_Segment 0;
BA_ "GenSigSendType" SG_ 333 MPPmod_3_Segment 0;
BA_ "GenSigSwitchedByIgnition" SG_ 333 MPPmod_3_Segment 0;
BA_ "GenSigSendType" SG_ 333 MPPmod_4_Segment 0;
BA_ "GenSigSwitchedByIgnition" SG_ 333 MPPmod_4_Segment 0;
BA_ "GenSigSendType" SG_ 333 RDR_v_ueber_Grund 0;
BA_ "GenSigStartValue" SG_ 333 RDR_v_ueber_Grund 4091;
BA_ "Fehlerwert" SG_ 333 RDR_v_ueber_Grund 4093;
BA_ "GenSigSendType" SG_ 333 RDR_v_ueber_Grund_Fahrtrichtung 0;
BA_ "GenSigStartValue" SG_ 333 RDR_v_ueber_Grund_Fahrtrichtung 2;
BA_ "GenSigSendType" SG_ 333 RDR_v_ueber_Grund_Genauigkeit 0;
BA_ "GenSigStartValue" SG_ 333 RDR_v_ueber_Grund_Genauigkeit 62;
BA_ "Fehlerwert" SG_ 333 RDR_v_ueber_Grund_Genauigkeit 63;
BA_ "GenSigSendType" SG_ 333 RDR_VBEG_Anforderung 0;
BA_ "GenSigSwitchedByIgnition" SG_ 333 RDR_VBEG_Anforderung 0;
BA_ "GenSigSendType" SG_ 333 vESC_Verz_Anf 0;
BA_ "GenSigStartValue" SG_ 333 vESC_Verz_Anf 9;
BA_ "Fehlerwert" SG_ 333 vESC_Verz_Anf 10;
BA_ "GenSigSendType" SG_ 859 ACC_Obj_01_Alter 0;
BA_ "GenSigStartValue" SG_ 859 ACC_Obj_01_Alter 4095;
BA_ "GenSigSendType" SG_ 859 ACC_Obj_01_Anzeige_Rel 0;
BA_ "GenSigSendType" SG_ 859 ACC_Obj_01_ax_StdA 0;
BA_ "GenSigStartValue" SG_ 859 ACC_Obj_01_ax_StdA 63;
BA_ "GenSigSendType" SG_ 859 ACC_Obj_01_ax_v 0;
BA_ "GenSigStartValue" SG_ 859 ACC_Obj_01_ax_v 255;
BA_ "GenSigSendType" SG_ 859 ACC_Obj_01_axAbs_StdA 0;
BA_ "GenSigStartValue" SG_ 859 ACC_Obj_01_axAbs_StdA 63;
BA_ "GenSigSendType" SG_ 859 ACC_Obj_01_axAbs_v 0;
BA_ "GenSigStartValue" SG_ 859 ACC_Obj_01_axAbs_v 255;
BA_ "GenSigSendType" SG_ 859 ACC_Obj_01_ay_StdA 0;
BA_ "GenSigStartValue" SG_ 859 ACC_Obj_01_ay_StdA 63;
BA_ "GenSigSendType" SG_ 859 ACC_Obj_01_ay_v 0;
BA_ "GenSigStartValue" SG_ 859 ACC_Obj_01_ay_v 255;
BA_ "GenSigSendType" SG_ 859 ACC_Obj_01_Bew_Zustand 0;
BA_ "GenSigSendType" SG_ 859 ACC_Obj_01_Bezugspunkt 0;
BA_ "GenSigStartValue" SG_ 859 ACC_Obj_01_Bezugspunkt 15;
BA_ "GenSigSendType" SG_ 859 ACC_Obj_01_Breite 0;
BA_ "GenSigStartValue" SG_ 859 ACC_Obj_01_Breite 127;
BA_ "GenSigSendType" SG_ 859 ACC_Obj_01_BreiteStdA 0;
BA_ "GenSigStartValue" SG_ 859 ACC_Obj_01_BreiteStdA 127;
BA_ "GenSigSendType" SG_ 859 ACC_Obj_01_dx_StdA 0;
BA_ "GenSigSendType" SG_ 859 ACC_Obj_01_dx_v 0;
BA_ "GenSigStartValue" SG_ 859 ACC_Obj_01_dx_v 4095;
BA_ "GenSigSendType" SG_ 859 ACC_Obj_01_dy_StdA 0;
BA_ "GenSigStartValue" SG_ 859 ACC_Obj_01_dy_StdA 127;
BA_ "GenSigSendType" SG_ 859 ACC_Obj_01_dy_v 0;
BA_ "GenSigStartValue" SG_ 859 ACC_Obj_01_dy_v 2047;
BA_ "GenSigSendType" SG_ 859 ACC_Obj_01_dz_StdA 0;
BA_ "GenSigStartValue" SG_ 859 ACC_Obj_01_dz_StdA 127;
BA_ "GenSigSendType" SG_ 859 ACC_Obj_01_dz_v 0;
BA_ "GenSigStartValue" SG_ 859 ACC_Obj_01_dz_v 511;
BA_ "GenSigSendType" SG_ 859 ACC_Obj_01_ExistenzMass 0;
BA_ "GenSigStartValue" SG_ 859 ACC_Obj_01_ExistenzMass 127;
BA_ "GenSigSendType" SG_ 859 ACC_Obj_01_Fusion_ID_FER_VL 0;
BA_ "GenSigStartValue" SG_ 859 ACC_Obj_01_Fusion_ID_FER_VL 255;
BA_ "GenSigSendType" SG_ 859 ACC_Obj_01_Fusion_ID_FER_VR 0;
BA_ "GenSigStartValue" SG_ 859 ACC_Obj_01_Fusion_ID_FER_VR 255;
BA_ "GenSigSendType" SG_ 859 ACC_Obj_01_Fusion_ID_VD 0;
BA_ "GenSigSendType" SG_ 859 ACC_Obj_01_Gemessen 0;
BA_ "GenSigSendType" SG_ 859 ACC_Obj_01_GierWnkl 0;
BA_ "GenSigStartValue" SG_ 859 ACC_Obj_01_GierWnkl 511;
BA_ "GenSigSendType" SG_ 859 ACC_Obj_01_GierWnklStdA 0;
BA_ "GenSigStartValue" SG_ 859 ACC_Obj_01_GierWnklStdA 63;
BA_ "GenSigSendType" SG_ 859 ACC_Obj_01_Historie 0;
BA_ "GenSigSendType" SG_ 859 ACC_Obj_01_Hoehe 0;
BA_ "GenSigStartValue" SG_ 859 ACC_Obj_01_Hoehe 63;
BA_ "GenSigSendType" SG_ 859 ACC_Obj_01_HoeheStdA 0;
BA_ "GenSigStartValue" SG_ 859 ACC_Obj_01_HoeheStdA 63;
BA_ "GenSigSendType" SG_ 859 ACC_Obj_01_ID 0;
BA_ "GenSigStartValue" SG_ 859 ACC_Obj_01_ID 255;
BA_ "GenSigSendType" SG_ 859 ACC_Obj_01_Klasse 0;
BA_ "GenSigStartValue" SG_ 859 ACC_Obj_01_Klasse 15;
BA_ "GenSigSendType" SG_ 859 ACC_Obj_01_KlassePlausib 0;
BA_ "GenSigStartValue" SG_ 859 ACC_Obj_01_KlassePlausib 15;
BA_ "GenSigSendType" SG_ 859 ACC_Obj_01_Laenge 0;
BA_ "GenSigStartValue" SG_ 859 ACC_Obj_01_Laenge 511;
BA_ "GenSigSendType" SG_ 859 ACC_Obj_01_LaengeStdA 0;
BA_ "GenSigStartValue" SG_ 859 ACC_Obj_01_LaengeStdA 127;
BA_ "GenSigSendType" SG_ 859 ACC_Obj_01_LaengsRegelung 0;
BA_ "GenSigSendType" SG_ 859 ACC_Obj_01_SDFInfo_FER_VL 0;
BA_ "GenSigSendType" SG_ 859 ACC_Obj_01_SDFInfo_FER_VR 0;
BA_ "GenSigSendType" SG_ 859 ACC_Obj_01_SDFInfo_FR 0;
BA_ "GenSigSendType" SG_ 859 ACC_Obj_01_SDFInfo_Kamera 0;
BA_ "GenSigSendType" SG_ 859 ACC_Obj_01_vx_StdA 0;
BA_ "GenSigStartValue" SG_ 859 ACC_Obj_01_vx_StdA 31;
BA_ "GenSigSendType" SG_ 859 ACC_Obj_01_vx_v 0;
BA_ "GenSigStartValue" SG_ 859 ACC_Obj_01_vx_v 1023;
BA_ "GenSigSendType" SG_ 859 ACC_Obj_01_vxAbs_StdA 0;
BA_ "GenSigStartValue" SG_ 859 ACC_Obj_01_vxAbs_StdA 63;
BA_ "GenSigSendType" SG_ 859 ACC_Obj_01_vxAbs_v 0;
BA_ "GenSigStartValue" SG_ 859 ACC_Obj_01_vxAbs_v 4095;
BA_ "GenSigSendType" SG_ 859 ACC_Obj_01_vy_StdA 0;
BA_ "GenSigStartValue" SG_ 859 ACC_Obj_01_vy_StdA 31;
BA_ "GenSigSendType" SG_ 859 ACC_Obj_01_vy_v 0;
BA_ "GenSigStartValue" SG_ 859 ACC_Obj_01_vy_v 255;
BA_ "GenSigSendType" SG_ 859 ACC_Obj_01_vyAbs_StdA 0;
BA_ "GenSigStartValue" SG_ 859 ACC_Obj_01_vyAbs_StdA 63;
BA_ "GenSigSendType" SG_ 859 ACC_Obj_01_vyAbs_v 0;
BA_ "GenSigStartValue" SG_ 859 ACC_Obj_01_vyAbs_v 4095;
BA_ "GenSigSendType" SG_ 860 ACC_Obj_04_Alter 0;
BA_ "GenSigStartValue" SG_ 860 ACC_Obj_04_Alter 4095;
BA_ "GenSigSwitchedByIgnition" SG_ 860 ACC_Obj_04_Alter 0;
BA_ "GenSigSendType" SG_ 860 ACC_Obj_04_Anzeige_Rel 0;
BA_ "GenSigSwitchedByIgnition" SG_ 860 ACC_Obj_04_Anzeige_Rel 0;
BA_ "GenSigSendType" SG_ 860 ACC_Obj_04_ax_StdA 0;
BA_ "GenSigStartValue" SG_ 860 ACC_Obj_04_ax_StdA 63;
BA_ "GenSigSwitchedByIgnition" SG_ 860 ACC_Obj_04_ax_StdA 0;
BA_ "GenSigSendType" SG_ 860 ACC_Obj_04_ax_v 0;
BA_ "GenSigStartValue" SG_ 860 ACC_Obj_04_ax_v 255;
BA_ "GenSigSwitchedByIgnition" SG_ 860 ACC_Obj_04_ax_v 0;
BA_ "GenSigSendType" SG_ 860 ACC_Obj_04_axAbs_StdA 0;
BA_ "GenSigStartValue" SG_ 860 ACC_Obj_04_axAbs_StdA 63;
BA_ "GenSigSwitchedByIgnition" SG_ 860 ACC_Obj_04_axAbs_StdA 0;
BA_ "GenSigSendType" SG_ 860 ACC_Obj_04_axAbs_v 0;
BA_ "GenSigStartValue" SG_ 860 ACC_Obj_04_axAbs_v 255;
BA_ "GenSigSwitchedByIgnition" SG_ 860 ACC_Obj_04_axAbs_v 0;
BA_ "GenSigSendType" SG_ 860 ACC_Obj_04_ay_StdA 0;
BA_ "GenSigStartValue" SG_ 860 ACC_Obj_04_ay_StdA 63;
BA_ "GenSigSwitchedByIgnition" SG_ 860 ACC_Obj_04_ay_StdA 0;
BA_ "GenSigSendType" SG_ 860 ACC_Obj_04_ay_v 0;
BA_ "GenSigStartValue" SG_ 860 ACC_Obj_04_ay_v 255;
BA_ "GenSigSwitchedByIgnition" SG_ 860 ACC_Obj_04_ay_v 0;
BA_ "GenSigSendType" SG_ 860 ACC_Obj_04_Bew_Zustand 0;
BA_ "GenSigSwitchedByIgnition" SG_ 860 ACC_Obj_04_Bew_Zustand 0;
BA_ "GenSigSendType" SG_ 860 ACC_Obj_04_Bezugspunkt 0;
BA_ "GenSigStartValue" SG_ 860 ACC_Obj_04_Bezugspunkt 15;
BA_ "GenSigSwitchedByIgnition" SG_ 860 ACC_Obj_04_Bezugspunkt 0;
BA_ "GenSigSendType" SG_ 860 ACC_Obj_04_Breite 0;
BA_ "GenSigStartValue" SG_ 860 ACC_Obj_04_Breite 127;
BA_ "GenSigSwitchedByIgnition" SG_ 860 ACC_Obj_04_Breite 0;
BA_ "GenSigSendType" SG_ 860 ACC_Obj_04_BreiteStdA 0;
BA_ "GenSigStartValue" SG_ 860 ACC_Obj_04_BreiteStdA 127;
BA_ "GenSigSwitchedByIgnition" SG_ 860 ACC_Obj_04_BreiteStdA 0;
BA_ "GenSigSendType" SG_ 860 ACC_Obj_04_dx_StdA 0;
BA_ "GenSigStartValue" SG_ 860 ACC_Obj_04_dx_StdA 127;
BA_ "GenSigSwitchedByIgnition" SG_ 860 ACC_Obj_04_dx_StdA 0;
BA_ "GenSigSendType" SG_ 860 ACC_Obj_04_dx_v 0;
BA_ "GenSigStartValue" SG_ 860 ACC_Obj_04_dx_v 4095;
BA_ "GenSigSendType" SG_ 860 ACC_Obj_04_dy_StdA 0;
BA_ "GenSigStartValue" SG_ 860 ACC_Obj_04_dy_StdA 127;
BA_ "GenSigSwitchedByIgnition" SG_ 860 ACC_Obj_04_dy_StdA 0;
BA_ "GenSigSendType" SG_ 860 ACC_Obj_04_dy_v 0;
BA_ "GenSigStartValue" SG_ 860 ACC_Obj_04_dy_v 2047;
BA_ "GenSigSendType" SG_ 860 ACC_Obj_04_dz_StdA 0;
BA_ "GenSigStartValue" SG_ 860 ACC_Obj_04_dz_StdA 127;
BA_ "GenSigSwitchedByIgnition" SG_ 860 ACC_Obj_04_dz_StdA 0;
BA_ "GenSigSendType" SG_ 860 ACC_Obj_04_dz_v 0;
BA_ "GenSigStartValue" SG_ 860 ACC_Obj_04_dz_v 511;
BA_ "GenSigSwitchedByIgnition" SG_ 860 ACC_Obj_04_dz_v 0;
BA_ "GenSigSendType" SG_ 860 ACC_Obj_04_ExistenzMass 0;
BA_ "GenSigStartValue" SG_ 860 ACC_Obj_04_ExistenzMass 127;
BA_ "GenSigSwitchedByIgnition" SG_ 860 ACC_Obj_04_ExistenzMass 0;
BA_ "GenSigSendType" SG_ 860 ACC_Obj_04_Fusion_ID_FER_VL 0;
BA_ "GenSigStartValue" SG_ 860 ACC_Obj_04_Fusion_ID_FER_VL 255;
BA_ "GenSigSwitchedByIgnition" SG_ 860 ACC_Obj_04_Fusion_ID_FER_VL 0;
BA_ "GenSigSendType" SG_ 860 ACC_Obj_04_Fusion_ID_FER_VR 0;
BA_ "GenSigStartValue" SG_ 860 ACC_Obj_04_Fusion_ID_FER_VR 255;
BA_ "GenSigSwitchedByIgnition" SG_ 860 ACC_Obj_04_Fusion_ID_FER_VR 0;
BA_ "GenSigSendType" SG_ 860 ACC_Obj_04_Fusion_ID_VD 0;
BA_ "GenSigSwitchedByIgnition" SG_ 860 ACC_Obj_04_Fusion_ID_VD 0;
BA_ "GenSigSendType" SG_ 860 ACC_Obj_04_Gemessen 0;
BA_ "GenSigSwitchedByIgnition" SG_ 860 ACC_Obj_04_Gemessen 0;
BA_ "GenSigSendType" SG_ 860 ACC_Obj_04_GierWnkl 0;
BA_ "GenSigStartValue" SG_ 860 ACC_Obj_04_GierWnkl 511;
BA_ "GenSigSwitchedByIgnition" SG_ 860 ACC_Obj_04_GierWnkl 0;
BA_ "GenSigSendType" SG_ 860 ACC_Obj_04_GierWnklStdA 0;
BA_ "GenSigStartValue" SG_ 860 ACC_Obj_04_GierWnklStdA 63;
BA_ "GenSigSwitchedByIgnition" SG_ 860 ACC_Obj_04_GierWnklStdA 0;
BA_ "GenSigSendType" SG_ 860 ACC_Obj_04_Historie 0;
BA_ "GenSigSwitchedByIgnition" SG_ 860 ACC_Obj_04_Historie 0;
BA_ "GenSigSendType" SG_ 860 ACC_Obj_04_Hoehe 0;
BA_ "GenSigStartValue" SG_ 860 ACC_Obj_04_Hoehe 63;
BA_ "GenSigSwitchedByIgnition" SG_ 860 ACC_Obj_04_Hoehe 0;
BA_ "GenSigSendType" SG_ 860 ACC_Obj_04_HoeheStdA 0;
BA_ "GenSigStartValue" SG_ 860 ACC_Obj_04_HoeheStdA 63;
BA_ "GenSigSwitchedByIgnition" SG_ 860 ACC_Obj_04_HoeheStdA 0;
BA_ "GenSigSendType" SG_ 860 ACC_Obj_04_ID 0;
BA_ "GenSigStartValue" SG_ 860 ACC_Obj_04_ID 255;
BA_ "GenSigSendType" SG_ 860 ACC_Obj_04_Klasse 0;
BA_ "GenSigStartValue" SG_ 860 ACC_Obj_04_Klasse 15;
BA_ "GenSigSwitchedByIgnition" SG_ 860 ACC_Obj_04_Klasse 0;
BA_ "GenSigSendType" SG_ 860 ACC_Obj_04_KlassePlausib 0;
BA_ "GenSigStartValue" SG_ 860 ACC_Obj_04_KlassePlausib 15;
BA_ "GenSigSwitchedByIgnition" SG_ 860 ACC_Obj_04_KlassePlausib 0;
BA_ "GenSigSendType" SG_ 860 ACC_Obj_04_Laenge 0;
BA_ "GenSigStartValue" SG_ 860 ACC_Obj_04_Laenge 511;
BA_ "GenSigSwitchedByIgnition" SG_ 860 ACC_Obj_04_Laenge 0;
BA_ "GenSigSendType" SG_ 860 ACC_Obj_04_LaengeStdA 0;
BA_ "GenSigStartValue" SG_ 860 ACC_Obj_04_LaengeStdA 127;
BA_ "GenSigSwitchedByIgnition" SG_ 860 ACC_Obj_04_LaengeStdA 0;
BA_ "GenSigSendType" SG_ 860 ACC_Obj_04_LaengsRegelung 0;
BA_ "GenSigSwitchedByIgnition" SG_ 860 ACC_Obj_04_LaengsRegelung 0;
BA_ "GenSigSendType" SG_ 860 ACC_Obj_04_SDFInfo_FER_VL 0;
BA_ "GenSigSwitchedByIgnition" SG_ 860 ACC_Obj_04_SDFInfo_FER_VL 0;
BA_ "GenSigSendType" SG_ 860 ACC_Obj_04_SDFInfo_FER_VR 0;
BA_ "GenSigSwitchedByIgnition" SG_ 860 ACC_Obj_04_SDFInfo_FER_VR 0;
BA_ "GenSigSendType" SG_ 860 ACC_Obj_04_SDFInfo_FR 0;
BA_ "GenSigSwitchedByIgnition" SG_ 860 ACC_Obj_04_SDFInfo_FR 0;
BA_ "GenSigSendType" SG_ 860 ACC_Obj_04_SDFInfo_Kamera 0;
BA_ "GenSigSwitchedByIgnition" SG_ 860 ACC_Obj_04_SDFInfo_Kamera 0;
BA_ "GenSigSendType" SG_ 860 ACC_Obj_04_vx_StdA 0;
BA_ "GenSigStartValue" SG_ 860 ACC_Obj_04_vx_StdA 31;
BA_ "GenSigSwitchedByIgnition" SG_ 860 ACC_Obj_04_vx_StdA 0;
BA_ "GenSigSendType" SG_ 860 ACC_Obj_04_vx_v 0;
BA_ "GenSigStartValue" SG_ 860 ACC_Obj_04_vx_v 1023;
BA_ "GenSigSendType" SG_ 860 ACC_Obj_04_vxAbs_StdA 0;
BA_ "GenSigStartValue" SG_ 860 ACC_Obj_04_vxAbs_StdA 63;
BA_ "GenSigSwitchedByIgnition" SG_ 860 ACC_Obj_04_vxAbs_StdA 0;
BA_ "GenSigSendType" SG_ 860 ACC_Obj_04_vxAbs_v 0;
BA_ "GenSigStartValue" SG_ 860 ACC_Obj_04_vxAbs_v 4095;
BA_ "GenSigSwitchedByIgnition" SG_ 860 ACC_Obj_04_vxAbs_v 0;
BA_ "GenSigSendType" SG_ 860 ACC_Obj_04_vy_StdA 0;
BA_ "GenSigStartValue" SG_ 860 ACC_Obj_04_vy_StdA 31;
BA_ "GenSigSwitchedByIgnition" SG_ 860 ACC_Obj_04_vy_StdA 0;
BA_ "GenSigSendType" SG_ 860 ACC_Obj_04_vy_v 0;
BA_ "GenSigStartValue" SG_ 860 ACC_Obj_04_vy_v 255;
BA_ "GenSigSendType" SG_ 860 ACC_Obj_04_vyAbs_StdA 0;
BA_ "GenSigStartValue" SG_ 860 ACC_Obj_04_vyAbs_StdA 63;
BA_ "GenSigSwitchedByIgnition" SG_ 860 ACC_Obj_04_vyAbs_StdA 0;
BA_ "GenSigSendType" SG_ 860 ACC_Obj_04_vyAbs_v 0;
BA_ "GenSigStartValue" SG_ 860 ACC_Obj_04_vyAbs_v 4095;
BA_ "GenSigSwitchedByIgnition" SG_ 860 ACC_Obj_04_vyAbs_v 0;
BA_ "GenSigSendType" SG_ 1660 AGA_Charisma_FahrPr 3;
BA_ "GenSigSendType" SG_ 1660 AGA_Charisma_Status 3;
BA_ "GenSigSendType" SG_ 1660 AGA_ohne_Funktion 3;
BA_ "Fehlerwert" SG_ 1660 AGA_ohne_Funktion 1;
BA_ "GenSigSendType" SG_ 1660 AGA_Texte 3;
BA_ "GenSigSendType" SG_ 1660 AGA_Verstaerker_Mute 0;
BA_ "GenSigSwitchedByIgnition" SG_ 1660 AGA_Verstaerker_Mute 0;
BA_ "GenSigSendType" SG_ 1660 E_Sound_verbaut 0;
BA_ "GenSigSendType" SG_ 64 AB_Anzeige_Fussg 0;
BA_ "GenSigSwitchedByIgnition" SG_ 64 AB_Anzeige_Fussg 0;
BA_ "GenSigSendType" SG_ 64 AB_Belegung_VF 0;
BA_ "GenSigSwitchedByIgnition" SG_ 64 AB_Belegung_VF 0;
BA_ "Fehlerwert" SG_ 64 AB_Belegung_VF 1;
BA_ "GenSigSendType" SG_ 64 AB_Crash_Int 4;
BA_ "GenSigSwitchedByIgnition" SG_ 64 AB_Crash_Int 0;
BA_ "GenSigSendType" SG_ 64 AB_Deaktiviert 0;
BA_ "GenSigSwitchedByIgnition" SG_ 64 AB_Deaktiviert 0;
BA_ "GenSigSendType" SG_ 64 AB_Deaktivierung_HV 4;
BA_ "GenSigSwitchedByIgnition" SG_ 64 AB_Deaktivierung_HV 0;
BA_ "Fehlerwert" SG_ 64 AB_Deaktivierung_HV 7;
BA_ "GenSigSendType" SG_ 64 AB_Diagnose 0;
BA_ "GenSigSwitchedByIgnition" SG_ 64 AB_Diagnose 0;
BA_ "GenSigSendType" SG_ 64 AB_eCS_Error 0;
BA_ "GenSigSwitchedByIgnition" SG_ 64 AB_eCS_Error 0;
BA_ "GenSigSendType" SG_ 64 AB_EDR_Trigger 3;
BA_ "GenSigSwitchedByIgnition" SG_ 64 AB_EDR_Trigger 0;
BA_ "GenSigSendType" SG_ 64 AB_Erh_Auf_VB 0;
BA_ "GenSigSwitchedByIgnition" SG_ 64 AB_Erh_Auf_VB 0;
BA_ "GenSigSendType" SG_ 64 AB_Front_Crash 4;
BA_ "GenSigSwitchedByIgnition" SG_ 64 AB_Front_Crash 0;
BA_ "GenSigSendType" SG_ 64 AB_Gurtschloss_FA_ext 3;
BA_ "GenSigStartValue" SG_ 64 AB_Gurtschloss_FA_ext 6;
BA_ "GenSigSwitchedByIgnition" SG_ 64 AB_Gurtschloss_FA_ext 0;
BA_ "Fehlerwert" SG_ 64 AB_Gurtschloss_FA_ext 7;
BA_ "GenSigSendType" SG_ 64 AB_Gurtschloss_FA_ext_aktiv 0;
BA_ "GenSigSwitchedByIgnition" SG_ 64 AB_Gurtschloss_FA_ext_aktiv 0;
BA_ "GenSigSendType" SG_ 64 AB_Gurtwarn_VB 0;
BA_ "GenSigSwitchedByIgnition" SG_ 64 AB_Gurtwarn_VB 0;
BA_ "GenSigSendType" SG_ 64 AB_Gurtwarn_VF 0;
BA_ "GenSigSwitchedByIgnition" SG_ 64 AB_Gurtwarn_VF 0;
BA_ "GenSigSendType" SG_ 64 AB_Heck_Crash 4;
BA_ "GenSigSwitchedByIgnition" SG_ 64 AB_Heck_Crash 0;
BA_ "GenSigSendType" SG_ 64 AB_Lampe 0;
BA_ "GenSigStartValue" SG_ 64 AB_Lampe 1;
BA_ "GenSigSwitchedByIgnition" SG_ 64 AB_Lampe 0;
BA_ "GenSigSendType" SG_ 64 AB_MKB_Anforderung 4;
BA_ "GenSigSwitchedByIgnition" SG_ 64 AB_MKB_Anforderung 0;
BA_ "GenSigSendType" SG_ 64 AB_MKB_gueltig 0;
BA_ "GenSigSwitchedByIgnition" SG_ 64 AB_MKB_gueltig 0;
BA_ "GenSigSendType" SG_ 64 AB_PAO_Leuchte_Anf 0;
BA_ "GenSigStartValue" SG_ 64 AB_PAO_Leuchte_Anf 1;
BA_ "GenSigSwitchedByIgnition" SG_ 64 AB_PAO_Leuchte_Anf 0;
BA_ "GenSigSendType" SG_ 64 AB_RGS_Anst 3;
BA_ "GenSigStartValue" SG_ 64 AB_RGS_Anst 8;
BA_ "GenSigSwitchedByIgnition" SG_ 64 AB_RGS_Anst 0;
BA_ "GenSigSendType" SG_ 64 AB_Rollover_Crash 4;
BA_ "GenSigSwitchedByIgnition" SG_ 64 AB_Rollover_Crash 0;
BA_ "GenSigSendType" SG_ 64 AB_SB_Crash 4;
BA_ "GenSigSwitchedByIgnition" SG_ 64 AB_SB_Crash 0;
BA_ "GenSigSendType" SG_ 64 AB_SF_Crash 4;
BA_ "GenSigSwitchedByIgnition" SG_ 64 AB_SF_Crash 0;
BA_ "GenSigSendType" SG_ 64 AB_Stellgliedtest 0;
BA_ "GenSigSwitchedByIgnition" SG_ 64 AB_Stellgliedtest 0;
BA_ "GenSigSendType" SG_ 64 AB_Systemfehler 0;
BA_ "GenSigSwitchedByIgnition" SG_ 64 AB_Systemfehler 0;
BA_ "GenSigSendType" SG_ 64 AB_Texte_AKS 0;
BA_ "GenSigSwitchedByIgnition" SG_ 64 AB_Texte_AKS 0;
BA_ "GenSigSendType" SG_ 64 AB_VB_deaktiviert 0;
BA_ "GenSigStartValue" SG_ 64 AB_VB_deaktiviert 1;
BA_ "GenSigSwitchedByIgnition" SG_ 64 AB_VB_deaktiviert 0;
BA_ "GenSigSendType" SG_ 64 AB_Versorgungsspannung 0;
BA_ "GenSigSwitchedByIgnition" SG_ 64 AB_Versorgungsspannung 0;
BA_ "GenSigSendType" SG_ 64 Airbag_01_BZ 0;
BA_ "GenSigFuncType" SG_ 64 Airbag_01_BZ 1;
BA_ "GenSigSwitchedByIgnition" SG_ 64 Airbag_01_BZ 0;
BA_ "GenSigSendType" SG_ 64 Airbag_01_CRC 0;
BA_ "GenSigFuncType" SG_ 64 Airbag_01_CRC 2;
BA_ "GenSigSwitchedByIgnition" SG_ 64 Airbag_01_CRC 0;
BA_ "GenSigSendType" SG_ 64 ASM_Masterzeit_02 0;
BA_ "GenSigStartValue" SG_ 64 ASM_Masterzeit_02 255;
BA_ "GenSigSwitchedByIgnition" SG_ 64 ASM_Masterzeit_02 0;
BA_ "GenSigSendType" SG_ 1312 AB_Abschaltanf_SIH_BF 3;
BA_ "GenSigSendType" SG_ 1312 AB_Anforderung_eCall 0;
BA_ "GenSigSwitchedByIgnition" SG_ 1312 AB_Anforderung_eCall 0;
BA_ "GenSigSendType" SG_ 1312 AB_Anforderung_USM 0;
BA_ "GenSigSwitchedByIgnition" SG_ 1312 AB_Anforderung_USM 0;
BA_ "GenSigSendType" SG_ 1312 AB_Anprall_FGS 3;
BA_ "GenSigSendType" SG_ 1312 AB_Anprall_Front_Beifahrer 3;
BA_ "GenSigSendType" SG_ 1312 AB_Anprall_Front_Fahrer 3;
BA_ "GenSigSendType" SG_ 1312 AB_Anprall_Heck_Beifahrer 3;
BA_ "GenSigSendType" SG_ 1312 AB_Anprall_Heck_Fahrer 3;
BA_ "GenSigSendType" SG_ 1312 AB_Anprall_Rollover 3;
BA_ "GenSigSendType" SG_ 1312 AB_Anprall_Seite_Beifahrer 3;
BA_ "GenSigSendType" SG_ 1312 AB_Anprall_Seite_Fahrer 3;
BA_ "GenSigSendType" SG_ 1312 AB_Belegung_VB 0;
BA_ "GenSigSwitchedByIgnition" SG_ 1312 AB_Belegung_VB 0;
BA_ "Fehlerwert" SG_ 1312 AB_Belegung_VB 1;
BA_ "GenSigSendType" SG_ 1312 AB_Crashschwere 3;
BA_ "GenSigSwitchedByIgnition" SG_ 1312 AB_Crashschwere 0;
BA_ "Fehlerwert" SG_ 1312 AB_Crashschwere 7;
BA_ "GenSigSendType" SG_ 1312 AB_Gurtschloss_BF 3;
BA_ "GenSigStartValue" SG_ 1312 AB_Gurtschloss_BF 1;
BA_ "GenSigSwitchedByIgnition" SG_ 1312 AB_Gurtschloss_BF 0;
BA_ "GenSigSendType" SG_ 1312 AB_Gurtschloss_FA 3;
BA_ "GenSigStartValue" SG_ 1312 AB_Gurtschloss_FA 1;
BA_ "GenSigSwitchedByIgnition" SG_ 1312 AB_Gurtschloss_FA 0;
BA_ "GenSigSendType" SG_ 1312 AB_Gurtschloss_Reihe2_BF 3;
BA_ "GenSigStartValue" SG_ 1312 AB_Gurtschloss_Reihe2_BF 1;
BA_ "GenSigSwitchedByIgnition" SG_ 1312 AB_Gurtschloss_Reihe2_BF 0;
BA_ "GenSigSendType" SG_ 1312 AB_Gurtschloss_Reihe2_FA 3;
BA_ "GenSigStartValue" SG_ 1312 AB_Gurtschloss_Reihe2_FA 1;
BA_ "GenSigSwitchedByIgnition" SG_ 1312 AB_Gurtschloss_Reihe2_FA 0;
BA_ "GenSigSendType" SG_ 1312 AB_Gurtschloss_Reihe2_MI 3;
BA_ "GenSigStartValue" SG_ 1312 AB_Gurtschloss_Reihe2_MI 1;
BA_ "GenSigSwitchedByIgnition" SG_ 1312 AB_Gurtschloss_Reihe2_MI 0;
BA_ "GenSigSendType" SG_ 1312 AB_Gurtschloss_Reihe3_BF 3;
BA_ "GenSigStartValue" SG_ 1312 AB_Gurtschloss_Reihe3_BF 1;
BA_ "GenSigSwitchedByIgnition" SG_ 1312 AB_Gurtschloss_Reihe3_BF 0;
BA_ "GenSigSendType" SG_ 1312 AB_Gurtschloss_Reihe3_FA 3;
BA_ "GenSigStartValue" SG_ 1312 AB_Gurtschloss_Reihe3_FA 1;
BA_ "GenSigSwitchedByIgnition" SG_ 1312 AB_Gurtschloss_Reihe3_FA 0;
BA_ "GenSigSendType" SG_ 1312 AB_Gurtschloss_Reihe3_MI 3;
BA_ "GenSigStartValue" SG_ 1312 AB_Gurtschloss_Reihe3_MI 1;
BA_ "GenSigSwitchedByIgnition" SG_ 1312 AB_Gurtschloss_Reihe3_MI 0;
BA_ "GenSigSendType" SG_ 1312 AB_Sitzpos_Sens_BF 0;
BA_ "GenSigSwitchedByIgnition" SG_ 1312 AB_Sitzpos_Sens_BF 0;
BA_ "Fehlerwert" SG_ 1312 AB_Sitzpos_Sens_BF 1;
BA_ "GenSigSendType" SG_ 1312 AB_Sitzpos_Sens_FA 0;
BA_ "GenSigSwitchedByIgnition" SG_ 1312 AB_Sitzpos_Sens_FA 0;
BA_ "Fehlerwert" SG_ 1312 AB_Sitzpos_Sens_FA 1;
BA_ "GenSigSendType" SG_ 1312 AB_Wickelklappung_Reihe2_BF 3;
BA_ "GenSigStartValue" SG_ 1312 AB_Wickelklappung_Reihe2_BF 1;
BA_ "GenSigSwitchedByIgnition" SG_ 1312 AB_Wickelklappung_Reihe2_BF 0;
BA_ "GenSigSendType" SG_ 1312 AB_Wickelklappung_Reihe2_FA 3;
BA_ "GenSigStartValue" SG_ 1312 AB_Wickelklappung_Reihe2_FA 1;
BA_ "GenSigSwitchedByIgnition" SG_ 1312 AB_Wickelklappung_Reihe2_FA 0;
BA_ "GenSigSendType" SG_ 1312 AB_Wickelklappung_Reihe2_MI 3;
BA_ "GenSigStartValue" SG_ 1312 AB_Wickelklappung_Reihe2_MI 1;
BA_ "GenSigSwitchedByIgnition" SG_ 1312 AB_Wickelklappung_Reihe2_MI 0;
BA_ "GenSigSendType" SG_ 1312 Airbag_02_BZ 0;
BA_ "GenSigFuncType" SG_ 1312 Airbag_02_BZ 1;
BA_ "GenSigSwitchedByIgnition" SG_ 1312 Airbag_02_BZ 0;
BA_ "GenSigSendType" SG_ 1312 Airbag_02_CRC 0;
BA_ "GenSigFuncType" SG_ 1312 Airbag_02_CRC 2;
BA_ "GenSigSwitchedByIgnition" SG_ 1312 Airbag_02_CRC 0;
BA_ "GenSigSendType" SG_ 1312 LoGeWa_Event_Kombiwarnung 3;
BA_ "GenSigSwitchedByIgnition" SG_ 1312 LoGeWa_Event_Kombiwarnung 0;
BA_ "GenSigSendType" SG_ 1312 SC_PAO_OFF_Anf 3;
BA_ "GenSigSwitchedByIgnition" SG_ 1312 SC_PAO_OFF_Anf 0;
BA_ "GenSigSendType" SG_ 1312 SC_PAO_ON_Anf 3;
BA_ "GenSigSwitchedByIgnition" SG_ 1312 SC_PAO_ON_Anf 0;
BA_ "GenSigSendType" SG_ 1312 SC_PAO_Schriftzug_Anf 3;
BA_ "GenSigSwitchedByIgnition" SG_ 1312 SC_PAO_Schriftzug_Anf 0;
BA_ "GenSigSendType" SG_ 1349 AB_Anprall_Front 3;
BA_ "GenSigSwitchedByIgnition" SG_ 1349 AB_Anprall_Front 0;
BA_ "GenSigSendType" SG_ 1349 AB_Anprall_Heck 3;
BA_ "GenSigSwitchedByIgnition" SG_ 1349 AB_Anprall_Heck 0;
BA_ "GenSigSendType" SG_ 1349 AB_Belegung_VF_ext 3;
BA_ "GenSigStartValue" SG_ 1349 AB_Belegung_VF_ext 6;
BA_ "GenSigSwitchedByIgnition" SG_ 1349 AB_Belegung_VF_ext 0;
BA_ "Fehlerwert" SG_ 1349 AB_Belegung_VF_ext 7;
BA_ "GenSigSendType" SG_ 1349 AB_Belegung_VF_ext_aktiv 3;
BA_ "GenSigSwitchedByIgnition" SG_ 1349 AB_Belegung_VF_ext_aktiv 0;
BA_ "GenSigSendType" SG_ 1349 AB_Gurtwarn_Reihe2_BF 0;
BA_ "GenSigSwitchedByIgnition" SG_ 1349 AB_Gurtwarn_Reihe2_BF 0;
BA_ "GenSigSendType" SG_ 1349 AB_Gurtwarn_Reihe2_FA 0;
BA_ "GenSigSwitchedByIgnition" SG_ 1349 AB_Gurtwarn_Reihe2_FA 0;
BA_ "GenSigSendType" SG_ 1349 AB_Gurtwarn_Reihe2_MI 0;
BA_ "GenSigSwitchedByIgnition" SG_ 1349 AB_Gurtwarn_Reihe2_MI 0;
BA_ "GenSigSendType" SG_ 1349 AB_Gurtwarn_Reihe3_BF 0;
BA_ "GenSigSwitchedByIgnition" SG_ 1349 AB_Gurtwarn_Reihe3_BF 0;
BA_ "GenSigSendType" SG_ 1349 AB_Gurtwarn_Reihe3_FA 0;
BA_ "GenSigSwitchedByIgnition" SG_ 1349 AB_Gurtwarn_Reihe3_FA 0;
BA_ "GenSigSendType" SG_ 1349 AB_Gurtwarn_Reihe3_MI 0;
BA_ "GenSigSwitchedByIgnition" SG_ 1349 AB_Gurtwarn_Reihe3_MI 0;
BA_ "GenSigSendType" SG_ 1349 AB_Gurtwarn_Reihe4_BF 0;
BA_ "GenSigSwitchedByIgnition" SG_ 1349 AB_Gurtwarn_Reihe4_BF 0;
BA_ "GenSigSendType" SG_ 1349 AB_Gurtwarn_Reihe4_FA 0;
BA_ "GenSigSwitchedByIgnition" SG_ 1349 AB_Gurtwarn_Reihe4_FA 0;
BA_ "GenSigSendType" SG_ 1349 AB_Gurtwarn_Reihe4_MI 0;
BA_ "GenSigSwitchedByIgnition" SG_ 1349 AB_Gurtwarn_Reihe4_MI 0;
BA_ "GenSigSendType" SG_ 1349 AB_SBR_hinten_verbau 0;
BA_ "GenSigStartValue" SG_ 1349 AB_SBR_hinten_verbau 3;
BA_ "GenSigSwitchedByIgnition" SG_ 1349 AB_SBR_hinten_verbau 0;
BA_ "GenSigSendType" SG_ 1349 AbstWarn_MV_FAS_Fkt_Status 3;
BA_ "GenSigSwitchedByIgnition" SG_ 1349 AbstWarn_MV_FAS_Fkt_Status 0;
BA_ "Fehlerwert" SG_ 1349 AbstWarn_MV_FAS_Fkt_Status 3;
BA_ "GenSigSendType" SG_ 1349 Airbag_04_BZ 0;
BA_ "GenSigFuncType" SG_ 1349 Airbag_04_BZ 1;
BA_ "GenSigSwitchedByIgnition" SG_ 1349 Airbag_04_BZ 0;
BA_ "GenSigSendType" SG_ 1349 Airbag_04_CRC 0;
BA_ "GenSigFuncType" SG_ 1349 Airbag_04_CRC 2;
BA_ "GenSigSwitchedByIgnition" SG_ 1349 Airbag_04_CRC 0;
BA_ "GenSigSendType" SG_ 1349 AWV_Einstellung_System_ASG 3;
BA_ "GenSigSwitchedByIgnition" SG_ 1349 AWV_Einstellung_System_ASG 0;
BA_ "GenSigSendType" SG_ 1349 AWV_Einstellung_Warnung_ASG 3;
BA_ "GenSigSwitchedByIgnition" SG_ 1349 AWV_Einstellung_Warnung_ASG 0;
BA_ "GenSigSendType" SG_ 1349 LGI_FAS_Fkt_Status 3;
BA_ "GenSigSwitchedByIgnition" SG_ 1349 LGI_FAS_Fkt_Status 0;
BA_ "Fehlerwert" SG_ 1349 LGI_FAS_Fkt_Status 3;
BA_ "GenSigSendType" SG_ 1349 PreCrash_FAS_Fkt_Status 3;
BA_ "GenSigSwitchedByIgnition" SG_ 1349 PreCrash_FAS_Fkt_Status 0;
BA_ "Fehlerwert" SG_ 1349 PreCrash_FAS_Fkt_Status 3;
BA_ "GenSigSendType" SG_ 1349 SC_PreSense_Modus_System_KAS 3;
BA_ "GenSigSwitchedByIgnition" SG_ 1349 SC_PreSense_Modus_System_KAS 0;
BA_ "GenSigSendType" SG_ 1349 SC_PreSense_Modus_System_MV 3;
BA_ "GenSigSwitchedByIgnition" SG_ 1349 SC_PreSense_Modus_System_MV 0;
BA_ "GenSigSendType" SG_ 1349 SC_PreSense_Modus_System_NV 3;
BA_ "GenSigSwitchedByIgnition" SG_ 1349 SC_PreSense_Modus_System_NV 0;
BA_ "GenSigSendType" SG_ 1349 SC_PreSense_Modus_Warnung_MV 3;
BA_ "GenSigSwitchedByIgnition" SG_ 1349 SC_PreSense_Modus_Warnung_MV 0;
BA_ "GenSigSendType" SG_ 1349 SC_PreSense_Modus_Warnung_NV 3;
BA_ "GenSigSwitchedByIgnition" SG_ 1349 SC_PreSense_Modus_Warnung_NV 0;
BA_ "GenSigSendType" SG_ 1349 WarnBrems_Charisma_FahrPr 0;
BA_ "GenSigSendType" SG_ 1349 WarnBrems_Charisma_Status 0;
BA_ "GenSigSendType" SG_ 1633 AAG_Anhaenger_abgesteckt 0;
BA_ "GenSigSwitchedByIgnition" SG_ 1633 AAG_Anhaenger_abgesteckt 0;
BA_ "GenSigSendType" SG_ 1633 AAG_Anhaenger_erkannt 0;
BA_ "NWM-WakeupAllowed" SG_ 1633 AAG_Anhaenger_erkannt 1;
BA_ "GenSigSwitchedByIgnition" SG_ 1633 AAG_Anhaenger_erkannt 0;
BA_ "GenSigSendType" SG_ 1633 AAG_AVS_Fehler_02 0;
BA_ "GenSigSwitchedByIgnition" SG_ 1633 AAG_AVS_Fehler_02 0;
BA_ "Fehlerwert" SG_ 1633 AAG_AVS_Fehler_02 1;
BA_ "GenSigSendType" SG_ 1633 AAG_AVS_Fehler_02_inv 0;
BA_ "GenSigStartValue" SG_ 1633 AAG_AVS_Fehler_02_inv 1;
BA_ "GenSigSwitchedByIgnition" SG_ 1633 AAG_AVS_Fehler_02_inv 0;
BA_ "GenSigSendType" SG_ 1633 AAG_AVS_Stati 0;
BA_ "GenSigSwitchedByIgnition" SG_ 1633 AAG_AVS_Stati 0;
BA_ "GenSigSendType" SG_ 1633 AAG_Blinker_H_aktiv 0;
BA_ "GenSigSwitchedByIgnition" SG_ 1633 AAG_Blinker_H_aktiv 0;
BA_ "GenSigSendType" SG_ 1633 AAG_Blinker_HL_def 0;
BA_ "GenSigSwitchedByIgnition" SG_ 1633 AAG_Blinker_HL_def 0;
BA_ "GenSigSendType" SG_ 1633 AAG_Blinker_HR_def 0;
BA_ "GenSigSwitchedByIgnition" SG_ 1633 AAG_Blinker_HR_def 0;
BA_ "GenSigSendType" SG_ 1633 AAG_Bremsl_durch_ECD 0;
BA_ "GenSigSwitchedByIgnition" SG_ 1633 AAG_Bremsl_durch_ECD 0;
BA_ "GenSigSendType" SG_ 1633 AAG_Bremslicht_H_def 0;
BA_ "GenSigSwitchedByIgnition" SG_ 1633 AAG_Bremslicht_H_def 0;
BA_ "GenSigSendType" SG_ 1633 AAG_Bremslicht_Reku 0;
BA_ "GenSigSwitchedByIgnition" SG_ 1633 AAG_Bremslicht_Reku 0;
BA_ "GenSigSendType" SG_ 1633 AAG_BZ 0;
BA_ "GenSigFuncType" SG_ 1633 AAG_BZ 1;
BA_ "GenSigSwitchedByIgnition" SG_ 1633 AAG_BZ 0;
BA_ "GenSigSendType" SG_ 1633 AAG_LED_aktiv 0;
BA_ "GenSigSwitchedByIgnition" SG_ 1633 AAG_LED_aktiv 0;
BA_ "GenSigSendType" SG_ 1633 AAG_NSL_aktiv 0;
BA_ "GenSigSwitchedByIgnition" SG_ 1633 AAG_NSL_aktiv 0;
BA_ "GenSigSendType" SG_ 1633 AAG_Schlusslicht_HL_def 0;
BA_ "GenSigSwitchedByIgnition" SG_ 1633 AAG_Schlusslicht_HL_def 0;
BA_ "GenSigSendType" SG_ 1633 AAG_Schlusslicht_HR_def 0;
BA_ "GenSigSwitchedByIgnition" SG_ 1633 AAG_Schlusslicht_HR_def 0;
BA_ "GenSigSendType" SG_ 345 ARA_Aktiver_Grafikmodus 0;
BA_ "GenSigSendType" SG_ 345 ARA_Bremsfuss 0;
BA_ "GenSigSendType" SG_ 345 ARA_Deaktivierung_sperren 3;
BA_ "GenSigSendType" SG_ 345 ARA_Knickwinkel_Ist 3;
BA_ "GenSigStartValue" SG_ 345 ARA_Knickwinkel_Ist 254;
BA_ "Fehlerwert" SG_ 345 ARA_Knickwinkel_Ist 255;
BA_ "GenSigSendType" SG_ 345 ARA_Knickwinkel_Komfort 3;
BA_ "GenSigStartValue" SG_ 345 ARA_Knickwinkel_Komfort 62;
BA_ "GenSigSwitchedByIgnition" SG_ 345 ARA_Knickwinkel_Komfort 0;
BA_ "Fehlerwert" SG_ 345 ARA_Knickwinkel_Komfort 63;
BA_ "GenSigSendType" SG_ 345 ARA_Knickwinkel_Konfidenz 0;
BA_ "GenSigStartValue" SG_ 345 ARA_Knickwinkel_Konfidenz 126;
BA_ "GenSigSwitchedByIgnition" SG_ 345 ARA_Knickwinkel_Konfidenz 0;
BA_ "Fehlerwert" SG_ 345 ARA_Knickwinkel_Konfidenz 127;
BA_ "GenSigSendType" SG_ 345 ARA_Knickwinkel_Max 3;
BA_ "GenSigStartValue" SG_ 345 ARA_Knickwinkel_Max 126;
BA_ "Fehlerwert" SG_ 345 ARA_Knickwinkel_Max 127;
BA_ "GenSigSendType" SG_ 345 ARA_Knickwinkel_Soll 3;
BA_ "GenSigStartValue" SG_ 345 ARA_Knickwinkel_Soll 254;
BA_ "Fehlerwert" SG_ 345 ARA_Knickwinkel_Soll 255;
BA_ "GenSigSendType" SG_ 345 ARA_Modus 0;
BA_ "GenSigSendType" SG_ 345 ARA_Modus_Anf 0;
BA_ "GenSigSendType" SG_ 345 ARA_Sensor_Aktivierung 3;
BA_ "GenSigSendType" SG_ 345 ARA_Status 3;
BA_ "GenSigStartValue" SG_ 345 ARA_Status 1;
BA_ "Fehlerwert" SG_ 345 ARA_Status 2;
BA_ "GenSigSendType" SG_ 345 ARA_Texte 0;
BA_ "Fehlerwert" SG_ 345 ARA_Texte 63;
BA_ "GenSigSendType" SG_ 2536767264 BAP_Debug_Cmd 3;
BA_ "GenSigSwitchedByIgnition" SG_ 2536767264 BAP_Debug_Cmd 0;
BA_ "GenSigSendType" SG_ 2536767280 BAP_Debug_Data 3;
BA_ "GenSigSwitchedByIgnition" SG_ 2536767280 BAP_Debug_Data 0;
BA_ "GenSigSendType" SG_ 2536734208 BAP_DrivingDynamics_ASG_01_Hdr 3;
BA_ "GenSigSwitchedByIgnition" SG_ 2536734208 BAP_DrivingDynamics_ASG_01_Hdr 0;
BA_ "GenSigSendType" SG_ 2536734224 BAP_DrivingDynamics_FSG_01_Hdr 3;
BA_ "GenSigSwitchedByIgnition" SG_ 2536734224 BAP_DrivingDynamics_FSG_01_Hdr 0;
BA_ "GenSigSendType" SG_ 2536717312 BAP_EfficAssist_ASG_01_Header 3;
BA_ "GenSigSwitchedByIgnition" SG_ 2536717312 BAP_EfficAssist_ASG_01_Header 0;
BA_ "GenSigSendType" SG_ 2536717313 BAP_EfficAssist_ASG_02_Header 3;
BA_ "GenSigSwitchedByIgnition" SG_ 2536717313 BAP_EfficAssist_ASG_02_Header 0;
BA_ "GenSigSendType" SG_ 2536717328 BAP_EfficAssist_FSG_01_Header 3;
BA_ "GenSigSwitchedByIgnition" SG_ 2536717328 BAP_EfficAssist_FSG_01_Header 0;
BA_ "GenSigSendType" SG_ 2536725760 BAP_EngFunctions_ASG_01_Header 3;
BA_ "GenSigSwitchedByIgnition" SG_ 2536725760 BAP_EngFunctions_ASG_01_Header 0;
BA_ "GenSigSendType" SG_ 2536725776 BAP_EngFunctions_FSG_01_Header 3;
BA_ "GenSigSwitchedByIgnition" SG_ 2536725776 BAP_EngFunctions_FSG_01_Header 0;
BA_ "GenSigSendType" SG_ 2536709120 BAP_Hybrid_ASG_01_Header 3;
BA_ "GenSigSwitchedByIgnition" SG_ 2536709120 BAP_Hybrid_ASG_01_Header 0;
BA_ "GenSigSendType" SG_ 2536709121 BAP_Hybrid_ASG_02_Header 3;
BA_ "GenSigSwitchedByIgnition" SG_ 2536709121 BAP_Hybrid_ASG_02_Header 0;
BA_ "GenSigSendType" SG_ 2536709136 BAP_Hybrid_FSG_01_Header 3;
BA_ "GenSigSwitchedByIgnition" SG_ 2536709136 BAP_Hybrid_FSG_01_Header 0;
BA_ "GenSigSendType" SG_ 2536716545 BAP_RangeData_ASG_02_Header 3;
BA_ "GenSigSwitchedByIgnition" SG_ 2536716545 BAP_RangeData_ASG_02_Header 0;
BA_ "GenSigSendType" SG_ 2536716560 BAP_RangeData_FSG_01_Header 3;
BA_ "GenSigSwitchedByIgnition" SG_ 2536716560 BAP_RangeData_FSG_01_Header 0;
BA_ "GenSigSendType" SG_ 1626 APS_Tongeber_defekt 3;
BA_ "GenSigSwitchedByIgnition" SG_ 1626 APS_Tongeber_defekt 0;
BA_ "GenSigSendType" SG_ 1626 BCM1_AFS_Lampe 3;
BA_ "GenSigSwitchedByIgnition" SG_ 1626 BCM1_AFS_Lampe 0;
BA_ "GenSigSendType" SG_ 1626 BCM1_EasyEntry_Status 3;
BA_ "GenSigSwitchedByIgnition" SG_ 1626 BCM1_EasyEntry_Status 0;
BA_ "GenSigSendType" SG_ 1626 BCM1_Fahrlicht_Hinweis 3;
BA_ "GenSigSwitchedByIgnition" SG_ 1626 BCM1_Fahrlicht_Hinweis 0;
BA_ "GenSigSendType" SG_ 1626 BCM1_Hinweis_Lichtnachlauf 3;
BA_ "GenSigSwitchedByIgnition" SG_ 1626 BCM1_Hinweis_Lichtnachlauf 0;
BA_ "GenSigSendType" SG_ 1626 BCM1_Kl_15_HW_erkannt 3;
BA_ "GenSigSwitchedByIgnition" SG_ 1626 BCM1_Kl_15_HW_erkannt 0;
BA_ "GenSigSendType" SG_ 1626 BCM1_Kl_15_Sig_HW_erkannt 3;
BA_ "GenSigSwitchedByIgnition" SG_ 1626 BCM1_Kl_15_Sig_HW_erkannt 0;
BA_ "GenSigSendType" SG_ 1626 BCM1_LDS_Stellung 3;
BA_ "GenSigSwitchedByIgnition" SG_ 1626 BCM1_LDS_Stellung 0;
BA_ "Fehlerwert" SG_ 1626 BCM1_LDS_Stellung 7;
BA_ "GenSigSendType" SG_ 1626 BCM1_Lenksaeule_aktiv 3;
BA_ "GenSigSwitchedByIgnition" SG_ 1626 BCM1_Lenksaeule_aktiv 0;
BA_ "GenSigSendType" SG_ 1626 BCM1_Licht_Warn 3;
BA_ "GenSigSwitchedByIgnition" SG_ 1626 BCM1_Licht_Warn 0;
BA_ "GenSigSendType" SG_ 1626 BCM1_Lichtwarn_Texte 3;
BA_ "GenSigSwitchedByIgnition" SG_ 1626 BCM1_Lichtwarn_Texte 0;
BA_ "GenSigSendType" SG_ 1626 BCM1_MH_Schalter 3;
BA_ "GenSigSwitchedByIgnition" SG_ 1626 BCM1_MH_Schalter 0;
BA_ "GenSigSendType" SG_ 1626 BCM1_MH_WIV_Schalter 3;
BA_ "GenSigSwitchedByIgnition" SG_ 1626 BCM1_MH_WIV_Schalter 0;
BA_ "GenSigSendType" SG_ 1626 BCM1_NV_Taster 0;
BA_ "GenSigSwitchedByIgnition" SG_ 1626 BCM1_NV_Taster 0;
BA_ "GenSigSendType" SG_ 1626 BCM1_Reisemodus_Texte 3;
BA_ "GenSigSwitchedByIgnition" SG_ 1626 BCM1_Reisemodus_Texte 0;
BA_ "GenSigSendType" SG_ 1626 BCM1_Rueckfahrlicht_Schalter 3;
BA_ "GenSigSwitchedByIgnition" SG_ 1626 BCM1_Rueckfahrlicht_Schalter 0;
BA_ "GenSigSendType" SG_ 1626 BCM1_Spannungs_Anf 3;
BA_ "GenSigSwitchedByIgnition" SG_ 1626 BCM1_Spannungs_Anf 0;
BA_ "GenSigSendType" SG_ 1626 BCM1_Valet_Parking_Taster 0;
BA_ "GenSigSwitchedByIgnition" SG_ 1626 BCM1_Valet_Parking_Taster 0;
BA_ "GenSigSendType" SG_ 1626 BCM1_Warnblink_Taster 3;
BA_ "GenSigSwitchedByIgnition" SG_ 1626 BCM1_Warnblink_Taster 0;
BA_ "GenSigSendType" SG_ 1626 BCM_Anf_AAW_MoLaWa 3;
BA_ "GenSigSwitchedByIgnition" SG_ 1626 BCM_Anf_AAW_MoLaWa 0;
BA_ "GenSigSendType" SG_ 1626 BCM_Bremsbelag_Sensor 3;
BA_ "GenSigSwitchedByIgnition" SG_ 1626 BCM_Bremsbelag_Sensor 0;
BA_ "GenSigSendType" SG_ 1626 BCM_Bremsfluessigkeit_Sensor 3;
BA_ "GenSigSwitchedByIgnition" SG_ 1626 BCM_Bremsfluessigkeit_Sensor 0;
BA_ "GenSigSendType" SG_ 1626 BCM_Charisma_Taste2 3;
BA_ "GenSigSwitchedByIgnition" SG_ 1626 BCM_Charisma_Taste2 0;
BA_ "GenSigSendType" SG_ 1626 BCM_Eco_Charisma_Taste 3;
BA_ "GenSigSwitchedByIgnition" SG_ 1626 BCM_Eco_Charisma_Taste 0;
BA_ "GenSigSendType" SG_ 1626 BCM_Handbremse_Hinweis 4;
BA_ "GenSigSwitchedByIgnition" SG_ 1626 BCM_Handbremse_Hinweis 0;
BA_ "GenSigSendType" SG_ 1626 BCM_HBFS_EOE_aktiv 4;
BA_ "GenSigSwitchedByIgnition" SG_ 1626 BCM_HBFS_EOE_aktiv 0;
BA_ "GenSigSendType" SG_ 1626 BCM_HDF_betaetigt 4;
BA_ "GenSigSwitchedByIgnition" SG_ 1626 BCM_HDF_betaetigt 0;
BA_ "GenSigSendType" SG_ 1626 BCM_HFS_EOE_aktiv 4;
BA_ "GenSigSwitchedByIgnition" SG_ 1626 BCM_HFS_EOE_aktiv 0;
BA_ "GenSigSendType" SG_ 1626 BCM_Hybrid_StartStopp_Taste 3;
BA_ "GenSigSwitchedByIgnition" SG_ 1626 BCM_Hybrid_StartStopp_Taste 0;
BA_ "GenSigSendType" SG_ 1626 BCM_Hybrid_StSt_Taste_Fehler 3;
BA_ "GenSigSwitchedByIgnition" SG_ 1626 BCM_Hybrid_StSt_Taste_Fehler 0;
BA_ "GenSigSendType" SG_ 1626 BCM_Kuehlmittel_Sensor 3;
BA_ "GenSigSwitchedByIgnition" SG_ 1626 BCM_Kuehlmittel_Sensor 0;
BA_ "GenSigSendType" SG_ 1626 BCM_Kuehlmittel_Sensor_02 3;
BA_ "GenSigSwitchedByIgnition" SG_ 1626 BCM_Kuehlmittel_Sensor_02 0;
BA_ "GenSigSendType" SG_ 1626 BCM_Offroad_Taste 3;
BA_ "GenSigSwitchedByIgnition" SG_ 1626 BCM_Offroad_Taste 0;
BA_ "GenSigSendType" SG_ 1626 BCM_ValetTaster_Fkts_LED 4;
BA_ "GenSigSwitchedByIgnition" SG_ 1626 BCM_ValetTaster_Fkts_LED 0;
BA_ "GenSigSendType" SG_ 1626 BCM_Waehlhebel_P_Hinweis 4;
BA_ "GenSigSwitchedByIgnition" SG_ 1626 BCM_Waehlhebel_P_Hinweis 0;
BA_ "GenSigSendType" SG_ 1626 BCM_Waschwasser_Sensor 3;
BA_ "GenSigSwitchedByIgnition" SG_ 1626 BCM_Waschwasser_Sensor 0;
BA_ "GenSigSendType" SG_ 1626 DWA_Alarmquelle 0;
BA_ "GenSigStartValue" SG_ 1626 DWA_Alarmquelle 30;
BA_ "GenSigSwitchedByIgnition" SG_ 1626 DWA_Alarmquelle 0;
BA_ "Fehlerwert" SG_ 1626 DWA_Alarmquelle 31;
BA_ "GenSigSendType" SG_ 1626 DWA_Einschraenkung 0;
BA_ "GenSigSwitchedByIgnition" SG_ 1626 DWA_Einschraenkung 0;
BA_ "Fehlerwert" SG_ 1626 DWA_Einschraenkung 1;
BA_ "GenSigSendType" SG_ 1626 Gong_TFL_Umschaltung 3;
BA_ "GenSigSwitchedByIgnition" SG_ 1626 Gong_TFL_Umschaltung 0;
BA_ "GenSigSendType" SG_ 1626 LRH_Taster 3;
BA_ "GenSigSwitchedByIgnition" SG_ 1626 LRH_Taster 0;
BA_ "GenSigSendType" SG_ 869 BEM_Anf_KL 0;
BA_ "GenSigSwitchedByIgnition" SG_ 869 BEM_Anf_KL 0;
BA_ "GenSigSendType" SG_ 869 BEM_Batt_Ab 0;
BA_ "GenSigSwitchedByIgnition" SG_ 869 BEM_Batt_Ab 0;
BA_ "GenSigSendType" SG_ 869 BEM_DFM 0;
BA_ "GenSigSwitchedByIgnition" SG_ 869 BEM_DFM 0;
BA_ "GenSigSendType" SG_ 869 BEM_EMLIN_ungueltig 0;
BA_ "GenSigSwitchedByIgnition" SG_ 869 BEM_EMLIN_ungueltig 0;
BA_ "GenSigSendType" SG_ 869 BEM_HYB_DC_uMinLV 0;
BA_ "GenSigStartValue" SG_ 869 BEM_HYB_DC_uMinLV 254;
BA_ "GenSigSwitchedByIgnition" SG_ 869 BEM_HYB_DC_uMinLV 0;
BA_ "Fehlerwert" SG_ 869 BEM_HYB_DC_uMinLV 255;
BA_ "GenSigSendType" SG_ 869 BEM_HYB_DC_uSollLV 0;
BA_ "GenSigStartValue" SG_ 869 BEM_HYB_DC_uSollLV 37;
BA_ "GenSigSwitchedByIgnition" SG_ 869 BEM_HYB_DC_uSollLV 0;
BA_ "GenSigSendType" SG_ 869 BEM_n_LLA 0;
BA_ "GenSigSwitchedByIgnition" SG_ 869 BEM_n_LLA 0;
BA_ "GenSigSendType" SG_ 869 BEM_P_Generator 0;
BA_ "GenSigSwitchedByIgnition" SG_ 869 BEM_P_Generator 0;
BA_ "Fehlerwert" SG_ 869 BEM_P_Generator 255;
BA_ "GenSigSendType" SG_ 869 BEM_Segel_Info 0;
BA_ "GenSigSwitchedByIgnition" SG_ 869 BEM_Segel_Info 0;
BA_ "GenSigSendType" SG_ 869 BEM_StartStopp_Info 0;
BA_ "GenSigSwitchedByIgnition" SG_ 869 BEM_StartStopp_Info 0;
BA_ "GenSigSendType" SG_ 869 BEM_UBDM 0;
BA_ "GenSigSwitchedByIgnition" SG_ 869 BEM_UBDM 0;
BA_ "Fehlerwert" SG_ 869 BEM_UBDM 255;
BA_ "GenSigSendType" SG_ 869 NVEM_Abschaltstufe 0;
BA_ "GenSigSwitchedByIgnition" SG_ 869 NVEM_Abschaltstufe 0;
BA_ "GenSigSendType" SG_ 869 NVEM_FMAus_I_Verbrauch 0;
BA_ "GenSigStartValue" SG_ 869 NVEM_FMAus_I_Verbrauch 30;
BA_ "GenSigSwitchedByIgnition" SG_ 869 NVEM_FMAus_I_Verbrauch 0;
BA_ "Fehlerwert" SG_ 869 NVEM_FMAus_I_Verbrauch 31;
BA_ "GenSigSendType" SG_ 869 NVEM_FMAus_Info 0;
BA_ "GenSigStartValue" SG_ 869 NVEM_FMAus_Info 1;
BA_ "GenSigSwitchedByIgnition" SG_ 869 NVEM_FMAus_Info 0;
BA_ "GenSigSendType" SG_ 869 NVEM_Freilauf_Info 0;
BA_ "GenSigSwitchedByIgnition" SG_ 869 NVEM_Freilauf_Info 0;
BA_ "GenSigSendType" SG_ 869 NVEM_Ladefreigabe 0;
BA_ "GenSigSwitchedByIgnition" SG_ 869 NVEM_Ladefreigabe 0;
BA_ "GenSigSendType" SG_ 869 NVEM_P_Generator_Status 0;
BA_ "GenSigSwitchedByIgnition" SG_ 869 NVEM_P_Generator_Status 0;
BA_ "GenSigSendType" SG_ 869 NVEM_PTC_Sollstufe 0;
BA_ "GenSigSwitchedByIgnition" SG_ 869 NVEM_PTC_Sollstufe 0;
BA_ "GenSigSendType" SG_ 869 NVEM_Red_KL 0;
BA_ "GenSigSwitchedByIgnition" SG_ 869 NVEM_Red_KL 0;
BA_ "GenSigSendType" SG_ 1163 BEM_06_BZ 0;
BA_ "GenSigFuncType" SG_ 1163 BEM_06_BZ 1;
BA_ "GenSigSwitchedByIgnition" SG_ 1163 BEM_06_BZ 0;
BA_ "GenSigSendType" SG_ 1163 BEM_06_CRC 0;
BA_ "GenSigFuncType" SG_ 1163 BEM_06_CRC 2;
BA_ "GenSigSwitchedByIgnition" SG_ 1163 BEM_06_CRC 0;
BA_ "GenSigSendType" SG_ 1163 HLR_PTC_linear_Freigabe 0;
BA_ "GenSigSwitchedByIgnition" SG_ 1163 HLR_PTC_linear_Freigabe 0;
BA_ "Fehlerwert" SG_ 1163 HLR_PTC_linear_Freigabe 63;
BA_ "GenSigSendType" SG_ 1163 NVEM2_Status_FuSiFahrt 0;
BA_ "GenSigSwitchedByIgnition" SG_ 1163 NVEM2_Status_FuSiFahrt 0;
BA_ "Fehlerwert" SG_ 1163 NVEM2_Status_FuSiFahrt 7;
BA_ "GenSigSendType" SG_ 1163 NVEM2_Typ_EnergieNetz 0;
BA_ "GenSigStartValue" SG_ 1163 NVEM2_Typ_EnergieNetz 15;
BA_ "GenSigSwitchedByIgnition" SG_ 1163 NVEM2_Typ_EnergieNetz 0;
BA_ "Fehlerwert" SG_ 1163 NVEM2_Typ_EnergieNetz 14;
BA_ "GenSigSendType" SG_ 1163 NVEM_Betriebsart 0;
BA_ "GenSigSwitchedByIgnition" SG_ 1163 NVEM_Betriebsart 0;
BA_ "Fehlerwert" SG_ 1163 NVEM_Betriebsart 15;
BA_ "GenSigSendType" SG_ 1163 NVEM_Bordnetzdiagnose 0;
BA_ "GenSigSwitchedByIgnition" SG_ 1163 NVEM_Bordnetzdiagnose 0;
BA_ "GenSigSendType" SG_ 1163 NVEM_Energie_Klima_Vorgabe 0;
BA_ "GenSigStartValue" SG_ 1163 NVEM_Energie_Klima_Vorgabe 254;
BA_ "GenSigSwitchedByIgnition" SG_ 1163 NVEM_Energie_Klima_Vorgabe 0;
BA_ "Fehlerwert" SG_ 1163 NVEM_Energie_Klima_Vorgabe 255;
BA_ "GenSigSendType" SG_ 1163 NVEM_Energienetz_Status 0;
BA_ "GenSigStartValue" SG_ 1163 NVEM_Energienetz_Status 6;
BA_ "GenSigSwitchedByIgnition" SG_ 1163 NVEM_Energienetz_Status 0;
BA_ "Fehlerwert" SG_ 1163 NVEM_Energienetz_Status 7;
BA_ "GenSigSendType" SG_ 1163 NVEM_Ladezustand 0;
BA_ "GenSigStartValue" SG_ 1163 NVEM_Ladezustand 126;
BA_ "GenSigSwitchedByIgnition" SG_ 1163 NVEM_Ladezustand 0;
BA_ "Fehlerwert" SG_ 1163 NVEM_Ladezustand 127;
BA_ "GenSigSendType" SG_ 1163 NVEM_Last_Anf 0;
BA_ "GenSigSwitchedByIgnition" SG_ 1163 NVEM_Last_Anf 0;
BA_ "GenSigSendType" SG_ 1163 NVEM_PTC_Sollstufe 0;
BA_ "GenSigSwitchedByIgnition" SG_ 1163 NVEM_PTC_Sollstufe 0;
BA_ "GenSigSendType" SG_ 1163 NVEM_Red_KomfortVerbrauch 0;
BA_ "GenSigSwitchedByIgnition" SG_ 1163 NVEM_Red_KomfortVerbrauch 0;
BA_ "Fehlerwert" SG_ 1163 NVEM_Red_KomfortVerbrauch 15;
BA_ "GenSigSendType" SG_ 1163 NVEM_STH_ZielzeitLang 0;
BA_ "GenSigStartValue" SG_ 1163 NVEM_STH_ZielzeitLang 14;
BA_ "GenSigSwitchedByIgnition" SG_ 1163 NVEM_STH_ZielzeitLang 0;
BA_ "Fehlerwert" SG_ 1163 NVEM_STH_ZielzeitLang 15;
BA_ "GenSigSendType" SG_ 1163 NVEM_Vorgabe_Leistungsstufe 0;
BA_ "GenSigSwitchedByIgnition" SG_ 1163 NVEM_Vorgabe_Leistungsstufe 0;
BA_ "Fehlerwert" SG_ 1163 NVEM_Vorgabe_Leistungsstufe 7;
BA_ "GenSigSendType" SG_ 2463978850 BEM_07_BZ 0;
BA_ "GenSigFuncType" SG_ 2463978850 BEM_07_BZ 1;
BA_ "GenSigSwitchedByIgnition" SG_ 2463978850 BEM_07_BZ 0;
BA_ "GenSigSendType" SG_ 2463978850 BEM_07_CRC 0;
BA_ "GenSigFuncType" SG_ 2463978850 BEM_07_CRC 2;
BA_ "GenSigSwitchedByIgnition" SG_ 2463978850 BEM_07_CRC 0;
BA_ "GenSigSendType" SG_ 2463978850 NVEM2_VerbrZustandsAnf 0;
BA_ "GenSigStartValue" SG_ 2463978850 NVEM2_VerbrZustandsAnf 14;
BA_ "GenSigSwitchedByIgnition" SG_ 2463978850 NVEM2_VerbrZustandsAnf 0;
BA_ "Fehlerwert" SG_ 2463978850 NVEM2_VerbrZustandsAnf 15;
BA_ "GenSigSendType" SG_ 2463978850 NVEM3_Absch_SCR 0;
BA_ "GenSigSwitchedByIgnition" SG_ 2463978850 NVEM3_Absch_SCR 0;
BA_ "GenSigSendType" SG_ 2463978850 NVEM_Batt_Temp_Hinweis 0;
BA_ "GenSigSwitchedByIgnition" SG_ 2463978850 NVEM_Batt_Temp_Hinweis 0;
BA_ "GenSigSendType" SG_ 2463978850 NVEM_Bordnetz_Information 0;
BA_ "GenSigStartValue" SG_ 2463978850 NVEM_Bordnetz_Information 14;
BA_ "GenSigSwitchedByIgnition" SG_ 2463978850 NVEM_Bordnetz_Information 0;
BA_ "Fehlerwert" SG_ 2463978850 NVEM_Bordnetz_Information 15;
BA_ "GenSigSendType" SG_ 2463978850 NVEM_NVStuetzungAnf 0;
BA_ "GenSigSwitchedByIgnition" SG_ 2463978850 NVEM_NVStuetzungAnf 0;
BA_ "Fehlerwert" SG_ 2463978850 NVEM_NVStuetzungAnf 3;
BA_ "GenSigSendType" SG_ 2463978850 NVEM_Verbraucher_Information 0;
BA_ "GenSigStartValue" SG_ 2463978850 NVEM_Verbraucher_Information 6;
BA_ "GenSigSwitchedByIgnition" SG_ 2463978850 NVEM_Verbraucher_Information 0;
BA_ "Fehlerwert" SG_ 2463978850 NVEM_Verbraucher_Information 7;
BA_ "GenSigSendType" SG_ 1442 BMS_04_BZ 0;
BA_ "GenSigFuncType" SG_ 1442 BMS_04_BZ 1;
BA_ "GenSigSwitchedByIgnition" SG_ 1442 BMS_04_BZ 0;
BA_ "GenSigSendType" SG_ 1442 BMS_04_CRC 0;
BA_ "GenSigFuncType" SG_ 1442 BMS_04_CRC 2;
BA_ "GenSigSwitchedByIgnition" SG_ 1442 BMS_04_CRC 0;
BA_ "GenSigSendType" SG_ 1442 BMS_Fehler_Pilot 0;
BA_ "GenSigSwitchedByIgnition" SG_ 1442 BMS_Fehler_Pilot 0;
BA_ "GenSigSendType" SG_ 1442 BMS_Fehlerlampe_Anf 0;
BA_ "GenSigSwitchedByIgnition" SG_ 1442 BMS_Fehlerlampe_Anf 0;
BA_ "GenSigSendType" SG_ 1442 BMS_Fehlerstatus 3;
BA_ "GenSigStartValue" SG_ 1442 BMS_Fehlerstatus 7;
BA_ "GenSigSwitchedByIgnition" SG_ 1442 BMS_Fehlerstatus 0;
BA_ "GenSigSendType" SG_ 1442 BMS_Kapazitaet_02 0;
BA_ "GenSigStartValue" SG_ 1442 BMS_Kapazitaet_02 2047;
BA_ "GenSigSwitchedByIgnition" SG_ 1442 BMS_Kapazitaet_02 0;
BA_ "GenSigSendType" SG_ 1442 BMS_Kl30c_Status 4;
BA_ "GenSigSwitchedByIgnition" SG_ 1442 BMS_Kl30c_Status 0;
BA_ "Fehlerwert" SG_ 1442 BMS_Kl30c_Status 3;
BA_ "GenSigSendType" SG_ 1442 BMS_OBD_Lampe_Anf 0;
BA_ "GenSigSwitchedByIgnition" SG_ 1442 BMS_OBD_Lampe_Anf 0;
BA_ "GenSigSendType" SG_ 1442 BMS_Status_ServiceDisconnect 0;
BA_ "GenSigSwitchedByIgnition" SG_ 1442 BMS_Status_ServiceDisconnect 0;
BA_ "GenSigSendType" SG_ 1442 BMS_Status_Spgfreiheit 0;
BA_ "GenSigSwitchedByIgnition" SG_ 1442 BMS_Status_Spgfreiheit 0;
BA_ "GenSigSendType" SG_ 1442 BMS_Warnlampe_Anf 0;
BA_ "GenSigSwitchedByIgnition" SG_ 1442 BMS_Warnlampe_Anf 0;
BA_ "GenSigSendType" SG_ 1450 SOK_BMS_04_Signatur 0;
BA_ "GenSigFuncType" SG_ 1450 SOK_BMS_04_Signatur 15;
BA_ "GenSigSwitchedByIgnition" SG_ 1450 SOK_BMS_04_Signatur 0;
BA_ "GenSigSendType" SG_ 1482 BMS_07_BZ 0;
BA_ "GenSigFuncType" SG_ 1482 BMS_07_BZ 1;
BA_ "GenSigSwitchedByIgnition" SG_ 1482 BMS_07_BZ 0;
BA_ "GenSigSendType" SG_ 1482 BMS_07_CRC 0;
BA_ "GenSigFuncType" SG_ 1482 BMS_07_CRC 2;
BA_ "GenSigSwitchedByIgnition" SG_ 1482 BMS_07_CRC 0;
BA_ "GenSigSendType" SG_ 1482 BMS_Ausgleichsladung_Anf 0;
BA_ "GenSigSwitchedByIgnition" SG_ 1482 BMS_Ausgleichsladung_Anf 0;
BA_ "GenSigSendType" SG_ 1482 BMS_Balancing_Aktiv 0;
BA_ "GenSigSwitchedByIgnition" SG_ 1482 BMS_Balancing_Aktiv 0;
BA_ "GenSigSendType" SG_ 1482 BMS_Batteriediagnose 3;
BA_ "GenSigStartValue" SG_ 1482 BMS_Batteriediagnose 1;
BA_ "GenSigSwitchedByIgnition" SG_ 1482 BMS_Batteriediagnose 0;
BA_ "Fehlerwert" SG_ 1482 BMS_Batteriediagnose 7;
BA_ "GenSigSendType" SG_ 1482 BMS_Energieinhalt 0;
BA_ "GenSigStartValue" SG_ 1482 BMS_Energieinhalt 2046;
BA_ "GenSigSwitchedByIgnition" SG_ 1482 BMS_Energieinhalt 0;
BA_ "Fehlerwert" SG_ 1482 BMS_Energieinhalt 2047;
BA_ "GenSigSendType" SG_ 1482 BMS_Gesamtst_Spgfreiheit 3;
BA_ "GenSigSwitchedByIgnition" SG_ 1482 BMS_Gesamtst_Spgfreiheit 0;
BA_ "GenSigSendType" SG_ 1482 BMS_KundenWarnung 3;
BA_ "GenSigSwitchedByIgnition" SG_ 1482 BMS_KundenWarnung 0;
BA_ "GenSigSendType" SG_ 1482 BMS_Ladevorgang_aktiv 0;
BA_ "GenSigSwitchedByIgnition" SG_ 1482 BMS_Ladevorgang_aktiv 0;
BA_ "GenSigSendType" SG_ 1482 BMS_MaxEnergieinhalt 0;
BA_ "GenSigStartValue" SG_ 1482 BMS_MaxEnergieinhalt 2046;
BA_ "GenSigSwitchedByIgnition" SG_ 1482 BMS_MaxEnergieinhalt 0;
BA_ "Fehlerwert" SG_ 1482 BMS_MaxEnergieinhalt 2047;
BA_ "GenSigSendType" SG_ 1482 BMS_RIso_Ext 0;
BA_ "GenSigStartValue" SG_ 1482 BMS_RIso_Ext 4094;
BA_ "GenSigSwitchedByIgnition" SG_ 1482 BMS_RIso_Ext 0;
BA_ "Fehlerwert" SG_ 1482 BMS_RIso_Ext 4095;
BA_ "GenSigSendType" SG_ 2527679654 BMS_11_BZ 0;
BA_ "GenSigFuncType" SG_ 2527679654 BMS_11_BZ 1;
BA_ "GenSigSwitchedByIgnition" SG_ 2527679654 BMS_11_BZ 0;
BA_ "GenSigSendType" SG_ 2527679654 BMS_11_CRC 0;
BA_ "GenSigFuncType" SG_ 2527679654 BMS_11_CRC 2;
BA_ "GenSigSwitchedByIgnition" SG_ 2527679654 BMS_11_CRC 0;
BA_ "GenSigSendType" SG_ 2527679654 BMS_IsoFehler 0;
BA_ "GenSigSwitchedByIgnition" SG_ 2527679654 BMS_IsoFehler 0;
BA_ "GenSigSendType" SG_ 2527679654 BMS_IsoZustand 0;
BA_ "GenSigSwitchedByIgnition" SG_ 2527679654 BMS_IsoZustand 0;
BA_ "GenSigSendType" SG_ 2527679654 BMS_IstTemperatur_hoechste 0;
BA_ "GenSigStartValue" SG_ 2527679654 BMS_IstTemperatur_hoechste 254;
BA_ "GenSigSwitchedByIgnition" SG_ 2527679654 BMS_IstTemperatur_hoechste 0;
BA_ "Fehlerwert" SG_ 2527679654 BMS_IstTemperatur_hoechste 255;
BA_ "GenSigSendType" SG_ 2527679654 BMS_IstTemperatur_niedrigste 0;
BA_ "GenSigStartValue" SG_ 2527679654 BMS_IstTemperatur_niedrigste 254;
BA_ "GenSigSwitchedByIgnition" SG_ 2527679654 BMS_IstTemperatur_niedrigste 0;
BA_ "Fehlerwert" SG_ 2527679654 BMS_IstTemperatur_niedrigste 255;
BA_ "GenSigSendType" SG_ 2527679654 BMS_IstZellspannung_hoechste 0;
BA_ "GenSigStartValue" SG_ 2527679654 BMS_IstZellspannung_hoechste 4094;
BA_ "GenSigSwitchedByIgnition" SG_ 2527679654 BMS_IstZellspannung_hoechste 0;
BA_ "Fehlerwert" SG_ 2527679654 BMS_IstZellspannung_hoechste 4095;
BA_ "GenSigSendType" SG_ 2527679654 BMS_IstZellspannung_niedrigste 0;
BA_ "GenSigStartValue" SG_ 2527679654 BMS_IstZellspannung_niedrigste 4094;
BA_ "GenSigSwitchedByIgnition" SG_ 2527679654 BMS_IstZellspannung_niedrigste 0;
BA_ "Fehlerwert" SG_ 2527679654 BMS_IstZellspannung_niedrigste 4095;
BA_ "GenSigSendType" SG_ 207 BMS_20_BZ 0;
BA_ "GenSigFuncType" SG_ 207 BMS_20_BZ 1;
BA_ "GenSigSwitchedByIgnition" SG_ 207 BMS_20_BZ 0;
BA_ "GenSigSendType" SG_ 207 BMS_20_CRC 0;
BA_ "GenSigFuncType" SG_ 207 BMS_20_CRC 2;
BA_ "GenSigSwitchedByIgnition" SG_ 207 BMS_20_CRC 0;
BA_ "GenSigSendType" SG_ 207 BMS_ErwGrenzen_aktiv 0;
BA_ "GenSigSwitchedByIgnition" SG_ 207 BMS_ErwGrenzen_aktiv 0;
BA_ "GenSigSendType" SG_ 207 BMS_Fehler_HVBattAbschaltung 0;
BA_ "GenSigSwitchedByIgnition" SG_ 207 BMS_Fehler_HVBattAbschaltung 0;
BA_ "GenSigSendType" SG_ 207 BMS_Fehler_HVBattAbschaltung_Anf 0;
BA_ "GenSigSwitchedByIgnition" SG_ 207 BMS_Fehler_HVBattAbschaltung_Anf 0;
BA_ "GenSigSendType" SG_ 207 BMS_Fehler_Leistungsred 0;
BA_ "GenSigSwitchedByIgnition" SG_ 207 BMS_Fehler_Leistungsred 0;
BA_ "GenSigSendType" SG_ 207 BMS_Fehler_Notabschaltung_Crash 0;
BA_ "GenSigSwitchedByIgnition" SG_ 207 BMS_Fehler_Notabschaltung_Crash 0;
BA_ "GenSigSendType" SG_ 207 BMS_Fehlerstatus_HV_Schuetze 0;
BA_ "GenSigSwitchedByIgnition" SG_ 207 BMS_Fehlerstatus_HV_Schuetze 0;
BA_ "GenSigSendType" SG_ 207 BMS_HVIL_Status 0;
BA_ "GenSigSwitchedByIgnition" SG_ 207 BMS_HVIL_Status 0;
BA_ "Fehlerwert" SG_ 207 BMS_HVIL_Status 3;
BA_ "GenSigSendType" SG_ 207 BMS_IstModus 0;
BA_ "GenSigStartValue" SG_ 207 BMS_IstModus 7;
BA_ "GenSigSwitchedByIgnition" SG_ 207 BMS_IstModus 0;
BA_ "GenSigSendType" SG_ 207 BMS_Spannung 0;
BA_ "GenSigStartValue" SG_ 207 BMS_Spannung 4094;
BA_ "GenSigSwitchedByIgnition" SG_ 207 BMS_Spannung 0;
BA_ "Fehlerwert" SG_ 207 BMS_Spannung 4095;
BA_ "GenSigSendType" SG_ 207 BMS_Spannung_Zwischenkreis 0;
BA_ "GenSigStartValue" SG_ 207 BMS_Spannung_Zwischenkreis 4094;
BA_ "GenSigSwitchedByIgnition" SG_ 207 BMS_Spannung_Zwischenkreis 0;
BA_ "Fehlerwert" SG_ 207 BMS_Spannung_Zwischenkreis 4095;
BA_ "GenSigSendType" SG_ 207 BMS_Strom 0;
BA_ "GenSigStartValue" SG_ 207 BMS_Strom 32766;
BA_ "GenSigSwitchedByIgnition" SG_ 207 BMS_Strom 0;
BA_ "Fehlerwert" SG_ 207 BMS_Strom 32767;
BA_ "GenSigSendType" SG_ 2463978704 BMS_Max_Entladeleistung 0;
BA_ "GenSigStartValue" SG_ 2463978704 BMS_Max_Entladeleistung 8190;
BA_ "GenSigSwitchedByIgnition" SG_ 2463978704 BMS_Max_Entladeleistung 0;
BA_ "GenSigSendType" SG_ 2463978704 BMS_Max_Entladestrom 3;
BA_ "GenSigStartValue" SG_ 2463978704 BMS_Max_Entladestrom 8190;
BA_ "GenSigSwitchedByIgnition" SG_ 2463978704 BMS_Max_Entladestrom 0;
BA_ "GenSigSendType" SG_ 2463978704 BMS_Max_Ladeleistung 0;
BA_ "GenSigStartValue" SG_ 2463978704 BMS_Max_Ladeleistung 8190;
BA_ "GenSigSwitchedByIgnition" SG_ 2463978704 BMS_Max_Ladeleistung 0;
BA_ "GenSigSendType" SG_ 2463978704 BMS_Max_Ladestrom 0;
BA_ "GenSigStartValue" SG_ 2463978704 BMS_Max_Ladestrom 8190;
BA_ "GenSigSwitchedByIgnition" SG_ 2463978704 BMS_Max_Ladestrom 0;
BA_REL_ "GenSigTimeoutTime" BU_SG_REL_ Gateway_Max SG_ 2536716545 BAP_RangeData_ASG_02_Header 800;
BA_REL_ "GenSigTimeoutTime" BU_SG_REL_ Getriebe_DQ SG_ 333 ACC_Sollbeschleunigung_02 500;
BA_REL_ "GenSigTimeoutTime" BU_SG_REL_ Getriebe_DQ SG_ 333 ACC_Anfahren 500;
BA_REL_ "GenSigTimeoutTime" BU_SG_REL_ Getriebe_DQ SG_ 333 ACC_Anhalten 500;
BA_REL_ "GenSigTimeoutTime" BU_SG_REL_ Getriebe_DQ SG_ 333 ACC_Status_ACC 500;
BA_REL_ "GenSigTimeoutTime" BU_SG_REL_ Getriebe_DQ SG_ 64 AB_Crash_Int 500;
BA_REL_ "GenSigTimeoutTime" BU_SG_REL_ Getriebe_DQ SG_ 1633 AAG_Anhaenger_erkannt 1000;
BA_REL_ "GenSigTimeoutTime" BU_SG_REL_ Getriebe_DQ SG_ 869 BEM_UBDM 500;
BA_REL_ "GenSigTimeoutTime" BU_SG_REL_ Getriebe_DQ SG_ 1163 BEM_06_CRC 1000;
BA_REL_ "GenSigTimeoutTime" BU_SG_REL_ Getriebe_DQ SG_ 1163 BEM_06_BZ 1000;
BA_REL_ "GenSigTimeoutTime" BU_SG_REL_ Getriebe_DQ SG_ 1163 NVEM_Energienetz_Status 1000;
BA_REL_ "GenSigTimeoutTime" BU_SG_REL_ Motor_konv SG_ 333 ACC_18_CRC 500;
BA_REL_ "GenSigTimeoutTime" BU_SG_REL_ Motor_konv SG_ 333 ACC_18_BZ 500;
BA_REL_ "GenSigTimeoutTime" BU_SG_REL_ Motor_konv SG_ 333 ACC_limitierte_Anfahrdyn 500;
BA_REL_ "GenSigTimeoutTime" BU_SG_REL_ Motor_konv SG_ 333 ACC_nachtr_Stopp_Anf 500;
BA_REL_ "GenSigTimeoutTime" BU_SG_REL_ Motor_konv SG_ 333 ACC_DynErhoehung 500;
BA_REL_ "GenSigTimeoutTime" BU_SG_REL_ Motor_konv SG_ 333 ACC_Freilaufstrategie_TSK 500;
BA_REL_ "GenSigTimeoutTime" BU_SG_REL_ Motor_konv SG_ 333 ACC_zul_Regelabw_unten 500;
BA_REL_ "GenSigTimeoutTime" BU_SG_REL_ Motor_konv SG_ 333 ACC_StartStopp_Info 500;
BA_REL_ "GenSigTimeoutTime" BU_SG_REL_ Motor_konv SG_ 333 ACC_Sollbeschleunigung_02 500;
BA_REL_ "GenSigTimeoutTime" BU_SG_REL_ Motor_konv SG_ 333 ACC_zul_Regelabw_oben 500;
BA_REL_ "GenSigTimeoutTime" BU_SG_REL_ Motor_konv SG_ 333 ACC_neg_Sollbeschl_Grad_02 500;
BA_REL_ "GenSigTimeoutTime" BU_SG_REL_ Motor_konv SG_ 333 ACC_pos_Sollbeschl_Grad_02 500;
BA_REL_ "GenSigTimeoutTime" BU_SG_REL_ Motor_konv SG_ 333 ACC_Anfahren 500;
BA_REL_ "GenSigTimeoutTime" BU_SG_REL_ Motor_konv SG_ 333 ACC_Anhalten 500;
BA_REL_ "GenSigTimeoutTime" BU_SG_REL_ Motor_konv SG_ 333 ACC_Typ 500;
BA_REL_ "GenSigTimeoutTime" BU_SG_REL_ Motor_konv SG_ 333 ACC_Status_ACC 500;
BA_REL_ "GenSigTimeoutTime" BU_SG_REL_ Motor_konv SG_ 333 ACC_Minimale_Bremsung 500;
BA_REL_ "GenSigTimeoutTime" BU_SG_REL_ Motor_konv SG_ 333 ACC_Folgebeschl 500;
BA_REL_ "GenSigTimeoutTime" BU_SG_REL_ Motor_konv SG_ 333 ACC_Freilauf_Info 500;
BA_REL_ "GenSigTimeoutTime" BU_SG_REL_ Motor_konv SG_ 333 ACC_FoD_Status 500;
BA_REL_ "GenSigTimeoutTime" BU_SG_REL_ Motor_konv SG_ 333 ACC_Blindheit_erkannt 500;
BA_REL_ "GenSigTimeoutTime" BU_SG_REL_ Motor_konv SG_ 333 ACC_relev_Nichtverfuegbarkeit 500;
BA_REL_ "GenSigTimeoutTime" BU_SG_REL_ Motor_konv SG_ 333 ACC_relevanter_Fehler 500;
BA_REL_ "GenSigTimeoutTime" BU_SG_REL_ Motor_konv SG_ 333 RDR_VBEG_Anforderung 500;
BA_REL_ "GenSigTimeoutTime" BU_SG_REL_ Motor_konv SG_ 333 MPPmod_1_Segment 500;
BA_REL_ "GenSigTimeoutTime" BU_SG_REL_ Motor_konv SG_ 333 MPPmod_2_Segment 500;
BA_REL_ "GenSigTimeoutTime" BU_SG_REL_ Motor_konv SG_ 333 MPPmod_3_Segment 500;
BA_REL_ "GenSigTimeoutTime" BU_SG_REL_ Motor_konv SG_ 333 MPPmod_4_Segment 500;
BA_REL_ "GenSigTimeoutTime" BU_SG_REL_ Motor_konv SG_ 859 ACC_Obj_01_ax_StdA 800;
BA_REL_ "GenSigTimeoutTime" BU_SG_REL_ Motor_konv SG_ 859 ACC_Obj_01_ax_v 800;
BA_REL_ "GenSigTimeoutTime" BU_SG_REL_ Motor_konv SG_ 859 ACC_Obj_01_dx_v 800;
BA_REL_ "GenSigTimeoutTime" BU_SG_REL_ Motor_konv SG_ 859 ACC_Obj_01_dy_StdA 800;
BA_REL_ "GenSigTimeoutTime" BU_SG_REL_ Motor_konv SG_ 859 ACC_Obj_01_dy_v 800;
BA_REL_ "GenSigTimeoutTime" BU_SG_REL_ Motor_konv SG_ 859 ACC_Obj_01_vx_v 800;
BA_REL_ "GenSigTimeoutTime" BU_SG_REL_ Motor_konv SG_ 860 ACC_Obj_04_dx_v 800;
BA_REL_ "GenSigTimeoutTime" BU_SG_REL_ Motor_konv SG_ 860 ACC_Obj_04_vx_v 800;
BA_REL_ "GenSigTimeoutTime" BU_SG_REL_ Motor_konv SG_ 64 Airbag_01_CRC 500;
BA_REL_ "GenSigTimeoutTime" BU_SG_REL_ Motor_konv SG_ 64 Airbag_01_BZ 500;
BA_REL_ "GenSigTimeoutTime" BU_SG_REL_ Motor_konv SG_ 64 AB_Crash_Int 500;
BA_REL_ "GenSigTimeoutTime" BU_SG_REL_ Motor_konv SG_ 64 AB_Stellgliedtest 500;
BA_REL_ "GenSigTimeoutTime" BU_SG_REL_ Motor_konv SG_ 64 AB_Gurtschloss_FA_ext 500;
BA_REL_ "GenSigTimeoutTime" BU_SG_REL_ Motor_konv SG_ 1312 Airbag_02_CRC 2000;
BA_REL_ "GenSigTimeoutTime" BU_SG_REL_ Motor_konv SG_ 1312 Airbag_02_BZ 2000;
BA_REL_ "GenSigTimeoutTime" BU_SG_REL_ Motor_konv SG_ 1312 AB_Gurtschloss_FA 2000;
BA_REL_ "GenSigTimeoutTime" BU_SG_REL_ Motor_konv SG_ 1349 Airbag_04_CRC 2000;
BA_REL_ "GenSigTimeoutTime" BU_SG_REL_ Motor_konv SG_ 1349 Airbag_04_BZ 2000;
BA_REL_ "GenSigTimeoutTime" BU_SG_REL_ Motor_konv SG_ 1349 AB_Belegung_VF_ext 2000;
BA_REL_ "GenSigTimeoutTime" BU_SG_REL_ Motor_konv SG_ 1633 AAG_Bremsl_durch_ECD 1000;
BA_REL_ "GenSigTimeoutTime" BU_SG_REL_ Motor_konv SG_ 1633 AAG_Anhaenger_erkannt 1000;
BA_REL_ "GenSigTimeoutTime" BU_SG_REL_ Motor_konv SG_ 1633 AAG_Bremslicht_H_def 1000;
BA_REL_ "GenSigTimeoutTime" BU_SG_REL_ Motor_konv SG_ 345 ARA_Status 1000;
BA_REL_ "GenSigTimeoutTime" BU_SG_REL_ Motor_konv SG_ 2536717312 BAP_EfficAssist_ASG_01_Header 800;
BA_REL_ "GenSigTimeoutTime" BU_SG_REL_ Motor_konv SG_ 2536717313 BAP_EfficAssist_ASG_02_Header 800;
BA_REL_ "GenSigTimeoutTime" BU_SG_REL_ Motor_konv SG_ 2536725760 BAP_EngFunctions_ASG_01_Header 800;
BA_REL_ "GenSigTimeoutTime" BU_SG_REL_ Motor_konv SG_ 1626 BCM_Kuehlmittel_Sensor 5000;
BA_REL_ "GenSigTimeoutTime" BU_SG_REL_ Motor_konv SG_ 1626 BCM_Offroad_Taste 5000;
BA_REL_ "GenSigTimeoutTime" BU_SG_REL_ Motor_konv SG_ 1626 BCM_Hybrid_StartStopp_Taste 5000;
BA_REL_ "GenSigTimeoutTime" BU_SG_REL_ Motor_konv SG_ 1626 BCM1_Rueckfahrlicht_Schalter 5000;
BA_REL_ "GenSigTimeoutTime" BU_SG_REL_ Motor_konv SG_ 1626 BCM1_MH_Schalter 5000;
BA_REL_ "GenSigTimeoutTime" BU_SG_REL_ Motor_konv SG_ 1626 BCM1_MH_WIV_Schalter 5000;
BA_REL_ "GenSigTimeoutTime" BU_SG_REL_ Motor_konv SG_ 869 BEM_P_Generator 500;
BA_REL_ "GenSigTimeoutTime" BU_SG_REL_ Motor_konv SG_ 869 BEM_n_LLA 500;
BA_REL_ "GenSigTimeoutTime" BU_SG_REL_ Motor_konv SG_ 869 NVEM_Abschaltstufe 500;
BA_REL_ "GenSigTimeoutTime" BU_SG_REL_ Motor_konv SG_ 869 BEM_Anf_KL 500;
BA_REL_ "GenSigTimeoutTime" BU_SG_REL_ Motor_konv SG_ 869 BEM_StartStopp_Info 500;
BA_REL_ "GenSigTimeoutTime" BU_SG_REL_ Motor_konv SG_ 869 BEM_DFM 500;
BA_REL_ "GenSigTimeoutTime" BU_SG_REL_ Motor_konv SG_ 869 BEM_EMLIN_ungueltig 500;
BA_REL_ "GenSigTimeoutTime" BU_SG_REL_ Motor_konv SG_ 869 BEM_Batt_Ab 500;
BA_REL_ "GenSigTimeoutTime" BU_SG_REL_ Motor_konv SG_ 869 NVEM_Freilauf_Info 500;
BA_REL_ "GenSigTimeoutTime" BU_SG_REL_ Motor_konv SG_ 869 NVEM_Red_KL 500;
BA_REL_ "GenSigTimeoutTime" BU_SG_REL_ Motor_konv SG_ 2463978850 NVEM2_VerbrZustandsAnf 1000;
VAL_ 333 ACC_limitierte_Anfahrdyn 0 "keine_Limitierung" 1 "Limitierung_Anfahrdynamik_angefordert" ;
VAL_ 333 ACC_nachtr_Stopp_Anf 0 "nicht_angefordert" 1 "angefordert" ;
VAL_ 333 ACC_DynErhoehung 0 "normale_Verzoegerungsdynamik" 1 "erhoehte_Verzoegerungsdynamik" ;
VAL_ 333 ACC_Freilaufstrategie_TSK 0 "Freilaufstr_nicht_angefordert" 1 "Freilaufstr_angefordert" ;
VAL_ 333 ACC_StartStopp_Info 0 "Motorlauf_langfristig_nicht_notwendig_Stoppfreigabe" 1 "Motoranlauf_nicht_zwingend_notwendig_Stoppverbot_keine_Startanforderung" 2 "Motoranlauf_zwingend_notwendig_Startanforderung" 3 "Systemfehler" ;
VAL_ 333 ACC_Sollbeschleunigung_02 2046 "Neutralwert" 2047 "Fehler" ;
VAL_ 333 ACC_Anfahren 0 "keine_Anforderung_Anfahren" 1 "Anforderung_Anfahren" ;
VAL_ 333 ACC_Anhalten 0 "kein_Anhalten_gewuenscht" 1 "Anhalten_gewuenscht" ;
VAL_ 333 ACC_Typ 0 "Basis_ACC" 1 "ACC_mit_FollowToStop" 2 "ACC_mit_StopAndGo" 3 "ACC_nicht_codiert" ;
VAL_ 333 ACC_Status_ACC 0 "ACC_OFF_Hauptschalter_aus" 1 "ACC_INIT" 2 "ACC_STANDBY" 3 "ACC_AKTIV_regelt" 4 "ACC_OVERRIDE" 5 "ACC_Abschaltreaktion" 6 "reversibler_Fehler_im_ACC_System" 7 "irreversibler_Fehler_im_ACC_System" ;
VAL_ 333 ACC_Minimale_Bremsung 0 "Anforderung_Minimale_Bremsung_nicht_aktiv" 1 "Anforderung_Minimale_Bremsung_aktiv" ;
VAL_ 333 ACC_Anhalteweg 2046 "Neutralwert" 2047 "Fehler" ;
VAL_ 333 ACC_Boost 0 "Boost_nicht_aktiv" 1 "Boost_aktiv" ;
VAL_ 333 ACC_Freilauf_Anf 0 "keine Freilauf-Anforderung" 1 "Freilauf-Anforderung" ;
VAL_ 333 ACC_Anforderung_HMS 0 "keine_Anforderung" 1 "halten" 2 "parken" 3 "halten_Standby" 4 "anfahren" 5 "Loesen_ueber_Rampe" 7 "HMS_uebernehmen" ;
VAL_ 333 ACC_Folgebeschl 254 "Neutralwert" ;
VAL_ 333 ACC_Freilauf_Info 0 "Freilauf_freigegeben" 1 "Weiches_Veto_uebertippbar" 2 "Hartes_Veto_Abbruch" 3 "Freilauf_Anforderung" ;
VAL_ 333 ACC_Tempolimitassistent_Ein 0 "Tempolimitassistent_aus" 1 "Tempolimitassistent_ein" ;
VAL_ 333 ACC_FoD_Status 0 "Init" 1 "Funktion_inaktiv" 2 "Funktion_aktiv" ;
VAL_ 333 ACC_Blindheit_erkannt 0 "keine_Blindheit_erkannt" 1 "Blindheit_erkannt" ;
VAL_ 333 ACC_Verkehrssinn 0 "Init" 1 "Linksverkehr" 2 "Rechtsverkehr" 3 "Unbekannt" ;
VAL_ 333 ACC_relev_Nichtverfuegbarkeit 0 "verfuegbar" 1 "nicht_verfuegbar" ;
VAL_ 333 ACC_relevanter_Fehler 0 "kein_relevanter_Fehler" 1 "relevanter_Fehler" ;
VAL_ 333 ACC_TA_Kurve_Abstand 61 "groesser_300m" 62 "Init_keine_Kurvenanpassung" ;
VAL_ 333 ACC_TA_Kurve_vDelta 11 "Init_keine_Kurvenanpassung" ;
VAL_ 333 RDR_VBEG_Anforderung 0 "INIT" ;
VAL_ 333 ACC_Abbiegewunsch 0 "Init_kein_Abbiegewunsch" 1 "Abbiegewunsch_rechts" 2 "Abbiegewunsch_links" ;
VAL_ 333 ACC_Abbiegewunsch_Abstand 511 "Kein_Abbiegewunsch" ;
VAL_ 333 MPPmod_1_Segment 0 "Keine_Modifikation" 1 "Reset" ;
VAL_ 333 MPPmod_2_Segment 0 "Keine_Modifikation" 1 "Reset" ;
VAL_ 333 MPPmod_3_Segment 0 "Keine_Modifikation" 1 "Reset" ;
VAL_ 333 MPPmod_4_Segment 0 "Keine_Modifikation" 1 "Reset" ;
VAL_ 333 vESC_Verz_Anf 8 "Neutralwert" 9 "Init" 10 "Fehler" ;
VAL_ 333 RDR_v_ueber_Grund 4091 "Init" 4092 "temporaer_nicht_verfuegbar" 4093 "Fehler" ;
VAL_ 333 RDR_v_ueber_Grund_Genauigkeit 61 "groesser_6km_h" 62 "Init" 63 "Fehler" ;
VAL_ 333 RDR_v_ueber_Grund_Fahrtrichtung 0 "vorwaerts" 1 "rueckwaerts" 2 "init_unbekannt" ;
VAL_ 859 ACC_Obj_01_ID 0 "kein_Objekt_enthalten" 255 "Init" ;
VAL_ 859 ACC_Obj_01_ax_StdA 63 "Init" ;
VAL_ 859 ACC_Obj_01_ax_v 255 "Init" ;
VAL_ 859 ACC_Obj_01_dx_StdA 127 "Init" ;
VAL_ 859 ACC_Obj_01_dx_v 4095 "Init" ;
VAL_ 859 ACC_Obj_01_dy_StdA 127 "Init" ;
VAL_ 859 ACC_Obj_01_dy_v 2047 "Init" ;
VAL_ 859 ACC_Obj_01_vx_StdA 31 "Init" ;
VAL_ 859 ACC_Obj_01_vx_v 1023 "Init" ;
VAL_ 859 ACC_Obj_01_Bew_Zustand 0 "Init" 1 "fahrend" 2 "angehalten" 3 "stehend" ;
VAL_ 859 ACC_Obj_01_Fusion_ID_VD 0 "kein_Objekt_fusioniert" 0 "Init" ;
VAL_ 859 ACC_Obj_01_Fusion_ID_FER_VR 0 "kein_Objekt_fusioniert" 255 "Init" ;
VAL_ 859 ACC_Obj_01_Fusion_ID_FER_VL 0 "kein_Objekt_fusioniert" 255 "Init" ;
VAL_ 859 ACC_Obj_01_Alter 4095 "Init" ;
VAL_ 859 ACC_Obj_01_vxAbs_v 4095 "Init" ;
VAL_ 859 ACC_Obj_01_vyAbs_v 4095 "Init" ;
VAL_ 859 ACC_Obj_01_Bezugspunkt 0 "unbestimmt" 1 "vorne_links" 2 "vorne_Mitte" 3 "vorne_rechts" 4 "rechts_Mitte" 5 "hinten_rechts" 6 "hinten_Mitte" 7 "hinten_links" 8 "links_Mitte" 9 "Objektmitte" 15 "Init" ;
VAL_ 859 ACC_Obj_01_Breite 127 "Init" ;
VAL_ 859 ACC_Obj_01_SDFInfo_FER_VL 0 "nicht_bestaetigt" 1 "bestaetigt" ;
VAL_ 859 ACC_Obj_01_BreiteStdA 127 "Init" ;
VAL_ 859 ACC_Obj_01_SDFInfo_FER_VR 0 "nicht_bestaetigt" 1 "bestaetigt" ;
VAL_ 859 ACC_Obj_01_Historie 0 "Erstmalige_Ausgabe_auf_dem_Bus" 1 "Obj_wurde_bereits_ausgegeben" ;
VAL_ 859 ACC_Obj_01_SDFInfo_FR 0 "nicht_bestaetigt" 1 "bestaetigt" ;
VAL_ 859 ACC_Obj_01_SDFInfo_Kamera 0 "nicht_bestaetigt" 1 "bestaetigt" ;
VAL_ 859 ACC_Obj_01_vy_StdA 31 "Init" ;
VAL_ 859 ACC_Obj_01_dz_v 511 "Init" ;
VAL_ 859 ACC_Obj_01_dz_StdA 127 "Init" ;
VAL_ 859 ACC_Obj_01_Laenge 511 "Init" ;
VAL_ 859 ACC_Obj_01_LaengeStdA 127 "Init" ;
VAL_ 859 ACC_Obj_01_GierWnkl 511 "Init" ;
VAL_ 859 ACC_Obj_01_ExistenzMass 127 "Init" ;
VAL_ 859 ACC_Obj_01_axAbs_v 255 "Init" ;
VAL_ 859 ACC_Obj_01_ay_v 255 "Init" ;
VAL_ 859 ACC_Obj_01_vy_v 255 "Init" ;
VAL_ 859 ACC_Obj_01_Klasse 0 "unbekannt" 1 "ueberfahrbar" 2 "unterfahrbar" 3 "Fussgaenger" 4 "Fussgaengergruppe" 5 "Fahrrad" 6 "Motorrad" 7 "PKW" 8 "Van" 9 "LKW" 10 "Randbebauung" 11 "Tier" 12 "Retroreflektor" 15 "Init" ;
VAL_ 859 ACC_Obj_01_KlassePlausib 15 "Init" ;
VAL_ 859 ACC_Obj_01_Gemessen 0 "Objekt_praediziert" 1 "Objekt_gemessen" 2 "Objekt_per_Feature_Tracking" 3 "Naheinscherer_oder_Ueberholer" ;
VAL_ 859 ACC_Obj_01_Hoehe 63 "Init" ;
VAL_ 859 ACC_Obj_01_HoeheStdA 63 "Init" ;
VAL_ 859 ACC_Obj_01_vxAbs_StdA 63 "Init" ;
VAL_ 859 ACC_Obj_01_vyAbs_StdA 63 "Init" ;
VAL_ 859 ACC_Obj_01_axAbs_StdA 63 "Init" ;
VAL_ 859 ACC_Obj_01_ay_StdA 63 "Init" ;
VAL_ 859 ACC_Obj_01_GierWnklStdA 63 "Init" ;
VAL_ 859 ACC_Obj_01_Anzeige_Rel 0 "Keine_Anzeige" 1 "passive_Darstellung" 2 "geregelte_Darstellung" 3 "bewarnte_Darstellung" ;
VAL_ 859 ACC_Obj_01_LaengsRegelung 0 "Objektregelung_inaktiv" 1 "Objektregelung_aktiv" ;
VAL_ 860 ACC_Obj_04_ID 0 "kein_Objekt_enthalten" 255 "Init" ;
VAL_ 860 ACC_Obj_04_ax_StdA 63 "Init" ;
VAL_ 860 ACC_Obj_04_ax_v 255 "Init" ;
VAL_ 860 ACC_Obj_04_dx_StdA 127 "Init" ;
VAL_ 860 ACC_Obj_04_dx_v 4095 "Init" ;
VAL_ 860 ACC_Obj_04_dy_StdA 127 "Init" ;
VAL_ 860 ACC_Obj_04_dy_v 2047 "Init" ;
VAL_ 860 ACC_Obj_04_vx_StdA 31 "Init" ;
VAL_ 860 ACC_Obj_04_vx_v 1023 "Init" ;
VAL_ 860 ACC_Obj_04_Bew_Zustand 0 "Init" 1 "fahrend" 2 "angehalten" 3 "stehend" ;
VAL_ 860 ACC_Obj_04_Fusion_ID_VD 0 "kein_Objekt_fusioniert" 0 "Init" ;
VAL_ 860 ACC_Obj_04_Fusion_ID_FER_VR 0 "kein_Objekt_fusioniert" 255 "Init" ;
VAL_ 860 ACC_Obj_04_Fusion_ID_FER_VL 0 "kein_Objekt_fusioniert" 255 "Init" ;
VAL_ 860 ACC_Obj_04_Alter 4095 "Init" ;
VAL_ 860 ACC_Obj_04_vxAbs_v 4095 "init" ;
VAL_ 860 ACC_Obj_04_vyAbs_v 4095 "Init" ;
VAL_ 860 ACC_Obj_04_Bezugspunkt 0 "unbestimmt" 1 "vorne_links" 2 "vorne_Mitte" 3 "vorne_rechts" 4 "rechts_Mitte" 5 "hinten_rechts" 6 "hinten_Mitte" 7 "hinten_links" 8 "links_Mitte" 9 "Objektmitte" 15 "Init" ;
VAL_ 860 ACC_Obj_04_Breite 127 "Init" ;
VAL_ 860 ACC_Obj_04_SDFInfo_FER_VL 0 "nicht_bestaetigt" 1 "bestaetigt" ;
VAL_ 860 ACC_Obj_04_BreiteStdA 127 "Init" ;
VAL_ 860 ACC_Obj_04_SDFInfo_FER_VR 0 "nicht_bestaetigt" 1 "bestaetigt" ;
VAL_ 860 ACC_Obj_04_Historie 0 "Erstmalige_Ausgabe_auf_dem_Bus" 1 "Obj_wurde_bereits_ausgegeben" ;
VAL_ 860 ACC_Obj_04_SDFInfo_FR 0 "nicht_bestaetigt" 1 "bestaetigt" ;
VAL_ 860 ACC_Obj_04_SDFInfo_Kamera 0 "nicht_bestaetigt" 1 "bestaetigt" ;
VAL_ 860 ACC_Obj_04_vy_StdA 31 "Init" ;
VAL_ 860 ACC_Obj_04_dz_v 511 "Init" ;
VAL_ 860 ACC_Obj_04_dz_StdA 127 "Init" ;
VAL_ 860 ACC_Obj_04_Laenge 511 "Init" ;
VAL_ 860 ACC_Obj_04_LaengeStdA 127 "Init" ;
VAL_ 860 ACC_Obj_04_GierWnkl 511 "Init" ;
VAL_ 860 ACC_Obj_04_ExistenzMass 127 "Init" ;
VAL_ 860 ACC_Obj_04_axAbs_v 255 "Init" ;
VAL_ 860 ACC_Obj_04_ay_v 255 "Init" ;
VAL_ 860 ACC_Obj_04_vy_v 255 "Init" ;
VAL_ 860 ACC_Obj_04_Klasse 0 "unbekannt" 1 "ueberfahrbar" 2 "unterfahrbar" 3 "Fussgaenger" 4 "Fussgaengergruppe" 5 "Fahrrad" 6 "Motorrad" 7 "PKW" 8 "Van" 9 "LKW" 10 "Randbebauung" 11 "Tier" 12 "Retroreflektor" 15 "Init" ;
VAL_ 860 ACC_Obj_04_KlassePlausib 15 "Init" ;
VAL_ 860 ACC_Obj_04_Gemessen 0 "Objekt_praediziert" 1 "Objekt_gemessen" 2 "Objekt_per_Feature_Tracking" 3 "Naheinscherer_oder_Ueberholer" ;
VAL_ 860 ACC_Obj_04_Hoehe 63 "Init" ;
VAL_ 860 ACC_Obj_04_HoeheStdA 63 "Init" ;
VAL_ 860 ACC_Obj_04_vxAbs_StdA 63 "init" ;
VAL_ 860 ACC_Obj_04_vyAbs_StdA 63 "init" ;
VAL_ 860 ACC_Obj_04_axAbs_StdA 63 "Init" ;
VAL_ 860 ACC_Obj_04_ay_StdA 63 "Init" ;
VAL_ 860 ACC_Obj_04_GierWnklStdA 63 "Init" ;
VAL_ 860 ACC_Obj_04_Anzeige_Rel 0 "Keine_Anzeige" 1 "passive_Darstellung" 2 "geregelte_Darstellung" 3 "bewarnte_Darstellung" ;
VAL_ 860 ACC_Obj_04_LaengsRegelung 0 "Objektregelung_inaktiv" 1 "Objektregelung_aktiv" ;
VAL_ 1660 AGA_Texte 0 "keine_Anzeige" 1 "Aussensound_defekt" 2 "Aussensound_deaktiviert" 3 "Aussensound_deaktiviert_reduziertWarn" 4 "Aussensound_aktiviert" 5 "Aussensound_deaktiviert_KL15" ;
VAL_ 1660 E_Sound_verbaut 0 "nicht_verbaut" 1 "verbaut" ;
VAL_ 1660 AGA_Charisma_FahrPr 0 "keine_Funktion" 1 "Programm_1" 2 "Programm_2" 3 "Programm_3" 4 "Programm_4" 5 "Programm_5" 6 "Programm_6" 7 "Programm_7" 8 "Programm_8" 9 "Programm_9" 10 "Programm_10" 11 "Programm_11" 12 "Programm_12" 13 "Programm_13" 14 "Programm_14" 15 "Programm_15" ;
VAL_ 1660 AGA_Charisma_Status 0 "Init" 1 "verfuegbar" 2 "nicht_verfuegbar" 3 "asynchron_durch_Fahrerwunsch" ;
VAL_ 1660 AGA_ohne_Funktion 0 "kein_Fehler" 1 "Fehler" ;
VAL_ 1660 AGA_Verstaerker_Mute 0 "Mute" 1 "Kein_Mute" ;
VAL_ 64 AB_RGS_Anst 4 "aktiv_Niveau_1" 5 "aktiv_Niveau_2" 6 "aktiv_Niveau_3" 7 "aktiv_Niveau_4" 8 "deaktiviert" ;
VAL_ 64 AB_Front_Crash 0 "kein_Front_Crash" 1 "Front_Crash" ;
VAL_ 64 AB_Heck_Crash 0 "kein_Heck_Crash" 1 "Heck_Crash" ;
VAL_ 64 AB_SF_Crash 0 "kein_Seiten_Crash_Fahrer" 1 "Seiten_Crash_Fahrer" ;
VAL_ 64 AB_SB_Crash 0 "kein_Seiten_Crash_Beifahrer" 1 "Seiten_Crash_Beifahrer" ;
VAL_ 64 AB_Rollover_Crash 0 "kein_Rollover" 1 "Rollover" ;
VAL_ 64 AB_Crash_Int 0 "kein_Crash" 1 "Crash_Intensitaet_1" 2 "Crash_Intensitaet_2_(nur_Stellgliedtest_MLB_B8)" 3 "Crash_Intensitaet_2_(nur_D4_C7_Colorado_NF_PAG__Crash_im_MLB_B8)" 4 "Crash_Intensitaet_3_(alt_VW/AUDI__Stellgliedtest_MLB_B8)" 5 "Crash_Intensitaet_3_(alt_PAG)" 7 "Crash_Intensitaet_3" ;
VAL_ 64 AB_Lampe 0 "Aus" 1 "Ein" ;
VAL_ 64 AB_Deaktiviert 0 "aktiv" 1 "deaktiviert" ;
VAL_ 64 AB_VB_deaktiviert 0 "Beifahrerairbag_aktiv" 1 "Beifahrerairbag_deaktiviert" ;
VAL_ 64 AB_Systemfehler 0 "kein_Fehler" 1 "Airbag_Systemfehler" ;
VAL_ 64 AB_Diagnose 0 "nicht_in_Diagnose" 1 "in_Diagnose" ;
VAL_ 64 AB_Stellgliedtest 0 "nicht_im_Stellgliedtest" 1 "Airbag_im_Stellgliedtest" ;
VAL_ 64 AB_Erh_Auf_VB 0 "keine_Anzeige" 1 "Beifahrerairbag_deaktiviert" 2 "Beifahrerairbag_aktiviert" 3 "nicht_definiert" ;
VAL_ 64 AB_Gurtwarn_VF 0 "keine_Warnung" 1 "Gurtwarnung_ausloesen" ;
VAL_ 64 AB_Gurtwarn_VB 0 "keine_Warnung" 1 "Gurtwarnung_ausloesen" ;
VAL_ 64 AB_Anzeige_Fussg 0 "keine_FSG_Aktion_ausgeloest" 1 "Motorhaube_offen" 2 "Systemfehler" ;
VAL_ 64 AB_Texte_AKS 0 "keine_AKS_Ausloesung" 1 "AKS_ausgeloest" 2 "AKS_Systemfehler" ;
VAL_ 64 AB_PAO_Leuchte_Anf 0 "Leuchte_ausschalten" 1 "Leuchte_einschalten" ;
VAL_ 64 AB_MKB_gueltig 0 "Multikollisionsbremsung_nicht_freigeschaltet" 1 "Multikollisionsbremsung_freigeschaltet" ;
VAL_ 64 AB_MKB_Anforderung 0 "Multikollisionsbremsung_nicht_angefordert" 1 "Multikollisionsbremsung_angefordert" ;
VAL_ 64 AB_Versorgungsspannung 0 "plausibel" 1 "unplausibel" ;
VAL_ 64 AB_Deaktivierung_HV 0 "keine_Deaktivierung" 1 "Deaktivierung_1" 2 "Deaktivierung_2" 3 "Deaktivierung_3" 4 "Deaktivierung_4" 5 "Deaktivierung_5" 6 "Deaktivierung_6" 7 "Fehler" ;
VAL_ 64 AB_EDR_Trigger 0 "No_Event" 1 "Start_Event" 2 "NonDeployment_Event" 3 "Deployment_Event" ;
VAL_ 64 AB_Belegung_VF 0 "nicht_verfuegbar" 1 "Fehler" 2 "nicht_belegt" 3 "belegt" ;
VAL_ 64 AB_Gurtschloss_FA_ext 0 "nicht_verbaut" 1 "reserviert" 2 "nicht_gesteckt" 3 "gesteckt" 4 "dauerhaft_nicht_gesteckt" 5 "dauerhaft_gesteckt" 6 "Init" 7 "Fehler" ;
VAL_ 64 AB_Gurtschloss_FA_ext_aktiv 0 "inaktiv" 1 "aktiv" ;
VAL_ 64 AB_eCS_Error 0 "keine_Anzeige" 1 "Anzeige_anfordern" ;
VAL_ 64 ASM_Masterzeit_02 255 "Init" ;
VAL_ 1312 LoGeWa_Event_Kombiwarnung 0 "Init" 1 "Unfall" 2 "Traktionsverlust" 3 "Panne" 4 "Sichtbehinderung" 5 "Aquaplaning" ;
VAL_ 1312 AB_Anforderung_eCall 0 "keine_Anforderung" 1 "Anforderung" ;
VAL_ 1312 AB_Anprall_Seite_Beifahrer 0 "kein_Anprall" 1 "Anprall_erkannt" ;
VAL_ 1312 AB_Anprall_Rollover 0 "kein_Anprall" 1 "Anprall_erkannt" ;
VAL_ 1312 AB_Anprall_FGS 0 "kein_Anprall" 1 "Anprall_erkannt" ;
VAL_ 1312 AB_Anprall_Front_Beifahrer 0 "kein_Anprall" 1 "Anprall_erkannt" ;
VAL_ 1312 AB_Anprall_Front_Fahrer 0 "kein_Anprall" 1 "Anprall_erkannt" ;
VAL_ 1312 AB_Anprall_Heck_Beifahrer 0 "kein_Anprall" 1 "Anprall_erkannt" ;
VAL_ 1312 AB_Anprall_Heck_Fahrer 0 "kein_Anprall" 1 "Anprall_erkannt" ;
VAL_ 1312 AB_Wickelklappung_Reihe2_MI 0 "nicht_verbaut" 1 "nicht_verfuegbar__Fehler_oder_Init" 2 "nicht_verriegelt" 3 "verriegelt" ;
VAL_ 1312 AB_Belegung_VB 0 "nicht_verfuegbar" 1 "Fehler" 2 "nicht_belegt" 3 "belegt" ;
VAL_ 1312 AB_Abschaltanf_SIH_BF 0 "Normalbetrieb" 1 "Abschaltung_angefordert" ;
VAL_ 1312 AB_Anprall_Seite_Fahrer 0 "kein_Anprall" 1 "Anprall_erkannt" ;
VAL_ 1312 SC_PAO_Schriftzug_Anf 0 "LED aus" 1 "LED an" 2 "LED blinken" 3 "reserviert" ;
VAL_ 1312 SC_PAO_ON_Anf 0 "LED aus" 1 "LED an" 2 "LED blinken" 3 "reserviert" ;
VAL_ 1312 SC_PAO_OFF_Anf 0 "LED aus" 1 "LED an" 2 "LED blinken" 3 "reserviert" ;
VAL_ 1312 AB_Crashschwere 0 "kein_Ereignis" 1 "Crashschwere_1" 2 "Crashschwere_2" 3 "Crashschwere_3" 4 "Crashschwere_4" 5 "Crashschwere_5" 6 "Crashschwere_2_bis_5" 7 "Fehler" ;
VAL_ 1312 AB_Anforderung_USM 0 "keine_Anforderung" 1 "Anforderung" ;
VAL_ 1312 AB_Gurtschloss_FA 0 "nicht_verbaut" 1 "nicht_verfügbar (Fehler oder Init)" 2 "nicht_gesteckt" 3 "gesteckt" ;
VAL_ 1312 AB_Gurtschloss_BF 0 "nicht_verbaut" 1 "nicht_verfügbar (Fehler oder Init)" 2 "nicht_gesteckt" 3 "gesteckt" ;
VAL_ 1312 AB_Gurtschloss_Reihe2_FA 0 "nicht_verbaut" 1 "nicht_verfügbar (Fehler oder Init)" 2 "nicht_gesteckt" 3 "gesteckt" ;
VAL_ 1312 AB_Gurtschloss_Reihe2_MI 0 "nicht_verbaut" 1 "nicht_verfügbar (Fehler oder Init)" 2 "nicht_gesteckt" 3 "gesteckt" ;
VAL_ 1312 AB_Gurtschloss_Reihe2_BF 0 "nicht_verbaut" 1 "nicht_verfügbar (Fehler oder Init)" 2 "nicht_gesteckt" 3 "gesteckt" ;
VAL_ 1312 AB_Gurtschloss_Reihe3_FA 0 "nicht_verbaut" 1 "nicht_verfügbar (Fehler oder Init)" 2 "nicht_gesteckt" 3 "gesteckt" ;
VAL_ 1312 AB_Gurtschloss_Reihe3_MI 0 "nicht_verbaut" 1 "nicht_verfügbar (Fehler oder Init)" 2 "nicht_gesteckt" 3 "gesteckt" ;
VAL_ 1312 AB_Gurtschloss_Reihe3_BF 0 "nicht_verbaut" 1 "nicht_verfügbar (Fehler oder Init)" 2 "nicht_gesteckt" 3 "gesteckt" ;
VAL_ 1312 AB_Sitzpos_Sens_FA 0 "nicht verfügbar" 1 "Fehler" 2 "Sitz nicht vorne" 3 "Sitz vorne" ;
VAL_ 1312 AB_Sitzpos_Sens_BF 0 "nicht verfügbar" 1 "Fehler" 2 "Sitz nicht vorne" 3 "Sitz vorne" ;
VAL_ 1312 AB_Wickelklappung_Reihe2_BF 0 "nicht_verbaut" 1 "nicht_verfuegbar__Fehler_oder_Init" 2 "nicht_verriegelt" 3 "verriegelt" ;
VAL_ 1312 AB_Wickelklappung_Reihe2_FA 0 "nicht_verbaut" 1 "nicht_verfuegbar__Fehler_oder_Init" 2 "nicht_verriegelt" 3 "verriegelt" ;
VAL_ 1349 AB_Anprall_Front 0 "kein_Anprall" 1 "Anprall_erkannt" ;
VAL_ 1349 AB_Anprall_Heck 0 "kein_Anprall" 1 "Anprall_erkannt" ;
VAL_ 1349 AB_Gurtwarn_Reihe4_FA 0 "nicht_verbaut" 1 "keine_Gurtwarnung_Sitz_leer" 2 "keine_Gurtwarnung_Sitz_belegt" 3 "Gurtwarnung_Sitz_belegt" ;
VAL_ 1349 AB_Gurtwarn_Reihe4_BF 0 "nicht_verbaut" 1 "keine_Gurtwarnung_Sitz_leer" 2 "keine_Gurtwarnung_Sitz_belegt" 3 "Gurtwarnung_Sitz_belegt" ;
VAL_ 1349 AB_Gurtwarn_Reihe4_MI 0 "nicht_verbaut" 1 "keine_Gurtwarnung_Sitz_leer" 2 "keine_Gurtwarnung_Sitz_belegt" 3 "Gurtwarnung_Sitz_belegt" ;
VAL_ 1349 AB_Gurtwarn_Reihe2_FA 0 "nicht_verbaut" 1 "keine_Gurtwarnung_Sitz_leer" 2 "keine_Gurtwarnung_Sitz_belegt" 3 "Gurtwarnung_Sitz_belegt" ;
VAL_ 1349 AB_Gurtwarn_Reihe2_BF 0 "nicht_verbaut" 1 "keine_Gurtwarnung_Sitz_leer" 2 "keine_Gurtwarnung_Sitz_belegt" 3 "Gurtwarnung_Sitz_belegt" ;
VAL_ 1349 AbstWarn_MV_FAS_Fkt_Status 0 "Init" 1 "Funktion_Ist_Ein" 2 "Funktion_Ist_Aus" 3 "Fehler" ;
VAL_ 1349 WarnBrems_Charisma_Status 0 "Init" 1 "verfügbar" 2 "nicht verfügbar" 3 "asynchron durch Fahrerwunsch" ;
VAL_ 1349 WarnBrems_Charisma_FahrPr 0 "keine_Funktion" 1 "Programm_1" 2 "Programm_2" 3 "Programm_3" 4 "Programm_4" 5 "Programm_5" 6 "Programm_6" 7 "Programm_7" 8 "Programm_8" 9 "Programm_9" 10 "Programm_10" 11 "Programm_11" 12 "Programm_12" 13 "Programm_13" 14 "Programm_14" 15 "Programm_15" ;
VAL_ 1349 AB_Gurtwarn_Reihe2_MI 0 "nicht_verbaut" 1 "keine_Gurtwarnung_Sitz_leer" 2 "keine_Gurtwarnung_Sitz_belegt" 3 "Gurtwarnung_Sitz_belegt" ;
VAL_ 1349 AB_Gurtwarn_Reihe3_FA 0 "nicht_verbaut" 1 "keine_Gurtwarnung_Sitz_leer" 2 "keine_Gurtwarnung_Sitz_belegt" 3 "Gurtwarnung_Sitz_belegt" ;
VAL_ 1349 AB_Gurtwarn_Reihe3_MI 0 "nicht_verbaut" 1 "keine_Gurtwarnung_Sitz_leer" 2 "keine_Gurtwarnung_Sitz_belegt" 3 "Gurtwarnung_Sitz_belegt" ;
VAL_ 1349 AB_Gurtwarn_Reihe3_BF 0 "nicht_verbaut" 1 "keine_Gurtwarnung_Sitz_leer" 2 "keine_Gurtwarnung_Sitz_belegt" 3 "Gurtwarnung_Sitz_belegt" ;
VAL_ 1349 LGI_FAS_Fkt_Status 0 "Init" 1 "Funktion_Ist_Ein" 2 "Funktion_Ist_Aus" 3 "Fehler" ;
VAL_ 1349 PreCrash_FAS_Fkt_Status 0 "Init" 1 "Funktion_Ist_Ein" 2 "Funktion_Ist_Aus" 3 "Fehler" ;
VAL_ 1349 AB_Belegung_VF_ext 0 "nicht_verbaut" 1 "reserviert" 2 "nicht_belegt" 3 "belegt" 4 "dauerhaft_nicht_belegt" 5 "dauerhaft_belegt" 6 "Init" 7 "Fehler" ;
VAL_ 1349 AB_SBR_hinten_verbau 0 "ohne_SBR_hinten" 1 "mit_SBR_hinten" 2 "nicht_definiert" 3 "Init" ;
VAL_ 1349 AB_Belegung_VF_ext_aktiv 0 "inaktiv" 1 "aktiv" ;
VAL_ 1349 AWV_Einstellung_System_ASG 0 "deaktiviert" 1 "aktiviert" ;
VAL_ 1349 AWV_Einstellung_Warnung_ASG 0 "Aus" 1 "Setting_2" 2 "Setting_3" 3 "Setting_4" 4 "Setting_5" 5 "Ein" ;
VAL_ 1349 SC_PreSense_Modus_Warnung_NV 0 "Aus" 1 "Setting_2" 2 "Setting_3" 3 "Setting_4" 4 "Setting_5" 5 "Ein" ;
VAL_ 1349 SC_PreSense_Modus_Warnung_MV 0 "Aus" 1 "Setting_2" 2 "Setting_3" 3 "Setting_4" 4 "Setting_5" 5 "Ein" ;
VAL_ 1349 SC_PreSense_Modus_System_MV 0 "deaktiviert" 1 "aktiviert" ;
VAL_ 1349 SC_PreSense_Modus_System_NV 0 "deaktiviert" 1 "aktiviert" ;
VAL_ 1349 SC_PreSense_Modus_System_KAS 0 "deaktiviert" 1 "aktiviert" ;
VAL_ 1633 AAG_AVS_Fehler_02_inv 0 "Fehler" 1 "kein_Fehler" ;
VAL_ 1633 AAG_Bremsl_durch_ECD 0 "Bremslicht_ist_aus" 1 "Bremslicht_durch_ECD_aktiv" ;
VAL_ 1633 AAG_Anhaenger_abgesteckt 1 "Anhaenger_wurde_bei_KL15_aus_abgesteckt" ;
VAL_ 1633 AAG_NSL_aktiv 0 "Init" 1 "Anhaenger_Nebelschusslicht_aktiv" ;
VAL_ 1633 AAG_Anhaenger_erkannt 0 "kein_Anhaenger_erkannt" 1 "AAG_Anhaenger_erkannt" ;
VAL_ 1633 AAG_Blinker_H_aktiv 0 "Init" 1 "Anhaenger_Blinker_aktiv" ;
VAL_ 1633 AAG_Blinker_HL_def 0 "Init" 1 "Anhaenger_Blinker_links_defekt" ;
VAL_ 1633 AAG_Blinker_HR_def 0 "Init" 1 "Anhaenger_Blinker_rechts_defekt" ;
VAL_ 1633 AAG_Bremslicht_H_def 0 "Init" 1 "Anhaenger_Bremslicht_defekt" ;
VAL_ 1633 AAG_Schlusslicht_HL_def 0 "Init" 1 "Anhaenger_Schlusslicht_links_defekt" ;
VAL_ 1633 AAG_Schlusslicht_HR_def 0 "Init" 1 "Anhaenger_Schlusslicht_rechts_defekt" ;
VAL_ 1633 AAG_Bremslicht_Reku 0 "inaktiv" 1 "aktiv" ;
VAL_ 1633 AAG_AVS_Fehler_02 0 "kein_Fehler" 1 "Fehler" ;
VAL_ 1633 AAG_LED_aktiv 0 "Lampen" 1 "LED" ;
VAL_ 1633 AAG_AVS_Stati 0 "endlage_eingefahren_erreicht" 1 "endlage_ausgefahren_erreicht" 2 "ausfahren_automatik" 3 "einfahren_automatik" 4 "ausfahren_manuell" 5 "einfahren_manuell" 6 "zwischenposition" 7 "nicht_initialisiert" ;
VAL_ 345 ARA_Knickwinkel_Konfidenz 126 "Init" 127 "Fehler" ;
VAL_ 345 ARA_Texte 0 "kein Text/Akustik" 63 "Fehler" ;
VAL_ 345 ARA_Modus 0 "Knickwinkelmodus" 1 "Trajektorienmodus" ;
VAL_ 345 ARA_Aktiver_Grafikmodus 0 "keine_Grafik" 1 "Grafikmodus_aktiv" ;
VAL_ 345 ARA_Deaktivierung_sperren 0 "nicht_gesperrt" 1 "gesperrt" ;
VAL_ 345 ARA_Modus_Anf 0 "ARA Modus nicht im TSG angefordert" 1 "ARA Modus im TSG angefordert" ;
VAL_ 345 ARA_Bremsfuss 0 "kein Bremsfuss" 1 "Bremsfuss angefordert" ;
VAL_ 345 ARA_Sensor_Aktivierung 0 "Knickwinkelsensor_deaktivieren" 1 "Knickwinkelsensor_aktivieren" ;
VAL_ 345 ARA_Knickwinkel_Komfort 62 "Init" 63 "Fehler" ;
VAL_ 345 ARA_Status 0 "ARA_Status_inaktiv" 1 "ARA_Status_init" 2 "Fehler" 3 "ARA_Status_Start" 4 "ARA_Status_aktiv" 6 "ARA_Status_Regelung_aktiv" 8 "ARA_Status_betriebsbereit" 9 "ARA_Status_Klemmtraeger_erkannt" 10 "ARA_Status_Abbruch" 11 "ARA_Status_nicht_betriebsbereit" ;
VAL_ 345 ARA_Knickwinkel_Max 126 "Init" 127 "Fehler" ;
VAL_ 345 ARA_Knickwinkel_Soll 254 "Init" 255 "Fehler" ;
VAL_ 345 ARA_Knickwinkel_Ist 254 "Init" 255 "Fehler" ;
VAL_ 1626 BCM_Bremsbelag_Sensor 0 "OK" 1 "Bremsbelag_unter_min" ;
VAL_ 1626 BCM_Bremsfluessigkeit_Sensor 0 "OK" 1 "Bremsfluessigkeit_unter_min" ;
VAL_ 1626 BCM1_Licht_Warn 0 "OK" 1 "Lichtwarnung_aktiv" ;
VAL_ 1626 BCM_Waschwasser_Sensor 0 "OK" 1 "Waschwasser_unter_min" ;
VAL_ 1626 BCM_Kuehlmittel_Sensor 0 "OK" 1 "Kuehlmittel_unter_min" ;
VAL_ 1626 BCM1_Kl_15_HW_erkannt 1 "Klemme 15 erkannt" ;
VAL_ 1626 BCM1_Kl_15_Sig_HW_erkannt 0 "KL15_HW_Signal_von_BCM1_nicht_erkannt" 1 "KL15_HW_Signal_von_BCM1_erkannt" ;
VAL_ 1626 BCM_Kuehlmittel_Sensor_02 0 "OK" 1 "Kuehlmittel_unter_min" ;
VAL_ 1626 BCM1_Hinweis_Lichtnachlauf 0 "inaktiv" 1 "aktiv" ;
VAL_ 1626 BCM_Offroad_Taste 0 "Taster_nicht_betaetigt" 1 "Taster_betaetigt" ;
VAL_ 1626 BCM_Charisma_Taste2 0 "nicht_betaetigt" 1 "betaetigt" ;
VAL_ 1626 BCM_Hybrid_StSt_Taste_Fehler 0 "kein_Fehler_StSt_Taster" 1 "Fehler_StSt_Taster" ;
VAL_ 1626 BCM_Hybrid_StartStopp_Taste 0 "nicht_betaetigt" 1 "betaetigt" ;
VAL_ 1626 BCM1_Warnblink_Taster 0 "nicht_betaetigt" 1 "betaetigt" ;
VAL_ 1626 BCM1_Valet_Parking_Taster 0 "nicht_betaetigt" 1 "betaetigt" ;
VAL_ 1626 BCM1_LDS_Stellung 0 "Init" 1 "Stellung_0" 2 "Auto" 3 "Standlicht" 4 "Abblendlicht" 7 "Fehler" ;
VAL_ 1626 BCM1_Rueckfahrlicht_Schalter 0 "nicht_betaetigt" 1 "betaetigt" ;
VAL_ 1626 BCM1_MH_Schalter 0 "MH_geschlossen" 1 "MH_offen" ;
VAL_ 1626 BCM1_MH_WIV_Schalter 0 "MH_geschlossen" 1 "MH_offen" ;
VAL_ 1626 BCM_Eco_Charisma_Taste 0 "nicht_betaetigt" 1 "betaetigt" ;
VAL_ 1626 BCM1_NV_Taster 0 "Taster_nicht_betaetigt" 1 "Taster_betaetigt" ;
VAL_ 1626 BCM1_AFS_Lampe 0 "Aus" 1 "Ein" ;
VAL_ 1626 BCM1_Reisemodus_Texte 0 "keine_Anzeige" 1 "Umschaltung_auf_Linksverkehr_aktiv" 2 "Umschaltung_auf_Rechtsverkehr_aktiv" ;
VAL_ 1626 BCM1_Lichtwarn_Texte 0 "keine_Warnung" 1 "Standlichtwarnung" 2 "Parklichtwarnung" 3 "Nebelschlusslichtwarnung" ;
VAL_ 1626 Gong_TFL_Umschaltung 0 "kein_Gong" 1 "Gong_einmalig" ;
VAL_ 1626 BCM_ValetTaster_Fkts_LED 0 "LED_aus" 1 "LED_ein" ;
VAL_ 1626 LRH_Taster 0 "nicht_betaetigt" 1 "betaetigt" ;
VAL_ 1626 APS_Tongeber_defekt 0 "iO" 1 "defekt" ;
VAL_ 1626 BCM1_EasyEntry_Status 0 "Aus" 1 "Ein" ;
VAL_ 1626 BCM1_Lenksaeule_aktiv 0 "Lenksaeulenverstellung nicht aktiv" 1 "Lenksaeulenverstellung aktiv" ;
VAL_ 1626 BCM1_Spannungs_Anf 0 "keine_Anforderung" 1 "Anforderung_Stufe_1" 2 "Anforderung_Stufe_2" 3 "Anforderung_Stufe_3" ;
VAL_ 1626 DWA_Alarmquelle 0 "kein_Ausloesegrund" 1 "Tuerkontakt_Fahrertuer" 2 "Tuerkontakt_Beifahrertuer" 3 "Tuerkontakt_hinten_links" 4 "Tuerkontakt_hinten_rechts" 5 "Motorhaubenkontakt_vorne" 6 "Kofferraum_hinten" 7 "Masseschleife_der_Heckscheibe" 8 "Innenraumueberwachung" 9 "Alarm_durch_Noteinstieg" 10 "Sounder" 11 "Neigungssensor" 12 "TSG_FT_am_CAN_Bus" 13 "TSG_BT_am_CAN_Bus" 14 "TSG_HFS_am_CAN_Bus" 15 "TSG_HBFS_am_CAN_Bus" 16 "Klemme_15" 17 "Klemme_15sig" 18 "frei" 19 "Anhaengerueberwachung" 20 "Scheinwerferueberwachung_links" 21 "Scheinwerferueberwachung_rechts" 22 "Handschuhkasten" 23 "Verdeckueberwachung" 24 "OBD_Alarm" 25 "Power_on_Reset" 30 "Init" 31 "Fehler" ;
VAL_ 1626 DWA_Einschraenkung 0 "Init" 1 "Fehler" ;
VAL_ 1626 BCM_HBFS_EOE_aktiv 0 "EOE_inaktiv" 1 "EOE_aktiv" ;
VAL_ 1626 BCM_HFS_EOE_aktiv 0 "EOE_inaktiv" 1 "EOE_aktiv" ;
VAL_ 1626 BCM_Anf_AAW_MoLaWa 0 "Init" 1 "AAW_angefordert" 2 "MoLaWa_angefordert" ;
VAL_ 1626 BCM_Handbremse_Hinweis 0 "inaktiv" 1 "aktiv" ;
VAL_ 1626 BCM_Waehlhebel_P_Hinweis 0 "inaktiv" 1 "aktiv" ;
VAL_ 1626 BCM1_Fahrlicht_Hinweis 0 "kein_Fahrlicht_Hinweis" 1 "Fahrlicht_Hinweis" ;
VAL_ 1626 BCM_HDF_betaetigt 0 "nicht_betaetigt" 1 "betaetigt" ;
VAL_ 869 BEM_UBDM 0 "Init" 255 "Fehler" ;
VAL_ 869 NVEM_Ladefreigabe 0 "kein_Freigabe" 1 "Freigabe_Stufe_1" 2 "Freigabe_Stufe_2" 3 "Uneingeschraenkte_Freigabe" ;
VAL_ 869 NVEM_FMAus_Info 0 "Motorlauf_langfristig_nicht_notwendig_FMAus_Freigabe" 1 "Motoranlauf_nicht_zwingend_notwendig_Stoppverbot_keine_Startanforderung" 2 "Motoranlauf_zwingend_notwendig_Startanforderung" 3 "Systemfehler" ;
VAL_ 869 NVEM_PTC_Sollstufe 0 "Aus" 1 "Stufe_1" 2 "Stufe_2" 3 "Stufe_3" ;
VAL_ 869 NVEM_P_Generator_Status 0 "gefiltert" 1 "ungefiltert" ;
VAL_ 869 BEM_P_Generator 255 "Fehler" ;
VAL_ 869 BEM_n_LLA 0 "keine_Erhoehung" 1 "Stufe_1" 2 "Stufe_2" 3 "Stufe_3" ;
VAL_ 869 NVEM_Abschaltstufe 0 "Stufe_0_keine_Einschraenkung" 1 "Stufe_1" 2 "Stufe_2" 3 "Stufe_3" ;
VAL_ 869 BEM_Anf_KL 0 "keine Anforderung" 1 "Anforderung Kühlerlüfter Ansteuerung" ;
VAL_ 869 BEM_StartStopp_Info 0 "Motorlauf_nicht_notwendig_(Stoppfreigabe)" 1 "Motoranlauf_nicht_zwingend_notwendig_(Stoppverbot,keine_Startanforderung)" 2 "Motoranlauf_zwingend_notwendig_(Startanforderung)" 3 "Systemfehler" ;
VAL_ 869 BEM_EMLIN_ungueltig 0 "Signale_gueltig" 1 "Signale_ungueltig" ;
VAL_ 869 BEM_Batt_Ab 0 "verbunden" 1 "nicht_verbunden" ;
VAL_ 869 NVEM_FMAus_I_Verbrauch 30 "Init" 31 "Fehler" ;
VAL_ 869 NVEM_Freilauf_Info 0 "Freilauf_freigegeben" 1 "Weiches_Veto_uebertippbar" 2 "Hartes_Veto_Abbruch" 3 "Freilauf_Anforderung" ;
VAL_ 869 NVEM_Red_KL 0 "Init" 1 "Abschaltung_KL" 2 "Reduzierung_KL" ;
VAL_ 869 BEM_Segel_Info 0 "keine_Anforderung" 1 "Mindestdrehzahl_1" 2 "Mindestdrehzahl_2" 3 "Segelveto" ;
VAL_ 869 BEM_HYB_DC_uMinLV 254 "Init" 255 "Fehler" ;
VAL_ 1163 NVEM_Betriebsart 0 "oKl15_Sing_oVerbr" 1 "oKl15_Red_RedKontingent_oVerbr" 2 "oKl15_Red_HohKontingent_oVerbr" 3 "oKl15_Red_mVerbr" 4 "reserved" 5 "reserved" 6 "reserved" 7 "reserved" 8 "mKl15_Sing_oVerbr" 9 "mKl15_Red_RedKontingent_oVerbr" 10 "mKl15_Red_HohKontingent_oVerbr" 11 "mKl15_Red_mVerbr" 12 "Fahrbereitschaft_mVerbr" 13 "reserved" 14 "reserved" 15 "Fehler" ;
VAL_ 1163 NVEM_Ladezustand 126 "INIT" 127 "Fehler" ;
VAL_ 1163 NVEM2_Status_FuSiFahrt 0 "Init" 1 "Keine_FuSi_Fahrt" 2 "Qualifikation_FuSi_Fahrt" 3 "FuSi_Fahrt_Aktiv" 4 "Qualifikation_Ende_FuSi_Fahrt" 5 "FuSi_Stand" 6 "FuSi_Nachlauf" 7 "Fehler" ;
VAL_ 1163 NVEM_Energienetz_Status 0 "QM" 1 "ASIL_A" 2 "ASIL_B" 3 "ASIL_C" 6 "InitWert" 7 "Fehler" ;
VAL_ 1163 NVEM_Vorgabe_Leistungsstufe 0 "Init" 1 "Leistungsstufe_0" 2 "Leistungsstufe_1" 3 "Leistungsstufe_2" 4 "Leistungsstufe_3" 5 "Leistungsstufe_4" 6 "Leistungsstufe_5" 7 "Fehler" ;
VAL_ 1163 NVEM2_Typ_EnergieNetz 0 "Sp12V_Gen_ICE" 1 "Sp12V_BEV" 2 "Sp12V_PHEV" 3 "Sp12V_MHEV" 4 "Sp12V_HEV" 5 "Sp12V_Sp48V_Gen_Insel" 6 "Sp12V_Sp12V_RSG_MHEV12V" 7 "Sp12V_BEV_ASILC" 14 "Fehler" 15 "Init" ;
VAL_ 1163 NVEM_Energie_Klima_Vorgabe 254 "Init" 255 "Fehler" ;
VAL_ 1163 NVEM_Last_Anf 0 "keine Anforderung" 1 "Verbraucher_Anforderung_Stufe_1" 2 "Verbraucher_Anforderung_Stufe_2" 3 "Verbraucher_Anforderung_Stufe_3" ;
VAL_ 1163 NVEM_STH_ZielzeitLang 14 "Init" 15 "Fehler" ;
VAL_ 1163 NVEM_Red_KomfortVerbrauch 0 "keine_Einschraenkung" 1 "Einschraenkung_Stufe_1" 2 "Einschraenkung_Stufe_2" 3 "Einschraenkung_Stufe_3" 4 "Einschraenkung_Stufe_4" 5 "Einschraenkung_Stufe_5" 6 "Einschraenkung_Stufe_6" 7 "Einschraenkung_Stufe_7" 8 "Einschraenkung_Stufe_8" 15 "Fehler" ;
VAL_ 1163 NVEM_PTC_Sollstufe 0 "Aus" 1 "Stufe_1" 2 "Stufe_2" 3 "Stufe_3" ;
VAL_ 1163 NVEM_Bordnetzdiagnose 0 "kein_Fehler" 1 "Warnung_1" 2 "Warnung_2" 3 "Warnung_3" ;
VAL_ 1163 HLR_PTC_linear_Freigabe 63 "Fehler" ;
VAL_ 2463978850 NVEM_Bordnetz_Information 0 "keine_Anzeige" 1 "NV_Batterie_iO" 2 "NV_Batterie_laden" 3 "NV_Batterie_pruefen" 4 "NV_Batterie_schwach" 5 "NV_Batterie_Ab" 6 "NV_Batterie_Service" 7 "NV_Energiesystem_unplausibel" 8 "Ladekontrollleuchte" 9 "Generator_defekt" 10 "reserviert" 11 "reserviert" 12 "reserviert" 13 "reserviert" 14 "Init" 15 "Fehler" ;
VAL_ 2463978850 NVEM_Verbraucher_Information 0 "Keine_Anzeige" 1 "MMI_Vorwarnung" 2 "Anzeige_Verbraucherabschaltung" 3 "reserviert" 4 "reserviert" 5 "reserviert" 6 "Init" 7 "Fehler" ;
VAL_ 2463978850 NVEM2_VerbrZustandsAnf 0 "Freigabe" 1 "Verbraucher_Sperren" 2 "Verbr_Sperren_KL_Red" 3 "reserved" 4 "reserved" 5 "reserved" 6 "Verbr_Sperren_KL_Anf" 7 "Teilweise_Anschalt_Anf" 8 "Anschalt_Anf" 9 "reserved" 10 "reserved" 11 "Abschaltstufe_1" 12 "Abschaltstufe_2" 13 "Abschaltstufe_3" 14 "Init" 15 "Fehler" ;
VAL_ 2463978850 NVEM_NVStuetzungAnf 0 "keine_Anforderung" 1 "Anforderung_sichere_Versorgung" 2 "Anforderung_Abschaltung" 3 "Fehler" ;
VAL_ 2463978850 NVEM3_Absch_SCR 0 "Init" 1 "Abschaltung_SCR" ;
VAL_ 2463978850 NVEM_Batt_Temp_Hinweis 0 "Keine_Anzeige" 1 "Hinweis_Aussenhuelle_zu" 2 "Hinweis_Klima_ein" 3 "Wunsch_Aussenhuelle_zu" 4 "Wunsch_Klima_ein" ;
VAL_ 1442 BMS_Fehler_Pilot 0 "geschlossen" 1 "Unterbrechung" ;
VAL_ 1442 BMS_Status_ServiceDisconnect 0 "gesteckt" 1 "gezogen" ;
VAL_ 1442 BMS_Status_Spgfreiheit 0 "Init" 1 "HV_Komponente_spannungsfrei" 2 "HV_Komp_nicht_spannungsfrei" 3 "Fehler_nicht_spannungsfrei" ;
VAL_ 1442 BMS_OBD_Lampe_Anf 0 "kein_MIL_Request" 1 "MIL_Request" ;
VAL_ 1442 BMS_Fehlerstatus 0 "Komponente_IO" 1 "Eingeschr_KompFkt_Isofehler_I" 2 "Eingeschr_KompFkt_Isofehler_II" 3 "Eingeschr_KompFkt_Interlock" 4 "Eingeschr_KompFkt_SD" 5 "Eingeschr_KompFkt_Leistungsred" 6 "Keine_Komponentenfunktion" 7 "Init" ;
VAL_ 1442 BMS_Kapazitaet_02 2047 "Init" ;
VAL_ 1442 BMS_Fehlerlampe_Anf 1 "RedLED_Request" ;
VAL_ 1442 BMS_Warnlampe_Anf 1 "YellowLED_Request" ;
VAL_ 1442 BMS_Kl30c_Status 0 "Init" 1 "geschlossen" 2 "offen" 3 "Fehler" ;
VAL_ 1482 BMS_Energieinhalt 2046 "Init" 2047 "Fehler" ;
VAL_ 1482 BMS_Ladevorgang_aktiv 0 "inaktiv" 1 "aktiv" ;
VAL_ 1482 BMS_Batteriediagnose 1 "Anzeige_Batterie" 4 "Anzeige_Batterie_OK" 5 "Anzeige_Batterie_Laden" 6 "Anzeige_Batterie_Pruefen" 7 "Fehler" ;
VAL_ 1482 BMS_Balancing_Aktiv 0 "Init" 1 "aktiv" 2 "nicht_aktiv" ;
VAL_ 1482 BMS_MaxEnergieinhalt 2046 "Init" 2047 "Fehler" ;
VAL_ 1482 BMS_Ausgleichsladung_Anf 1 "Balancing_Request" ;
VAL_ 1482 BMS_Gesamtst_Spgfreiheit 0 "Funktion_nicht_aktiviert" 1 "HV_System_spannungsfrei" 2 "HV_System_nicht_spannungsfrei" 3 "Fehler_nicht_spannungsfrei" ;
VAL_ 1482 BMS_RIso_Ext 4094 "Init" 4095 "Fehler" ;
VAL_ 1482 BMS_KundenWarnung 0 "keine_Warnung" 1 "Warnung_Temperatur_Level1" 2 "Warnung_Temperatur_Level2" ;
VAL_ 2527679654 BMS_IsoZustand 0 "Init_kein_Diagnoseergebnis" 1 "groesser_Schwelle_1" 2 "kleiner_Schwelle_1_gesamt" 3 "kleiner_Schwelle_1_intern" 4 "kleiner_Schwelle_2_gesamt" 5 "kleiner_Schwelle_2_intern" 6 "kein_Messwert" 7 "Messung_aktiv" ;
VAL_ 2527679654 BMS_IsoFehler 0 "Init" 1 "kein_IsoFehler" 2 "IsoFehler_Schwelle_1" 3 "IsoFehler_Schwelle_2" 4 "IWU_defekt" 5 "reserviert" 6 "reserviert" 7 "reserviert" ;
VAL_ 2527679654 BMS_IstTemperatur_hoechste 253 "reserviert" 254 "Init" 255 "Fehler" ;
VAL_ 2527679654 BMS_IstTemperatur_niedrigste 253 "reserviert" 254 "Init" 255 "Fehler" ;
VAL_ 2527679654 BMS_IstZellspannung_hoechste 4092 "reserviert" 4093 "reserviert" 4094 "Init" 4095 "Fehler" ;
VAL_ 2527679654 BMS_IstZellspannung_niedrigste 4092 "reserviert" 4093 "reserviert" 4094 "Init" 4095 "Fehler" ;
VAL_ 207 BMS_Fehlerstatus_HV_Schuetze 0 "Init_kein_Diagnoseergebnis" 1 "kein_Schuetz_verschweisst" 2 "mind_1_Schuetz_verschweisst" 3 "Fehler_Schuetzstatuserkennung" ;
VAL_ 207 BMS_ErwGrenzen_aktiv 0 "Init" 1 "extended_Range" ;
VAL_ 207 BMS_IstModus 0 "HV_inaktiv" 1 "Fahren_HV_aktiv" 2 "stBalancing" 3 "externes_Laden" 4 "AC_Laden" 5 "Error_Batt" 6 "DC_Laden" 7 "Init" ;
VAL_ 207 BMS_HVIL_Status 0 "Init" 1 "geschlossen" 2 "offen" 3 "Fehler" ;
VAL_ 207 BMS_Fehler_HVBattAbschaltung 1 "Err_ShutOff" ;
VAL_ 207 BMS_Fehler_HVBattAbschaltung_Anf 1 "Err_ShutOffRequest" ;
VAL_ 207 BMS_Fehler_Leistungsred 0 "keine_Leistungseinschraenkung" 1 "Leistungseinschraenkung" ;
VAL_ 207 BMS_Strom 32765 "nicht_messbar" 32766 "Init" 32767 "Fehler" ;
VAL_ 207 BMS_Fehler_Notabschaltung_Crash 1 "Err_EmergcyShtOffCrash" ;
VAL_ 207 BMS_Spannung_Zwischenkreis 4093 "nicht_messbar" 4094 "Init" 4095 "Fehler" ;
VAL_ 207 BMS_Spannung 4093 "nicht_messbar" 4094 "Init" 4095 "Fehler" ;
VAL_ 2463978704 BMS_Max_Entladestrom 8190 "Init" ;
VAL_ 2463978704 BMS_Max_Ladestrom 8190 "Init" ;
VAL_ 2463978704 BMS_Max_Entladeleistung 8190 "Init" ;
VAL_ 2463978704 BMS_Max_Ladeleistung 8190 "Init" ;
